VERSION "dbc-export 1 2025.20.8"

NS_ :

BS_:

BU_: ADSP APSB BB BMS CMP CP DAS DI DIF DIR DPB EPASTP EPASTS GTW ICR IDB OCS1P PM PMF PMR PTC RCM RCU TCU UI UIS VCLEFT VCSEC

BO_ 1428 EPASTS_alertLog: 8 EPASTS
 SG_ EPASTS_alertID M : 0|9@1+ (1,0) [0|511] "" Vector__XXX
 SG_ EPASTS_alertState : 15|1@1+ (1,0) [0|1] "" Vector__XXX
 SG_ EPASTS_a001_debugInfo m1 : 16|48@1+ (1,0) [0|281474976710655] "" Vector__XXX
 SG_ EPASTS_a002_debugInfo m2 : 16|48@1+ (1,0) [0|281474976710655] "" Vector__XXX
 SG_ EPASTS_a003_debugInfo m3 : 16|48@1+ (1,0) [0|281474976710655] "" Vector__XXX
 SG_ EPASTS_a004_debugInfo m4 : 16|48@1+ (1,0) [0|281474976710655] "" Vector__XXX
 SG_ EPASTS_a005_debugInfo m5 : 16|48@1+ (1,0) [0|281474976710655] "" Vector__XXX
 SG_ EPASTS_a006_debugInfo m6 : 16|48@1+ (1,0) [0|281474976710655] "" Vector__XXX
 SG_ EPASTS_a007_debugInfo m7 : 16|48@1+ (1,0) [0|281474976710655] "" Vector__XXX
 SG_ EPASTS_a009_debugInfo m9 : 16|48@1+ (1,0) [0|281474976710655] "" Vector__XXX
 SG_ EPASTS_a010_debugInfo m10 : 16|48@1+ (1,0) [0|281474976710655] "" Vector__XXX
 SG_ EPASTS_a011_debugInfo m11 : 16|48@1+ (1,0) [0|281474976710655] "" Vector__XXX
 SG_ EPASTS_a012_debugInfo m12 : 16|48@1+ (1,0) [0|281474976710655] "" Vector__XXX
 SG_ EPASTS_a013_debugInfo m13 : 16|48@1+ (1,0) [0|281474976710655] "" Vector__XXX
 SG_ EPASTS_a014_debugInfo m14 : 16|48@1+ (1,0) [0|281474976710655] "" Vector__XXX
 SG_ EPASTS_a015_debugInfo m15 : 16|48@1+ (1,0) [0|281474976710655] "" Vector__XXX
 SG_ EPASTS_a016_debugInfo m16 : 16|48@1+ (1,0) [0|281474976710655] "" Vector__XXX
 SG_ EPASTS_a017_debugInfo m17 : 16|48@1+ (1,0) [0|281474976710655] "" Vector__XXX
 SG_ EPASTS_a018_debugInfo m18 : 16|48@1+ (1,0) [0|281474976710655] "" Vector__XXX
 SG_ EPASTS_a019_debugInfo m19 : 16|48@1+ (1,0) [0|281474976710655] "" Vector__XXX
 SG_ EPASTS_a020_debugInfo m20 : 16|48@1+ (1,0) [0|281474976710655] "" Vector__XXX
 SG_ EPASTS_a021_debugInfo m21 : 16|48@1+ (1,0) [0|281474976710655] "" Vector__XXX
 SG_ EPASTS_a022_debugInfo m22 : 16|48@1+ (1,0) [0|281474976710655] "" Vector__XXX
 SG_ EPASTS_a023_debugInfo m23 : 16|48@1+ (1,0) [0|281474976710655] "" Vector__XXX
 SG_ EPASTS_a024_debugInfo m24 : 16|48@1+ (1,0) [0|281474976710655] "" Vector__XXX
 SG_ EPASTS_a025_debugInfo m25 : 16|48@1+ (1,0) [0|281474976710655] "" Vector__XXX
 SG_ EPASTS_a026_debugInfo m26 : 16|48@1+ (1,0) [0|281474976710655] "" Vector__XXX
 SG_ EPASTS_a027_debugInfo m27 : 16|48@1+ (1,0) [0|281474976710655] "" Vector__XXX
 SG_ EPASTS_a028_debugInfo m28 : 16|48@1+ (1,0) [0|281474976710655] "" Vector__XXX
 SG_ EPASTS_a029_debugInfo m29 : 16|48@1+ (1,0) [0|281474976710655] "" Vector__XXX
 SG_ EPASTS_a030_debugInfo m30 : 16|48@1+ (1,0) [0|281474976710655] "" Vector__XXX
 SG_ EPASTS_a031_debugInfo m31 : 16|48@1+ (1,0) [0|281474976710655] "" Vector__XXX
 SG_ EPASTS_a032_debugInfo m32 : 16|48@1+ (1,0) [0|281474976710655] "" Vector__XXX
 SG_ EPASTS_a033_debugInfo m33 : 16|48@1+ (1,0) [0|281474976710655] "" Vector__XXX
 SG_ EPASTS_a034_debugInfo m34 : 16|48@1+ (1,0) [0|281474976710655] "" Vector__XXX
 SG_ EPASTS_a035_debugInfo m35 : 16|48@1+ (1,0) [0|281474976710655] "" Vector__XXX
 SG_ EPASTS_a036_debugInfo m36 : 16|48@1+ (1,0) [0|281474976710655] "" Vector__XXX
 SG_ EPASTS_a037_debugInfo m37 : 16|48@1+ (1,0) [0|281474976710655] "" Vector__XXX
 SG_ EPASTS_a038_debugInfo m38 : 16|48@1+ (1,0) [0|281474976710655] "" Vector__XXX
 SG_ EPASTS_a039_debugInfo m39 : 16|48@1+ (1,0) [0|281474976710655] "" Vector__XXX
 SG_ EPASTS_a040_debugInfo m40 : 16|48@1+ (1,0) [0|281474976710655] "" Vector__XXX
 SG_ EPASTS_a041_debugInfo m41 : 16|48@1+ (1,0) [0|281474976710655] "" Vector__XXX
 SG_ EPASTS_a042_debugInfo m42 : 16|48@1+ (1,0) [0|281474976710655] "" Vector__XXX
 SG_ EPASTS_a043_debugInfo m43 : 16|48@1+ (1,0) [0|281474976710655] "" Vector__XXX
 SG_ EPASTS_a044_debugInfo m44 : 16|48@1+ (1,0) [0|281474976710655] "" Vector__XXX
 SG_ EPASTS_a045_debugInfo m45 : 16|48@1+ (1,0) [0|281474976710655] "" Vector__XXX
 SG_ EPASTS_a046_debugInfo m46 : 16|48@1+ (1,0) [0|281474976710655] "" Vector__XXX
 SG_ EPASTS_a047_debugInfo m47 : 16|48@1+ (1,0) [0|281474976710655] "" Vector__XXX
 SG_ EPASTS_a048_debugInfo m48 : 16|48@1+ (1,0) [0|281474976710655] "" Vector__XXX
 SG_ EPASTS_a049_debugInfo m49 : 16|48@1+ (1,0) [0|281474976710655] "" Vector__XXX
 SG_ EPASTS_a050_debugInfo m50 : 16|48@1+ (1,0) [0|281474976710655] "" Vector__XXX
 SG_ EPASTS_a051_debugInfo m51 : 16|48@1+ (1,0) [0|281474976710655] "" Vector__XXX
 SG_ EPASTS_a052_debugInfo m52 : 16|48@1+ (1,0) [0|281474976710655] "" Vector__XXX
 SG_ EPASTS_a053_debugInfo m53 : 16|48@1+ (1,0) [0|281474976710655] "" Vector__XXX
 SG_ EPASTS_a054_debugInfo m54 : 16|48@1+ (1,0) [0|281474976710655] "" Vector__XXX
 SG_ EPASTS_a055_debugInfo m55 : 16|48@1+ (1,0) [0|281474976710655] "" Vector__XXX
 SG_ EPASTS_a056_debugInfo m56 : 16|48@1+ (1,0) [0|281474976710655] "" Vector__XXX
 SG_ EPASTS_a057_debugInfo m57 : 16|48@1+ (1,0) [0|281474976710655] "" Vector__XXX
 SG_ EPASTS_a058_debugInfo m58 : 16|48@1+ (1,0) [0|281474976710655] "" Vector__XXX
 SG_ EPASTS_a059_debugInfo m59 : 16|48@1+ (1,0) [0|281474976710655] "" Vector__XXX
 SG_ EPASTS_a060_debugInfo m60 : 16|48@1+ (1,0) [0|281474976710655] "" Vector__XXX
 SG_ EPASTS_a061_debugInfo m61 : 16|48@1+ (1,0) [0|281474976710655] "" Vector__XXX
 SG_ EPASTS_a062_debugInfo m62 : 16|48@1+ (1,0) [0|281474976710655] "" Vector__XXX
 SG_ EPASTS_a063_debugInfo m63 : 16|48@1+ (1,0) [0|281474976710655] "" Vector__XXX
 SG_ EPASTS_a064_debugInfo m64 : 16|48@1+ (1,0) [0|281474976710655] "" Vector__XXX
 SG_ EPASTS_a065_debugInfo m65 : 16|48@1+ (1,0) [0|281474976710655] "" Vector__XXX
 SG_ EPASTS_a066_debugInfo m66 : 16|48@1+ (1,0) [0|281474976710655] "" Vector__XXX
 SG_ EPASTS_a067_debugInfo m67 : 16|48@1+ (1,0) [0|281474976710655] "" Vector__XXX
 SG_ EPASTS_a068_debugInfo m68 : 16|48@1+ (1,0) [0|281474976710655] "" Vector__XXX
 SG_ EPASTS_a069_debugInfo m69 : 16|48@1+ (1,0) [0|281474976710655] "" Vector__XXX
 SG_ EPASTS_a070_debugInfo m70 : 16|48@1+ (1,0) [0|281474976710655] "" Vector__XXX
 SG_ EPASTS_a071_debugInfo m71 : 16|48@1+ (1,0) [0|281474976710655] "" Vector__XXX
 SG_ EPASTS_a072_debugInfo m72 : 16|48@1+ (1,0) [0|281474976710655] "" Vector__XXX
 SG_ EPASTS_a073_debugInfo m73 : 16|48@1+ (1,0) [0|281474976710655] "" Vector__XXX
 SG_ EPASTS_a074_debugInfo m74 : 16|48@1+ (1,0) [0|281474976710655] "" Vector__XXX
 SG_ EPASTS_a075_debugInfo m75 : 16|48@1+ (1,0) [0|281474976710655] "" Vector__XXX
 SG_ EPASTS_a076_debugInfo m76 : 16|48@1+ (1,0) [0|281474976710655] "" Vector__XXX
 SG_ EPASTS_a077_debugInfo m77 : 16|48@1+ (1,0) [0|281474976710655] "" Vector__XXX
 SG_ EPASTS_a078_debugInfo m78 : 16|48@1+ (1,0) [0|281474976710655] "" Vector__XXX
 SG_ EPASTS_a079_debugInfo m79 : 16|48@1+ (1,0) [0|281474976710655] "" Vector__XXX
 SG_ EPASTS_a080_debugInfo m80 : 16|48@1+ (1,0) [0|281474976710655] "" Vector__XXX
 SG_ EPASTS_a081_debugInfo m81 : 16|48@1+ (1,0) [0|281474976710655] "" Vector__XXX
 SG_ EPASTS_a082_debugInfo m82 : 16|48@1+ (1,0) [0|281474976710655] "" Vector__XXX
 SG_ EPASTS_a083_debugInfo m83 : 16|48@1+ (1,0) [0|281474976710655] "" Vector__XXX
 SG_ EPASTS_a084_debugInfo m84 : 16|48@1+ (1,0) [0|281474976710655] "" Vector__XXX
 SG_ EPASTS_a085_debugInfo m85 : 16|48@1+ (1,0) [0|281474976710655] "" Vector__XXX
 SG_ EPASTS_a086_debugInfo m86 : 16|48@1+ (1,0) [0|281474976710655] "" Vector__XXX
 SG_ EPASTS_a087_debugInfo m87 : 16|48@1+ (1,0) [0|281474976710655] "" Vector__XXX
 SG_ EPASTS_a088_debugInfo m88 : 16|48@1+ (1,0) [0|281474976710655] "" Vector__XXX
 SG_ EPASTS_a089_debugInfo m89 : 16|48@1+ (1,0) [0|281474976710655] "" Vector__XXX
 SG_ EPASTS_a090_debugInfo m90 : 16|48@1+ (1,0) [0|281474976710655] "" Vector__XXX
 SG_ EPASTS_a091_debugInfo m91 : 16|48@1+ (1,0) [0|281474976710655] "" Vector__XXX
 SG_ EPASTS_a092_debugInfo m92 : 16|48@1+ (1,0) [0|281474976710655] "" Vector__XXX
 SG_ EPASTS_a093_debugInfo m93 : 16|48@1+ (1,0) [0|281474976710655] "" Vector__XXX
 SG_ EPASTS_a094_debugInfo m94 : 16|48@1+ (1,0) [0|281474976710655] "" Vector__XXX
 SG_ EPASTS_a095_debugInfo m95 : 16|48@1+ (1,0) [0|281474976710655] "" Vector__XXX
 SG_ EPASTS_a096_debugInfo m96 : 16|48@1+ (1,0) [0|281474976710655] "" Vector__XXX
 SG_ EPASTS_a097_debugInfo m97 : 16|48@1+ (1,0) [0|281474976710655] "" Vector__XXX
 SG_ EPASTS_a098_debugInfo m98 : 16|48@1+ (1,0) [0|281474976710655] "" Vector__XXX
 SG_ EPASTS_a099_debugInfo m99 : 16|48@1+ (1,0) [0|281474976710655] "" Vector__XXX
 SG_ EPASTS_a100_debugInfo m100 : 16|48@1+ (1,0) [0|281474976710655] "" Vector__XXX
 SG_ EPASTS_a101_debugInfo m101 : 16|48@1+ (1,0) [0|281474976710655] "" Vector__XXX
 SG_ EPASTS_a102_debugInfo m102 : 16|48@1+ (1,0) [0|281474976710655] "" Vector__XXX
 SG_ EPASTS_a103_debugInfo m103 : 16|48@1+ (1,0) [0|281474976710655] "" Vector__XXX
 SG_ EPASTS_a104_debugInfo m104 : 16|48@1+ (1,0) [0|281474976710655] "" Vector__XXX
 SG_ EPASTS_a105_debugInfo m105 : 16|48@1+ (1,0) [0|281474976710655] "" Vector__XXX
 SG_ EPASTS_a106_debugInfo m106 : 16|48@1+ (1,0) [0|281474976710655] "" Vector__XXX
 SG_ EPASTS_a107_debugInfo m107 : 16|48@1+ (1,0) [0|281474976710655] "" Vector__XXX
 SG_ EPASTS_a108_debugInfo m108 : 16|48@1+ (1,0) [0|281474976710655] "" Vector__XXX
 SG_ EPASTS_a109_debugInfo m109 : 16|48@1+ (1,0) [0|281474976710655] "" Vector__XXX
 SG_ EPASTS_a110_debugInfo m110 : 16|48@1+ (1,0) [0|281474976710655] "" Vector__XXX
 SG_ EPASTS_a111_debugInfo m111 : 16|48@1+ (1,0) [0|281474976710655] "" Vector__XXX
 SG_ EPASTS_a112_debugInfo m112 : 16|48@1+ (1,0) [0|281474976710655] "" Vector__XXX
 SG_ EPASTS_a113_debugInfo m113 : 16|48@1+ (1,0) [0|281474976710655] "" Vector__XXX
 SG_ EPASTS_a114_debugInfo m114 : 16|48@1+ (1,0) [0|281474976710655] "" Vector__XXX
 SG_ EPASTS_a115_debugInfo m115 : 16|48@1+ (1,0) [0|281474976710655] "" Vector__XXX
 SG_ EPASTS_a116_debugInfo m116 : 16|48@1+ (1,0) [0|281474976710655] "" Vector__XXX
 SG_ EPASTS_a117_debugInfo m117 : 16|48@1+ (1,0) [0|281474976710655] "" Vector__XXX
 SG_ EPASTS_a118_debugInfo m118 : 16|48@1+ (1,0) [0|281474976710655] "" Vector__XXX
 SG_ EPASTS_a119_debugInfo m119 : 16|48@1+ (1,0) [0|281474976710655] "" Vector__XXX
 SG_ EPASTS_a120_debugInfo m120 : 16|48@1+ (1,0) [0|281474976710655] "" Vector__XXX
 SG_ EPASTS_a121_debugInfo m121 : 16|48@1+ (1,0) [0|281474976710655] "" Vector__XXX
 SG_ EPASTS_a122_debugInfo m122 : 16|48@1+ (1,0) [0|281474976710655] "" Vector__XXX
 SG_ EPASTS_a123_debugInfo m123 : 16|48@1+ (1,0) [0|281474976710655] "" Vector__XXX
 SG_ EPASTS_a124_debugInfo m124 : 16|48@1+ (1,0) [0|281474976710655] "" Vector__XXX
 SG_ EPASTS_a125_debugInfo m125 : 16|48@1+ (1,0) [0|281474976710655] "" Vector__XXX
 SG_ EPASTS_a126_debugInfo m126 : 16|48@1+ (1,0) [0|281474976710655] "" Vector__XXX
 SG_ EPASTS_a127_debugInfo m127 : 16|48@1+ (1,0) [0|281474976710655] "" Vector__XXX
 SG_ EPASTS_a128_debugInfo m128 : 16|48@1+ (1,0) [0|281474976710655] "" Vector__XXX
 SG_ EPASTS_a129_debugInfo m129 : 16|48@1+ (1,0) [0|281474976710655] "" Vector__XXX
 SG_ EPASTS_a130_debugInfo m130 : 16|48@1+ (1,0) [0|281474976710655] "" Vector__XXX
 SG_ EPASTS_a131_debugInfo m131 : 16|48@1+ (1,0) [0|281474976710655] "" Vector__XXX
 SG_ EPASTS_a132_debugInfo m132 : 16|48@1+ (1,0) [0|281474976710655] "" Vector__XXX
 SG_ EPASTS_a133_debugInfo m133 : 16|48@1+ (1,0) [0|281474976710655] "" Vector__XXX
 SG_ EPASTS_a134_debugInfo m134 : 16|48@1+ (1,0) [0|281474976710655] "" Vector__XXX
 SG_ EPASTS_a135_debugInfo m135 : 16|48@1+ (1,0) [0|281474976710655] "" Vector__XXX
 SG_ EPASTS_a136_debugInfo m136 : 16|48@1+ (1,0) [0|281474976710655] "" Vector__XXX
 SG_ EPASTS_a137_debugInfo m137 : 16|48@1+ (1,0) [0|281474976710655] "" Vector__XXX
 SG_ EPASTS_a138_debugInfo m138 : 16|48@1+ (1,0) [0|281474976710655] "" Vector__XXX
 SG_ EPASTS_a139_debugInfo m139 : 16|48@1+ (1,0) [0|281474976710655] "" Vector__XXX
 SG_ EPASTS_a140_debugInfo m140 : 16|48@1+ (1,0) [0|281474976710655] "" Vector__XXX
 SG_ EPASTS_a141_debugInfo m141 : 16|48@1+ (1,0) [0|281474976710655] "" Vector__XXX
 SG_ EPASTS_a142_debugInfo m142 : 16|48@1+ (1,0) [0|281474976710655] "" Vector__XXX
 SG_ EPASTS_a143_debugInfo m143 : 16|48@1+ (1,0) [0|281474976710655] "" Vector__XXX
 SG_ EPASTS_a144_debugInfo m144 : 16|48@1+ (1,0) [0|281474976710655] "" Vector__XXX
 SG_ EPASTS_a145_debugInfo m145 : 16|48@1+ (1,0) [0|281474976710655] "" Vector__XXX
 SG_ EPASTS_a146_debugInfo m146 : 16|48@1+ (1,0) [0|281474976710655] "" Vector__XXX
 SG_ EPASTS_a147_debugInfo m147 : 16|48@1+ (1,0) [0|281474976710655] "" Vector__XXX
 SG_ EPASTS_a148_debugInfo m148 : 16|48@1+ (1,0) [0|281474976710655] "" Vector__XXX
 SG_ EPASTS_a149_debugInfo m149 : 16|48@1+ (1,0) [0|281474976710655] "" Vector__XXX
 SG_ EPASTS_a150_debugInfo m150 : 16|48@1+ (1,0) [0|281474976710655] "" Vector__XXX
 SG_ EPASTS_a152_debugInfo m152 : 16|48@1+ (1,0) [0|281474976710655] "" Vector__XXX
 SG_ EPASTS_a153_debugInfo m153 : 16|48@1+ (1,0) [0|281474976710655] "" Vector__XXX
 SG_ EPASTS_a154_debugInfo m154 : 16|48@1+ (1,0) [0|281474976710655] "" Vector__XXX
 SG_ EPASTS_a155_debugInfo m155 : 16|48@1+ (1,0) [0|281474976710655] "" Vector__XXX
 SG_ EPASTS_a156_debugInfo m156 : 16|48@1+ (1,0) [0|281474976710655] "" Vector__XXX
 SG_ EPASTS_a157_debugInfo m157 : 16|48@1+ (1,0) [0|281474976710655] "" Vector__XXX
 SG_ EPASTS_a158_debugInfo m158 : 16|48@1+ (1,0) [0|281474976710655] "" Vector__XXX
 SG_ EPASTS_a159_debugInfo m159 : 16|48@1+ (1,0) [0|281474976710655] "" Vector__XXX
 SG_ EPASTS_a160_debugInfo m160 : 16|48@1+ (1,0) [0|281474976710655] "" Vector__XXX
 SG_ EPASTS_a161_debugInfo m161 : 16|48@1+ (1,0) [0|281474976710655] "" Vector__XXX
 SG_ EPASTS_a162_debugInfo m162 : 16|48@1+ (1,0) [0|281474976710655] "" Vector__XXX
 SG_ EPASTS_a163_debugInfo m163 : 16|48@1+ (1,0) [0|281474976710655] "" Vector__XXX
 SG_ EPASTS_a164_debugInfo m164 : 16|48@1+ (1,0) [0|281474976710655] "" Vector__XXX
 SG_ EPASTS_a165_debugInfo m165 : 16|48@1+ (1,0) [0|281474976710655] "" Vector__XXX
 SG_ EPASTS_a166_debugInfo m166 : 16|48@1+ (1,0) [0|281474976710655] "" Vector__XXX
 SG_ EPASTS_a167_debugInfo m167 : 16|48@1+ (1,0) [0|281474976710655] "" Vector__XXX
 SG_ EPASTS_a168_debugInfo m168 : 16|48@1+ (1,0) [0|281474976710655] "" Vector__XXX
 SG_ EPASTS_a169_debugInfo m169 : 16|48@1+ (1,0) [0|281474976710655] "" Vector__XXX
 SG_ EPASTS_a170_debugInfo m170 : 16|48@1+ (1,0) [0|281474976710655] "" Vector__XXX
 SG_ EPASTS_a171_debugInfo m171 : 16|48@1+ (1,0) [0|281474976710655] "" Vector__XXX
 SG_ EPASTS_a172_debugInfo m172 : 16|48@1+ (1,0) [0|281474976710655] "" Vector__XXX
 SG_ EPASTS_a173_debugInfo m173 : 16|48@1+ (1,0) [0|281474976710655] "" Vector__XXX
 SG_ EPASTS_a174_debugInfo m174 : 16|48@1+ (1,0) [0|281474976710655] "" Vector__XXX
 SG_ EPASTS_a175_debugInfo m175 : 16|48@1+ (1,0) [0|281474976710655] "" Vector__XXX
 SG_ EPASTS_a176_debugInfo m176 : 16|48@1+ (1,0) [0|281474976710655] "" Vector__XXX
 SG_ EPASTS_a177_debugInfo m177 : 16|48@1+ (1,0) [0|281474976710655] "" Vector__XXX
 SG_ EPASTS_a178_debugInfo m178 : 16|48@1+ (1,0) [0|281474976710655] "" Vector__XXX
 SG_ EPASTS_a179_debugInfo m179 : 16|48@1+ (1,0) [0|281474976710655] "" Vector__XXX
 SG_ EPASTS_a180_debugInfo m180 : 16|48@1+ (1,0) [0|281474976710655] "" Vector__XXX
 SG_ EPASTS_a181_debugInfo m181 : 16|48@1+ (1,0) [0|281474976710655] "" Vector__XXX
 SG_ EPASTS_a182_debugInfo m182 : 16|48@1+ (1,0) [0|281474976710655] "" Vector__XXX
 SG_ EPASTS_a183_debugInfo m183 : 16|48@1+ (1,0) [0|281474976710655] "" Vector__XXX
 SG_ EPASTS_a184_debugInfo m184 : 16|48@1+ (1,0) [0|281474976710655] "" Vector__XXX
 SG_ EPASTS_a185_debugInfo m185 : 16|48@1+ (1,0) [0|281474976710655] "" Vector__XXX
 SG_ EPASTS_a186_debugInfo m186 : 16|48@1+ (1,0) [0|281474976710655] "" Vector__XXX
 SG_ EPASTS_a188_debugInfo m188 : 16|48@1+ (1,0) [0|281474976710655] "" Vector__XXX
 SG_ EPASTS_a189_debugInfo m189 : 16|48@1+ (1,0) [0|281474976710655] "" Vector__XXX
 SG_ EPASTS_a190_debugInfo m190 : 16|48@1+ (1,0) [0|281474976710655] "" Vector__XXX
 SG_ EPASTS_a191_debugInfo m191 : 16|48@1+ (1,0) [0|281474976710655] "" Vector__XXX
 SG_ EPASTS_a192_debugInfo m192 : 16|48@1+ (1,0) [0|281474976710655] "" Vector__XXX
 SG_ EPASTS_a193_debugInfo m193 : 16|48@1+ (1,0) [0|281474976710655] "" Vector__XXX
 SG_ EPASTS_a194_debugInfo m194 : 16|48@1+ (1,0) [0|281474976710655] "" Vector__XXX
 SG_ EPASTS_a195_debugInfo m195 : 16|48@1+ (1,0) [0|281474976710655] "" Vector__XXX
 SG_ EPASTS_a196_debugInfo m196 : 16|48@1+ (1,0) [0|281474976710655] "" Vector__XXX
 SG_ EPASTS_a197_debugInfo m197 : 16|48@1+ (1,0) [0|281474976710655] "" Vector__XXX
 SG_ EPASTS_a198_debugInfo m198 : 16|48@1+ (1,0) [0|281474976710655] "" Vector__XXX
 SG_ EPASTS_a199_debugInfo m199 : 16|48@1+ (1,0) [0|281474976710655] "" Vector__XXX
 SG_ EPASTS_a200_debugInfo m200 : 16|48@1+ (1,0) [0|281474976710655] "" Vector__XXX
 SG_ EPASTS_a201_debugInfo m201 : 16|48@1+ (1,0) [0|281474976710655] "" Vector__XXX
 SG_ EPASTS_a202_debugInfo m202 : 16|48@1+ (1,0) [0|281474976710655] "" Vector__XXX
 SG_ EPASTS_a203_debugInfo m203 : 16|48@1+ (1,0) [0|281474976710655] "" Vector__XXX
 SG_ EPASTS_a204_debugInfo m204 : 16|48@1+ (1,0) [0|281474976710655] "" Vector__XXX
 SG_ EPASTS_a205_debugInfo m205 : 16|48@1+ (1,0) [0|281474976710655] "" Vector__XXX
 SG_ EPASTS_a206_debugInfo m206 : 16|48@1+ (1,0) [0|281474976710655] "" Vector__XXX
 SG_ EPASTS_a207_debugInfo m207 : 16|48@1+ (1,0) [0|281474976710655] "" Vector__XXX
 SG_ EPASTS_a208_debugInfo m208 : 16|48@1+ (1,0) [0|281474976710655] "" Vector__XXX
 SG_ EPASTS_a209_debugInfo m209 : 16|48@1+ (1,0) [0|281474976710655] "" Vector__XXX
 SG_ EPASTS_a210_debugInfo m210 : 16|48@1+ (1,0) [0|281474976710655] "" Vector__XXX
 SG_ EPASTS_a211_debugInfo m211 : 16|48@1+ (1,0) [0|281474976710655] "" Vector__XXX
 SG_ EPASTS_a212_debugInfo m212 : 16|48@1+ (1,0) [0|281474976710655] "" Vector__XXX
 SG_ EPASTS_a213_debugInfo m213 : 16|48@1+ (1,0) [0|281474976710655] "" Vector__XXX
 SG_ EPASTS_a214_debugInfo m214 : 16|48@1+ (1,0) [0|281474976710655] "" Vector__XXX
 SG_ EPASTS_a215_debugInfo m215 : 16|48@1+ (1,0) [0|281474976710655] "" Vector__XXX
 SG_ EPASTS_a216_debugInfo m216 : 16|48@1+ (1,0) [0|281474976710655] "" Vector__XXX
 SG_ EPASTS_a217_debugInfo m217 : 16|48@1+ (1,0) [0|281474976710655] "" Vector__XXX
 SG_ EPASTS_a218_debugInfo m218 : 16|48@1+ (1,0) [0|281474976710655] "" Vector__XXX
 SG_ EPASTS_a219_debugInfo m219 : 16|48@1+ (1,0) [0|281474976710655] "" Vector__XXX
 SG_ EPASTS_a220_debugInfo m220 : 16|48@1+ (1,0) [0|281474976710655] "" Vector__XXX
 SG_ EPASTS_a221_debugInfo m221 : 16|48@1+ (1,0) [0|281474976710655] "" Vector__XXX
 SG_ EPASTS_a222_debugInfo m222 : 16|48@1+ (1,0) [0|281474976710655] "" Vector__XXX
 SG_ EPASTS_a223_debugInfo m223 : 16|48@1+ (1,0) [0|281474976710655] "" Vector__XXX
 SG_ EPASTS_a224_debugInfo m224 : 16|48@1+ (1,0) [0|281474976710655] "" Vector__XXX
 SG_ EPASTS_a225_debugInfo m225 : 16|48@1+ (1,0) [0|281474976710655] "" Vector__XXX
 SG_ EPASTS_a226_debugInfo m226 : 16|48@1+ (1,0) [0|281474976710655] "" Vector__XXX
 SG_ EPASTS_a227_debugInfo m227 : 16|48@1+ (1,0) [0|281474976710655] "" Vector__XXX
 SG_ EPASTS_a228_debugInfo m228 : 16|48@1+ (1,0) [0|281474976710655] "" Vector__XXX
 SG_ EPASTS_a229_debugInfo m229 : 16|48@1+ (1,0) [0|281474976710655] "" Vector__XXX
 SG_ EPASTS_a230_debugInfo m230 : 16|48@1+ (1,0) [0|281474976710655] "" Vector__XXX
 SG_ EPASTS_a231_debugInfo m231 : 16|48@1+ (1,0) [0|281474976710655] "" Vector__XXX
 SG_ EPASTS_a232_debugInfo m232 : 16|48@1+ (1,0) [0|281474976710655] "" Vector__XXX
 SG_ EPASTS_a233_debugInfo m233 : 16|48@1+ (1,0) [0|281474976710655] "" Vector__XXX
 SG_ EPASTS_a234_debugInfo m234 : 16|48@1+ (1,0) [0|281474976710655] "" Vector__XXX
 SG_ EPASTS_a235_debugInfo m235 : 16|48@1+ (1,0) [0|281474976710655] "" Vector__XXX
 SG_ EPASTS_a236_debugInfo m236 : 16|48@1+ (1,0) [0|281474976710655] "" Vector__XXX
 SG_ EPASTS_a237_debugInfo m237 : 16|48@1+ (1,0) [0|281474976710655] "" Vector__XXX
 SG_ EPASTS_a238_debugInfo m238 : 16|48@1+ (1,0) [0|281474976710655] "" Vector__XXX
 SG_ EPASTS_a239_debugInfo m239 : 16|48@1+ (1,0) [0|281474976710655] "" Vector__XXX
 SG_ EPASTS_a240_debugInfo m240 : 16|48@1+ (1,0) [0|281474976710655] "" Vector__XXX
 SG_ EPASTS_a241_debugInfo m241 : 16|48@1+ (1,0) [0|281474976710655] "" Vector__XXX
 SG_ EPASTS_a242_debugInfo m242 : 16|48@1+ (1,0) [0|281474976710655] "" Vector__XXX
 SG_ EPASTS_a243_debugInfo m243 : 16|48@1+ (1,0) [0|281474976710655] "" Vector__XXX
 SG_ EPASTS_a244_debugInfo m244 : 16|48@1+ (1,0) [0|281474976710655] "" Vector__XXX
 SG_ EPASTS_a245_debugInfo m245 : 16|48@1+ (1,0) [0|281474976710655] "" Vector__XXX
 SG_ EPASTS_a246_debugInfo m246 : 16|48@1+ (1,0) [0|281474976710655] "" Vector__XXX
 SG_ EPASTS_a247_debugInfo m247 : 16|48@1+ (1,0) [0|281474976710655] "" Vector__XXX
 SG_ EPASTS_a248_debugInfo m248 : 16|48@1+ (1,0) [0|281474976710655] "" Vector__XXX
 SG_ EPASTS_a249_debugInfo m249 : 16|48@1+ (1,0) [0|281474976710655] "" Vector__XXX
 SG_ EPASTS_a250_debugInfo m250 : 16|48@1+ (1,0) [0|281474976710655] "" Vector__XXX
 SG_ EPASTS_a251_debugInfo m251 : 16|48@1+ (1,0) [0|281474976710655] "" Vector__XXX
 SG_ EPASTS_a252_debugInfo m252 : 16|48@1+ (1,0) [0|281474976710655] "" Vector__XXX
 SG_ EPASTS_a253_debugInfo m253 : 16|48@1+ (1,0) [0|281474976710655] "" Vector__XXX
 SG_ EPASTS_a254_debugInfo m254 : 16|48@1+ (1,0) [0|281474976710655] "" Vector__XXX
 SG_ EPASTS_a255_debugInfo m255 : 16|48@1+ (1,0) [0|281474976710655] "" Vector__XXX
 SG_ EPASTS_a256_debugInfo m256 : 16|48@1+ (1,0) [0|281474976710655] "" Vector__XXX
 SG_ EPASTS_a257_debugInfo m257 : 16|48@1+ (1,0) [0|281474976710655] "" Vector__XXX
 SG_ EPASTS_a258_debugInfo m258 : 16|48@1+ (1,0) [0|281474976710655] "" Vector__XXX
 SG_ EPASTS_a259_debugInfo m259 : 16|48@1+ (1,0) [0|281474976710655] "" Vector__XXX
 SG_ EPASTS_a260_debugInfo m260 : 16|48@1+ (1,0) [0|281474976710655] "" Vector__XXX
 SG_ EPASTS_a261_debugInfo m261 : 16|48@1+ (1,0) [0|281474976710655] "" Vector__XXX
 SG_ EPASTS_a262_debugInfo m262 : 16|48@1+ (1,0) [0|281474976710655] "" Vector__XXX
 SG_ EPASTS_a263_debugInfo m263 : 16|48@1+ (1,0) [0|281474976710655] "" Vector__XXX
 SG_ EPASTS_a264_degradedECU m264 : 16|8@1+ (1,0) [0|255] "" Vector__XXX
 SG_ EPASTS_a264_vehicleSpeed m264 : 24|16@1+ (0.1,0) [0|6553.5] "kph" Vector__XXX
 SG_ EPASTS_a264_powerRatio m264 : 40|8@1+ (1,0) [0|255] "percent" Vector__XXX
 SG_ EPASTS_a264_ownSideDegradationRe m264 : 48|8@1+ (1,0) [0|255] "" Vector__XXX
 SG_ EPASTS_a264_otherSideDegradation m264 : 56|8@1+ (1,0) [0|255] "" Vector__XXX
 SG_ EPASTS_a265_degradedECU m265 : 16|8@1+ (1,0) [0|255] "" Vector__XXX
 SG_ EPASTS_a265_vehicleSpeed m265 : 24|16@1+ (0.1,0) [0|6553.5] "kph" Vector__XXX
 SG_ EPASTS_a265_rawMcuTemperature m265 : 40|16@1+ (1,-100) [-100|65435] "C" Vector__XXX
 SG_ EPASTS_a265_degradedCurrentLimit m265 : 56|8@1+ (1,0) [0|255] "A" Vector__XXX
 SG_ EPASTS_a266_cdpAssistFactor m266 : 16|8@1+ (1,0) [0|255] "percent" Vector__XXX
 SG_ EPASTS_a266_vehicleSpeed m266 : 24|16@1+ (0.1,0) [0|6553.5] "kph" Vector__XXX
 SG_ EPASTS_a267_vehicleSpeed m267 : 16|16@1+ (0.1,0) [0|6553.5] "kph" Vector__XXX
 SG_ EPASTS_a267_velocityEstimatorSta m267 : 32|8@1+ (1,0) [0|255] "" Vector__XXX
 SG_ EPASTS_a269_vehicleSpeed m269 : 16|16@1+ (0.1,0) [0|6553.5] "kph" Vector__XXX
 SG_ EPASTS_a270_debugInfo m270 : 16|48@1+ (1,0) [0|281474976710655] "" Vector__XXX

BO_ 920 EPASTS_alertMatrix: 8 EPASTS
 SG_ EPASTS_matrixIndex M : 0|4@1+ (1,0) [0|15] "" Vector__XXX
 SG_ EPASTS_a001_adcCalibrationOrInit m0 : 4|1@1+ (1,0) [0|1] "" Vector__XXX
 SG_ EPASTS_a002_adcMuxErr m0 : 5|1@1+ (1,0) [0|1] "" Vector__XXX
 SG_ EPASTS_a003_pspInvalidParamset m0 : 6|1@1+ (1,0) [0|1] "" Vector__XXX
 SG_ EPASTS_a004_scpInputMia m0 : 7|1@1+ (1,0) [0|1] "" Vector__XXX
 SG_ EPASTS_a005_scpUnknownResetSourc m0 : 8|1@1+ (1,0) [0|1] "" Vector__XXX
 SG_ EPASTS_a006_swrhResetByInvalidEr m0 : 9|1@1+ (1,0) [0|1] "" Vector__XXX
 SG_ EPASTS_a007_tsmcCoreTempDiff m0 : 10|1@1+ (1,0) [0|1] "" Vector__XXX
 SG_ EPASTS_a008_psdcPlatformShutdown m0 : 11|1@1+ (1,0) [0|1] "" Vector__XXX
 SG_ EPASTS_a009_mcusscLbistPermanent m0 : 12|1@1+ (1,0) [0|1] "" Vector__XXX
 SG_ EPASTS_a010_svcIncompatibleSwVer m0 : 13|1@1+ (1,0) [0|1] "" Vector__XXX
 SG_ EPASTS_a011_mcusscMonbistErr m0 : 14|1@1+ (1,0) [0|1] "" Vector__XXX
 SG_ EPASTS_a012_mcusscMbistEccErr m0 : 15|1@1+ (1,0) [0|1] "" Vector__XXX
 SG_ EPASTS_a013_mcusscSffMonitoringF m0 : 16|1@1+ (1,0) [0|1] "" Vector__XXX
 SG_ EPASTS_a014_mcusscSffMonitoringM m0 : 17|1@1+ (1,0) [0|1] "" Vector__XXX
 SG_ EPASTS_a015_mcusscCsErrorCheckFa m0 : 18|1@1+ (1,0) [0|1] "" Vector__XXX
 SG_ EPASTS_a016_mcufcCsErrorCheckFai m0 : 19|1@1+ (1,0) [0|1] "" Vector__XXX
 SG_ EPASTS_a017_stmdStmPlausibilityC m0 : 20|1@1+ (1,0) [0|1] "" Vector__XXX
 SG_ EPASTS_a018_exchCsErrorCheck m0 : 21|1@1+ (1,0) [0|1] "" Vector__XXX
 SG_ EPASTS_a019_rsthHwResetInfoCorru m0 : 22|1@1+ (1,0) [0|1] "" Vector__XXX
 SG_ EPASTS_a020_mcusscEolEcuIdIntegr m0 : 23|1@1+ (1,0) [0|1] "" Vector__XXX
 SG_ EPASTS_a021_osehCsErrorCheck m0 : 24|1@1+ (1,0) [0|1] "" Vector__XXX
 SG_ EPASTS_a022_swrhSwResetInfoCorru m0 : 25|1@1+ (1,0) [0|1] "" Vector__XXX
 SG_ EPASTS_a023_btarcCorruptionCheck m0 : 26|1@1+ (1,0) [0|1] "" Vector__XXX
 SG_ EPASTS_a024_srhCsErrorCheckFail m0 : 27|1@1+ (1,0) [0|1] "" Vector__XXX
 SG_ EPASTS_a025_btarcCorruptionCheck m0 : 28|1@1+ (1,0) [0|1] "" Vector__XXX
 SG_ EPASTS_a026_mrccCsErrorCheckFail m0 : 29|1@1+ (1,0) [0|1] "" Vector__XXX
 SG_ EPASTS_a027_mcusscDmuHfErr m0 : 30|1@1+ (1,0) [0|1] "" Vector__XXX
 SG_ EPASTS_a028_smuhNonInitDataCorru m0 : 31|1@1+ (1,0) [0|1] "" Vector__XXX
 SG_ EPASTS_a029_smuhSmuCoreCntErrorT m0 : 32|1@1+ (1,0) [0|1] "" Vector__XXX
 SG_ EPASTS_a030_rsthClockReset m0 : 33|1@1+ (1,0) [0|1] "" Vector__XXX
 SG_ EPASTS_a031_pmsProductionModeFai m0 : 34|1@1+ (1,0) [0|1] "" Vector__XXX
 SG_ EPASTS_a032_eolpEolCheckFailed m0 : 35|1@1+ (1,0) [0|1] "" Vector__XXX
 SG_ EPASTS_a033_icsvcPswVersionMisma m0 : 36|1@1+ (1,0) [0|1] "" Vector__XXX
 SG_ EPASTS_a034_sbchReadbackRegFail m0 : 37|1@1+ (1,0) [0|1] "" Vector__XXX
 SG_ EPASTS_a035_sbchChipIdFail m0 : 38|1@1+ (1,0) [0|1] "" Vector__XXX
 SG_ EPASTS_a036_sbcmSbcBistFailed m0 : 39|1@1+ (1,0) [0|1] "" Vector__XXX
 SG_ EPASTS_a037_epmV5P2Fail m0 : 40|1@1+ (1,0) [0|1] "" Vector__XXX
 SG_ EPASTS_a038_csohCh1CsErrorErrAtR m0 : 41|1@1+ (1,0) [0|1] "" Vector__XXX
 SG_ EPASTS_a039_csohCh2CsErrorErrAtR m0 : 42|1@1+ (1,0) [0|1] "" Vector__XXX
 SG_ EPASTS_a040_swrhLimitedResetRetr m0 : 43|1@1+ (1,0) [0|1] "" Vector__XXX
 SG_ EPASTS_a041_imcmCoreConfiguratio m0 : 44|1@1+ (1,0) [0|1] "" Vector__XXX
 SG_ EPASTS_a042_wdhWdTestFail m0 : 45|1@1+ (1,0) [0|1] "" Vector__XXX
 SG_ EPASTS_a043_sbcmWdStateDisabled m0 : 46|1@1+ (1,0) [0|1] "" Vector__XXX
 SG_ EPASTS_a044_sbcmSbcEepromFail m0 : 47|1@1+ (1,0) [0|1] "" Vector__XXX
 SG_ EPASTS_a045_psumSbcBandgapVoltEr m0 : 48|1@1+ (1,0) [0|1] "" Vector__XXX
 SG_ EPASTS_a046_mcusscOscillatorNotR m0 : 49|1@1+ (1,0) [0|1] "" Vector__XXX
 SG_ EPASTS_a047_epmVregVoltFail m0 : 50|1@1+ (1,0) [0|1] "" Vector__XXX
 SG_ EPASTS_a048_epmVcpVoltFail m0 : 51|1@1+ (1,0) [0|1] "" Vector__XXX
 SG_ EPASTS_a049_epmLgFail m0 : 52|1@1+ (1,0) [0|1] "" Vector__XXX
 SG_ EPASTS_a050_erlErr m0 : 53|1@1+ (1,0) [0|1] "" Vector__XXX
 SG_ EPASTS_a051_ermMessageErr m0 : 54|1@1+ (1,0) [0|1] "" Vector__XXX
 SG_ EPASTS_a052_ermSdcInputBufferOve m0 : 55|1@1+ (1,0) [0|1] "" Vector__XXX
 SG_ EPASTS_a053_adcUnexpectedNumOfDa m0 : 56|1@1+ (1,0) [0|1] "" Vector__XXX
 SG_ EPASTS_a054_adcUnexpectedData m0 : 57|1@1+ (1,0) [0|1] "" Vector__XXX
 SG_ EPASTS_a055_amExtendedGduTest m0 : 58|1@1+ (1,0) [0|1] "" Vector__XXX
 SG_ EPASTS_a056_amGduConfigCsErrorCh m0 : 59|1@1+ (1,0) [0|1] "" Vector__XXX
 SG_ EPASTS_a057_amGduVds m0 : 60|1@1+ (1,0) [0|1] "" Vector__XXX
 SG_ EPASTS_a058_amIntVgsUndervtgErr m0 : 61|1@1+ (1,0) [0|1] "" Vector__XXX
 SG_ EPASTS_a059_amStartupTestFailed m0 : 62|1@1+ (1,0) [0|1] "" Vector__XXX
 SG_ EPASTS_a060_amGduFail m0 : 63|1@1+ (1,0) [0|1] "" Vector__XXX
 SG_ EPASTS_a061_amIntSerialErr m1 : 4|1@1+ (1,0) [0|1] "" Vector__XXX
 SG_ EPASTS_a062_amPhaseBridgeCheck m1 : 5|1@1+ (1,0) [0|1] "" Vector__XXX
 SG_ EPASTS_a063_amIntRegulatorErr m1 : 6|1@1+ (1,0) [0|1] "" Vector__XXX
 SG_ EPASTS_a064_amBridgeShort m1 : 7|1@1+ (1,0) [0|1] "" Vector__XXX
 SG_ EPASTS_a065_amGduJuncTemp m1 : 8|1@1+ (1,0) [0|1] "" Vector__XXX
 SG_ EPASTS_a066_amVoltQfErr m1 : 9|1@1+ (1,0) [0|1] "" Vector__XXX
 SG_ EPASTS_a067_tspmPowermoduleTempI m1 : 10|1@1+ (1,0) [0|1] "" Vector__XXX
 SG_ EPASTS_a068_rsthCoreRedundancyEr m1 : 11|1@1+ (1,0) [0|1] "" Vector__XXX
 SG_ EPASTS_a069_rsthCoreTempOutOfRan m1 : 12|1@1+ (1,0) [0|1] "" Vector__XXX
 SG_ EPASTS_a070_rsthInternalLowVolt m1 : 13|1@1+ (1,0) [0|1] "" Vector__XXX
 SG_ EPASTS_a071_rsthInternalHighVolt m1 : 14|1@1+ (1,0) [0|1] "" Vector__XXX
 SG_ EPASTS_a072_rsthFlashUncorrEccOr m1 : 15|1@1+ (1,0) [0|1] "" Vector__XXX
 SG_ EPASTS_a073_rsthOtherEdcEcc m1 : 16|1@1+ (1,0) [0|1] "" Vector__XXX
 SG_ EPASTS_a074_rsthUnexpectedAlarm m1 : 17|1@1+ (1,0) [0|1] "" Vector__XXX
 SG_ EPASTS_a075_rsthUnusedOtherModul m1 : 18|1@1+ (1,0) [0|1] "" Vector__XXX
 SG_ EPASTS_a076_exchGeneralException m1 : 19|1@1+ (1,0) [0|1] "" Vector__XXX
 SG_ EPASTS_a077_dmDeadlineViolation m1 : 20|1@1+ (1,0) [0|1] "" Vector__XXX
 SG_ EPASTS_a078_dmDeadlineViolation m1 : 21|1@1+ (1,0) [0|1] "" Vector__XXX
 SG_ EPASTS_a079_gduhComErr m1 : 22|1@1+ (1,0) [0|1] "" Vector__XXX
 SG_ EPASTS_a080_pwmTimerSyncCheck m1 : 23|1@1+ (1,0) [0|1] "" Vector__XXX
 SG_ EPASTS_a081_exchFloatingPointExc m1 : 24|1@1+ (1,0) [0|1] "" Vector__XXX
 SG_ EPASTS_a082_adcTriggerTimeChk m1 : 25|1@1+ (1,0) [0|1] "" Vector__XXX
 SG_ EPASTS_a083_tdaDclinkcapacitorTe m1 : 26|1@1+ (1,0) [0|1] "" Vector__XXX
 SG_ EPASTS_a084_adcTriggerCheck m1 : 27|1@1+ (1,0) [0|1] "" Vector__XXX
 SG_ EPASTS_a085_amGduSwitchOffTestBy m1 : 28|1@1+ (1,0) [0|1] "" Vector__XXX
 SG_ EPASTS_a086_rsthRamUncorrEcc m1 : 29|1@1+ (1,0) [0|1] "" Vector__XXX
 SG_ EPASTS_a087_rsthFlashConfigErr m1 : 30|1@1+ (1,0) [0|1] "" Vector__XXX
 SG_ EPASTS_a088_tedMainboardTempChec m1 : 31|1@1+ (1,0) [0|1] "" Vector__XXX
 SG_ EPASTS_a089_tedRevercebattfetjun m1 : 32|1@1+ (1,0) [0|1] "" Vector__XXX
 SG_ EPASTS_a090_etsmWarning m1 : 33|1@1+ (1,0) [0|1] "" Vector__XXX
 SG_ EPASTS_a091_bvpBattVoltCrossChkF m1 : 34|1@1+ (1,0) [0|1] "" Vector__XXX
 SG_ EPASTS_a092_amGduSwitchOffTestBy m1 : 35|1@1+ (1,0) [0|1] "" Vector__XXX
 SG_ EPASTS_a093_sctpTsuSingleStaticF m1 : 36|1@1+ (1,0) [0|1] "" Vector__XXX
 SG_ EPASTS_a094_sctpTsuMultipleStati m1 : 37|1@1+ (1,0) [0|1] "" Vector__XXX
 SG_ EPASTS_a095_mdModelBasedMotorInt m1 : 38|1@1+ (1,0) [0|1] "" Vector__XXX
 SG_ EPASTS_a096_rppRpsSingleStaticFa m1 : 39|1@1+ (1,0) [0|1] "" Vector__XXX
 SG_ EPASTS_a097_rppRpsMultipleStatic m1 : 40|1@1+ (1,0) [0|1] "" Vector__XXX
 SG_ EPASTS_a098_invErr m1 : 41|1@1+ (1,0) [0|1] "" Vector__XXX
 SG_ EPASTS_a099_mcdTorqueMismatchFau m1 : 42|1@1+ (1,0) [0|1] "" Vector__XXX
 SG_ EPASTS_a100_amVbrgLssFault m1 : 43|1@1+ (1,0) [0|1] "" Vector__XXX
 SG_ EPASTS_a101_sdrvSpcIdMismatch m1 : 44|1@1+ (1,0) [0|1] "" Vector__XXX
 SG_ EPASTS_a102_amPhasecurrentQosErr m1 : 45|1@1+ (1,0) [0|1] "" Vector__XXX
 SG_ EPASTS_a103_exhaUnusedInterruptC m1 : 46|1@1+ (1,0) [0|1] "" Vector__XXX
 SG_ EPASTS_a104_exhaBusMpuException m1 : 47|1@1+ (1,0) [0|1] "" Vector__XXX
 SG_ EPASTS_a105_exhaSriBusErrExcepti m1 : 48|1@1+ (1,0) [0|1] "" Vector__XXX
 SG_ EPASTS_a106_exhaSpbBusErrExcepti m1 : 49|1@1+ (1,0) [0|1] "" Vector__XXX
 SG_ EPASTS_a107_exhaOtherNmiExceptio m1 : 50|1@1+ (1,0) [0|1] "" Vector__XXX
 SG_ EPASTS_a108_exhaInternalProtecti m1 : 51|1@1+ (1,0) [0|1] "" Vector__XXX
 SG_ EPASTS_a109_exhaSysBusOrPeriphEr m1 : 52|1@1+ (1,0) [0|1] "" Vector__XXX
 SG_ EPASTS_a110_amPhaseRelaySwitchOf m1 : 53|1@1+ (1,0) [0|1] "" Vector__XXX
 SG_ EPASTS_a111_amCurrentSensingDisc m1 : 54|1@1+ (1,0) [0|1] "" Vector__XXX
 SG_ EPASTS_a112_rsthSafetyFlipflopEr m1 : 55|1@1+ (1,0) [0|1] "" Vector__XXX
 SG_ EPASTS_a113_rsthUncorrectableEnd m1 : 56|1@1+ (1,0) [0|1] "" Vector__XXX
 SG_ EPASTS_a114_osehOsErr m1 : 57|1@1+ (1,0) [0|1] "" Vector__XXX
 SG_ EPASTS_a115_mcusscLbistSingleFai m1 : 58|1@1+ (1,0) [0|1] "" Vector__XXX
 SG_ EPASTS_a116_mrccStartupRegCsErro m1 : 59|1@1+ (1,0) [0|1] "" Vector__XXX
 SG_ EPASTS_a117_mrccStartupRegCsErro m1 : 60|1@1+ (1,0) [0|1] "" Vector__XXX
 SG_ EPASTS_a118_mcusscFlashCsErrorEr m1 : 61|1@1+ (1,0) [0|1] "" Vector__XXX
 SG_ EPASTS_a119_mcusscFlashEccCritic m1 : 62|1@1+ (1,0) [0|1] "" Vector__XXX
 SG_ EPASTS_a120_mcusscFlashEccLatent m1 : 63|1@1+ (1,0) [0|1] "" Vector__XXX
 SG_ EPASTS_a121_mcusscMbistEccErr m2 : 4|1@1+ (1,0) [0|1] "" Vector__XXX
 SG_ EPASTS_a122_pcpBridgeFetShort m2 : 5|1@1+ (1,0) [0|1] "" Vector__XXX
 SG_ EPASTS_a123_imcmCommErr m2 : 6|1@1+ (1,0) [0|1] "" Vector__XXX
 SG_ EPASTS_a124_mcusscMbistEccTransi m2 : 7|1@1+ (1,0) [0|1] "" Vector__XXX
 SG_ EPASTS_a125_mcusscMbistMiaErr m2 : 8|1@1+ (1,0) [0|1] "" Vector__XXX
 SG_ EPASTS_a126_mcusscMonbistMiaErr m2 : 9|1@1+ (1,0) [0|1] "" Vector__XXX
 SG_ EPASTS_a127_exchAdditionalExcept m2 : 10|1@1+ (1,0) [0|1] "" Vector__XXX
 SG_ EPASTS_a128_exchExceptionStopRes m2 : 11|1@1+ (1,0) [0|1] "" Vector__XXX
 SG_ EPASTS_a129_exchAdditionalExcept m2 : 12|1@1+ (1,0) [0|1] "" Vector__XXX
 SG_ EPASTS_a130_mrccConfigCsErrorErr m2 : 13|1@1+ (1,0) [0|1] "" Vector__XXX
 SG_ EPASTS_a131_exchGuardedResetAfte m2 : 14|1@1+ (1,0) [0|1] "" Vector__XXX
 SG_ EPASTS_a132_mcusscNotSupportedMc m2 : 15|1@1+ (1,0) [0|1] "" Vector__XXX
 SG_ EPASTS_a133_mcusscLbistEcuIdIsNo m2 : 16|1@1+ (1,0) [0|1] "" Vector__XXX
 SG_ EPASTS_a134_osehGuardedResetAfte m2 : 17|1@1+ (1,0) [0|1] "" Vector__XXX
 SG_ EPASTS_a135_tmpsfetjCalculationO m2 : 18|1@1+ (1,0) [0|1] "" Vector__XXX
 SG_ EPASTS_a136_ftElectricalAngleQf m2 : 19|1@1+ (1,0) [0|1] "" Vector__XXX
 SG_ EPASTS_a137_osehErrWithoutImmedi m2 : 20|1@1+ (1,0) [0|1] "" Vector__XXX
 SG_ EPASTS_a138_osehAdditionalErrWit m2 : 21|1@1+ (1,0) [0|1] "" Vector__XXX
 SG_ EPASTS_a139_osehAdditionalOsErr m2 : 22|1@1+ (1,0) [0|1] "" Vector__XXX
 SG_ EPASTS_a140_imcmConfigurationErr m2 : 23|1@1+ (1,0) [0|1] "" Vector__XXX
 SG_ EPASTS_a141_amFetShortTest m2 : 24|1@1+ (1,0) [0|1] "" Vector__XXX
 SG_ EPASTS_a142_tedEmifilterDmcTempC m2 : 25|1@1+ (1,0) [0|1] "" Vector__XXX
 SG_ EPASTS_a143_tedEmifilterCmcTempC m2 : 26|1@1+ (1,0) [0|1] "" Vector__XXX
 SG_ EPASTS_a144_mriCoreRaminitFailed m2 : 27|1@1+ (1,0) [0|1] "" Vector__XXX
 SG_ EPASTS_a145_mriPeripheralRaminit m2 : 28|1@1+ (1,0) [0|1] "" Vector__XXX
 SG_ EPASTS_a146_btarcRcCircuitCheck m2 : 29|1@1+ (1,0) [0|1] "" Vector__XXX
 SG_ EPASTS_a147_amDcLinkShortedFail m2 : 30|1@1+ (1,0) [0|1] "" Vector__XXX
 SG_ EPASTS_a148_mrccExitFromStandbyD m2 : 31|1@1+ (1,0) [0|1] "" Vector__XXX
 SG_ EPASTS_a149_amReversibleEmergenc m2 : 32|1@1+ (1,0) [0|1] "" Vector__XXX
 SG_ EPASTS_a150_amExternalEmergencyO m2 : 33|1@1+ (1,0) [0|1] "" Vector__XXX
 SG_ EPASTS_a151_amPermanentEmergency m2 : 34|1@1+ (1,0) [0|1] "" Vector__XXX
 SG_ EPASTS_a152_exchFlashEccExceptio m2 : 35|1@1+ (1,0) [0|1] "" Vector__XXX
 SG_ EPASTS_a153_sdsmBlockSelectorInv m2 : 36|1@1+ (1,0) [0|1] "" Vector__XXX
 SG_ EPASTS_a154_sdsmCsErrorInvalidPr m2 : 37|1@1+ (1,0) [0|1] "" Vector__XXX
 SG_ EPASTS_a155_sdsmDataInvalidAll m2 : 38|1@1+ (1,0) [0|1] "" Vector__XXX
 SG_ EPASTS_a156_amIntSerialErrSafety m2 : 39|1@1+ (1,0) [0|1] "" Vector__XXX
 SG_ EPASTS_a157_mcudcpInvalidEcuId m2 : 40|1@1+ (1,0) [0|1] "" Vector__XXX
 SG_ EPASTS_a158_amGduFailDuringRecov m2 : 41|1@1+ (1,0) [0|1] "" Vector__XXX
 SG_ EPASTS_a159_exchFlashWordlineTra m2 : 42|1@1+ (1,0) [0|1] "" Vector__XXX
 SG_ EPASTS_a160_rsthCpu1UnexpectedAl m2 : 43|1@1+ (1,0) [0|1] "" Vector__XXX
 SG_ EPASTS_a161_tdaRelayfetjunctionT m2 : 44|1@1+ (1,0) [0|1] "" Vector__XXX
 SG_ EPASTS_a162_tdaBridgefetjunction m2 : 45|1@1+ (1,0) [0|1] "" Vector__XXX
 SG_ EPASTS_a163_tdaPowermoduleTempCh m2 : 46|1@1+ (1,0) [0|1] "" Vector__XXX
 SG_ EPASTS_a164_tdaBattfetjunctionTe m2 : 47|1@1+ (1,0) [0|1] "" Vector__XXX
 SG_ EPASTS_a165_tdaDcbusshuntTempChe m2 : 48|1@1+ (1,0) [0|1] "" Vector__XXX
 SG_ EPASTS_a166_tdaPhasecurrentshunt m2 : 49|1@1+ (1,0) [0|1] "" Vector__XXX
 SG_ EPASTS_a167_iccd1ErrQueueOverflo m2 : 50|1@1+ (1,0) [0|1] "" Vector__XXX
 SG_ EPASTS_a168_c1csInvalidC1App m2 : 51|1@1+ (1,0) [0|1] "" Vector__XXX
 SG_ EPASTS_a169_scpSafetyReset m2 : 52|1@1+ (1,0) [0|1] "" Vector__XXX
 SG_ EPASTS_a170_pmpDcvoltAge m2 : 53|1@1+ (1,0) [0|1] "" Vector__XXX
 SG_ EPASTS_a171_pmpKgvalueAge m2 : 54|1@1+ (1,0) [0|1] "" Vector__XXX
 SG_ EPASTS_a172_pmpElangMotorcurrent m2 : 55|1@1+ (1,0) [0|1] "" Vector__XXX
 SG_ EPASTS_a173_pmpRotorspeedAge m2 : 56|1@1+ (1,0) [0|1] "" Vector__XXX
 SG_ EPASTS_a174_pmpPhasecurrentAge m2 : 57|1@1+ (1,0) [0|1] "" Vector__XXX
 SG_ EPASTS_a175_exchFlashStoredConfi m2 : 58|1@1+ (1,0) [0|1] "" Vector__XXX
 SG_ EPASTS_a176_exchCpu1ExceptionRes m2 : 59|1@1+ (1,0) [0|1] "" Vector__XXX
 SG_ EPASTS_a177_etsrInvalidated m2 : 60|1@1+ (1,0) [0|1] "" Vector__XXX
 SG_ EPASTS_a178_exchWdtException m2 : 61|1@1+ (1,0) [0|1] "" Vector__XXX
 SG_ EPASTS_a179_tedMotorcoilTempChec m2 : 62|1@1+ (1,0) [0|1] "" Vector__XXX
 SG_ EPASTS_a180_dmDeadlineViolationC m2 : 63|1@1+ (1,0) [0|1] "" Vector__XXX
 SG_ EPASTS_a181_dmDeadlineViolationC m3 : 4|1@1+ (1,0) [0|1] "" Vector__XXX
 SG_ EPASTS_a182_mcdInputMia m3 : 5|1@1+ (1,0) [0|1] "" Vector__XXX
 SG_ EPASTS_a183_sbchCommErrSbcToMcu m3 : 6|1@1+ (1,0) [0|1] "" Vector__XXX
 SG_ EPASTS_a184_sbcmCommBufferOverfl m3 : 7|1@1+ (1,0) [0|1] "" Vector__XXX
 SG_ EPASTS_a185_sbcscpQAWatchdogRese m3 : 8|1@1+ (1,0) [0|1] "" Vector__XXX
 SG_ EPASTS_a186_wdhCommBufferOverflo m3 : 9|1@1+ (1,0) [0|1] "" Vector__XXX
 SG_ EPASTS_a187_epmVoltFail m3 : 10|1@1+ (1,0) [0|1] "" Vector__XXX
 SG_ EPASTS_a188_epmCommBufferOverflo m3 : 11|1@1+ (1,0) [0|1] "" Vector__XXX
 SG_ EPASTS_a189_sbchCommErrMcuToSbc m3 : 12|1@1+ (1,0) [0|1] "" Vector__XXX
 SG_ EPASTS_a190_sbchCommBufferOverfl m3 : 13|1@1+ (1,0) [0|1] "" Vector__XXX
 SG_ EPASTS_a191_sbcscpVcp2VucVoltFai m3 : 14|1@1+ (1,0) [0|1] "" Vector__XXX
 SG_ EPASTS_a192_osumC0CsaNearFull m3 : 15|1@1+ (1,0) [0|1] "" Vector__XXX
 SG_ EPASTS_a193_osumC0StackNearFull m3 : 16|1@1+ (1,0) [0|1] "" Vector__XXX
 SG_ EPASTS_a194_amNvdataLoss m3 : 17|1@1+ (1,0) [0|1] "" Vector__XXX
 SG_ EPASTS_a195_imcmCommErrC1 m3 : 18|1@1+ (1,0) [0|1] "" Vector__XXX
 SG_ EPASTS_a196_topEolTasOffsetInval m3 : 19|1@1+ (1,0) [0|1] "" Vector__XXX
 SG_ EPASTS_a197_difpDifactorInvalid m3 : 20|1@1+ (1,0) [0|1] "" Vector__XXX
 SG_ EPASTS_a198_osumC1CsaNearFull m3 : 21|1@1+ (1,0) [0|1] "" Vector__XXX
 SG_ EPASTS_a199_osumC1StackNearFull m3 : 22|1@1+ (1,0) [0|1] "" Vector__XXX
 SG_ EPASTS_a200_ammInputBufferOverfl m3 : 23|1@1+ (1,0) [0|1] "" Vector__XXX
 SG_ EPASTS_a201_ammOutputBufferOverf m3 : 24|1@1+ (1,0) [0|1] "" Vector__XXX
 SG_ EPASTS_a202_ohnvmpStoredOffsetLo m3 : 25|1@1+ (1,0) [0|1] "" Vector__XXX
 SG_ EPASTS_a203_ctcInterfaceErr m3 : 26|1@1+ (1,0) [0|1] "" Vector__XXX
 SG_ EPASTS_a204_fdpPrevTrqErr m3 : 27|1@1+ (1,0) [0|1] "" Vector__XXX
 SG_ EPASTS_a205_fdrOclFail m3 : 28|1@1+ (1,0) [0|1] "" Vector__XXX
 SG_ EPASTS_a206_fdrOclPartialBlockin m3 : 29|1@1+ (1,0) [0|1] "" Vector__XXX
 SG_ EPASTS_a207_fdrOclFreezing m3 : 30|1@1+ (1,0) [0|1] "" Vector__XXX
 SG_ EPASTS_a208_fdrLowSeverityBlocki m3 : 31|1@1+ (1,0) [0|1] "" Vector__XXX
 SG_ EPASTS_a209_fdrLowSeverityFreezi m3 : 32|1@1+ (1,0) [0|1] "" Vector__XXX
 SG_ EPASTS_a210_fdrTotalBlocking m3 : 33|1@1+ (1,0) [0|1] "" Vector__XXX
 SG_ EPASTS_a211_frmInternalErr m3 : 34|1@1+ (1,0) [0|1] "" Vector__XXX
 SG_ EPASTS_a212_frmDataLost m3 : 35|1@1+ (1,0) [0|1] "" Vector__XXX
 SG_ EPASTS_a213_frmHighFrictionDetec m3 : 36|1@1+ (1,0) [0|1] "" Vector__XXX
 SG_ EPASTS_a214_velInterfaceErr m3 : 37|1@1+ (1,0) [0|1] "" Vector__XXX
 SG_ EPASTS_a215_vsgSafeViolErr m3 : 38|1@1+ (1,0) [0|1] "" Vector__XXX
 SG_ EPASTS_a216_isdgImproperShutdown m3 : 39|1@1+ (1,0) [0|1] "" Vector__XXX
 SG_ EPASTS_a217_msdMasterSilentErr m3 : 40|1@1+ (1,0) [0|1] "" Vector__XXX
 SG_ EPASTS_a218_aadApplicationStateE m3 : 41|1@1+ (1,0) [0|1] "" Vector__XXX
 SG_ EPASTS_a219_frhFastRestartFailed m3 : 42|1@1+ (1,0) [0|1] "" Vector__XXX
 SG_ EPASTS_a220_transceiverInputqueu m3 : 43|1@1+ (1,0) [0|1] "" Vector__XXX
 SG_ EPASTS_a221_apsCntError m3 : 44|1@1+ (1,0) [0|1] "" Vector__XXX
 SG_ EPASTS_a222_apsCsError m3 : 45|1@1+ (1,0) [0|1] "" Vector__XXX
 SG_ EPASTS_a223_apsMia m3 : 46|1@1+ (1,0) [0|1] "" Vector__XXX
 SG_ EPASTS_a224_dasCntError m3 : 47|1@1+ (1,0) [0|1] "" Vector__XXX
 SG_ EPASTS_a225_dasCsError m3 : 48|1@1+ (1,0) [0|1] "" Vector__XXX
 SG_ EPASTS_a226_dasMia m3 : 49|1@1+ (1,0) [0|1] "" Vector__XXX
 SG_ EPASTS_a227_dirTorqueCntError m3 : 50|1@1+ (1,0) [0|1] "" Vector__XXX
 SG_ EPASTS_a228_dirTorqueCsError m3 : 51|1@1+ (1,0) [0|1] "" Vector__XXX
 SG_ EPASTS_a229_dirTorqueMia m3 : 52|1@1+ (1,0) [0|1] "" Vector__XXX
 SG_ EPASTS_a230_diSpdCntError m3 : 53|1@1+ (1,0) [0|1] "" Vector__XXX
 SG_ EPASTS_a231_diSpdCsError m3 : 54|1@1+ (1,0) [0|1] "" Vector__XXX
 SG_ EPASTS_a232_diSpdMia m3 : 55|1@1+ (1,0) [0|1] "" Vector__XXX
 SG_ EPASTS_a233_ecu1StatCntError m3 : 56|1@1+ (1,0) [0|1] "" Vector__XXX
 SG_ EPASTS_a234_ecu1StatCsError m3 : 57|1@1+ (1,0) [0|1] "" Vector__XXX
 SG_ EPASTS_a235_ecu1StatMia m3 : 58|1@1+ (1,0) [0|1] "" Vector__XXX
 SG_ EPASTS_a236_espWrCntError m3 : 59|1@1+ (1,0) [0|1] "" Vector__XXX
 SG_ EPASTS_a237_espWrCsError m3 : 60|1@1+ (1,0) [0|1] "" Vector__XXX
 SG_ EPASTS_a238_espWrMia m3 : 61|1@1+ (1,0) [0|1] "" Vector__XXX
 SG_ EPASTS_a239_espWsCntError m3 : 62|1@1+ (1,0) [0|1] "" Vector__XXX
 SG_ EPASTS_a240_espWsCsError m3 : 63|1@1+ (1,0) [0|1] "" Vector__XXX
 SG_ EPASTS_a241_espWsMia m4 : 4|1@1+ (1,0) [0|1] "" Vector__XXX
 SG_ EPASTS_a242_gtwConfigMia m4 : 5|1@1+ (1,0) [0|1] "" Vector__XXX
 SG_ EPASTS_a243_rcmCntError m4 : 6|1@1+ (1,0) [0|1] "" Vector__XXX
 SG_ EPASTS_a244_rcmCsError m4 : 7|1@1+ (1,0) [0|1] "" Vector__XXX
 SG_ EPASTS_a245_rcmMia m4 : 8|1@1+ (1,0) [0|1] "" Vector__XXX
 SG_ EPASTS_a246_sccmCntError m4 : 9|1@1+ (1,0) [0|1] "" Vector__XXX
 SG_ EPASTS_a247_sccmCsError m4 : 10|1@1+ (1,0) [0|1] "" Vector__XXX
 SG_ EPASTS_a248_sccmMia m4 : 11|1@1+ (1,0) [0|1] "" Vector__XXX
 SG_ EPASTS_a249_uiTuneReqCntError m4 : 12|1@1+ (1,0) [0|1] "" Vector__XXX
 SG_ EPASTS_a250_uiTuneReqCsError m4 : 13|1@1+ (1,0) [0|1] "" Vector__XXX
 SG_ EPASTS_a251_uiTuneReqMia m4 : 14|1@1+ (1,0) [0|1] "" Vector__XXX
 SG_ EPASTS_a252_vcFrontCntError m4 : 15|1@1+ (1,0) [0|1] "" Vector__XXX
 SG_ EPASTS_a253_vcFrontCsError m4 : 16|1@1+ (1,0) [0|1] "" Vector__XXX
 SG_ EPASTS_a254_vcFrontMia m4 : 17|1@1+ (1,0) [0|1] "" Vector__XXX
 SG_ EPASTS_a255_pmState2Mia m4 : 18|1@1+ (1,0) [0|1] "" Vector__XXX
 SG_ EPASTS_a256_dcvmOverVolt m4 : 19|1@1+ (1,0) [0|1] "" Vector__XXX
 SG_ EPASTS_a257_dcvmUnderVolt m4 : 20|1@1+ (1,0) [0|1] "" Vector__XXX
 SG_ EPASTS_a258_pspInvalidProjectPar m4 : 21|1@1+ (1,0) [0|1] "" Vector__XXX
 SG_ EPASTS_a259_scoCanBusOff m4 : 22|1@1+ (1,0) [0|1] "" Vector__XXX
 SG_ EPASTS_a260_scoPrivateBusOff m4 : 23|1@1+ (1,0) [0|1] "" Vector__XXX
 SG_ EPASTS_a261_sccmStatusError m4 : 24|1@1+ (1,0) [0|1] "" Vector__XXX
 SG_ EPASTS_a262_yawRateStatus m4 : 25|1@1+ (1,0) [0|1] "" Vector__XXX
 SG_ EPASTS_a263_espWsStatus m4 : 26|1@1+ (1,0) [0|1] "" Vector__XXX
 SG_ EPASTS_a264_assistTorqueLimited m4 : 27|1@1+ (1,0) [0|1] "" Vector__XXX
 SG_ EPASTS_a265_overheatProtect m4 : 28|1@1+ (1,0) [0|1] "" Vector__XXX
 SG_ EPASTS_a266_overloadProtect m4 : 29|1@1+ (1,0) [0|1] "" Vector__XXX
 SG_ EPASTS_a267_safeSpeedAssist m4 : 30|1@1+ (1,0) [0|1] "" Vector__XXX
 SG_ EPASTS_a268_eacCancelled m4 : 31|1@1+ (1,0) [0|1] "" Vector__XXX
 SG_ EPASTS_a269_assistTorqueDisabled m4 : 32|1@1+ (1,0) [0|1] "" Vector__XXX
 SG_ EPASTS_a270_oscillationCompTrqLi m4 : 33|1@1+ (1,0) [0|1] "" Vector__XXX

BO_ 888 GTW_ECall: 1 GTW
 SG_ GTW_GTW_SOS_ECALL_RQST : 0|1@1+ (1,0) [0|1] "" Vector__XXX
 SG_ GTW_LTE_ECALL_LOCK : 1|1@1+ (1,0) [0|1] "" Vector__XXX

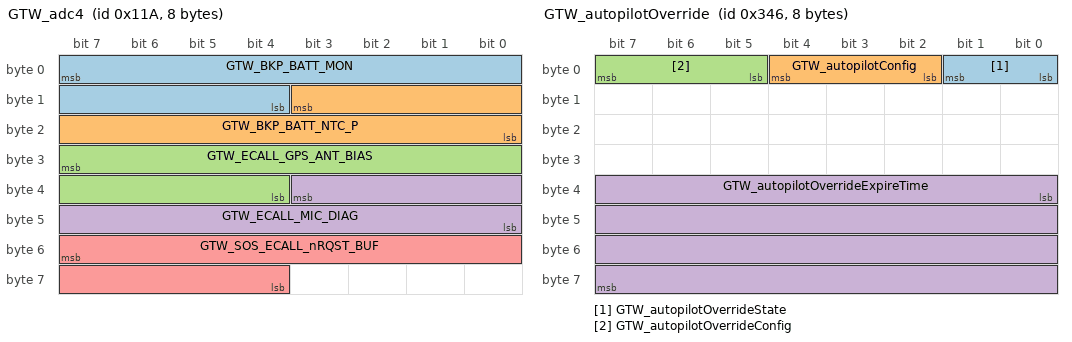
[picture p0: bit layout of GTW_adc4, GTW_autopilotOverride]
BO_ 282 GTW_adc4: 8 GTW
 SG_ GTW_BKP_BATT_MON : 7|12@0+ (1,0) [0|4094] "mV" Vector__XXX
 SG_ GTW_BKP_BATT_NTC_P : 11|12@0+ (1,0) [0|4094] "mV" Vector__XXX
 SG_ GTW_ECALL_GPS_ANT_BIAS : 31|12@0+ (1,0) [0|4094] "mV" Vector__XXX
 SG_ GTW_ECALL_MIC_DIAG : 35|12@0+ (1,0) [0|4094] "mV" Vector__XXX
 SG_ GTW_SOS_ECALL_nRQST_BUF : 55|12@0+ (1,0) [0|4094] "mV" Vector__XXX

BO_ 1384 GTW_alertLog: 8 GTW
 SG_ GTW_alertID M : 0|9@1+ (1,0) [0|511] "" Vector__XXX
 SG_ GTW_alertState : 15|1@1+ (1,0) [0|1] "" Vector__XXX
 SG_ GTW_a014_crcVersion m14 : 16|32@1+ (1,0) [0|4294967295] "" Vector__XXX
 SG_ GTW_a015_crcVersion m15 : 16|32@1+ (1,0) [0|4294967295] "" Vector__XXX
 SG_ GTW_a016_crcVersion m16 : 16|32@1+ (1,0) [0|4294967295] "" Vector__XXX
 SG_ GTW_a017_crcVersion m17 : 16|32@1+ (1,0) [0|4294967295] "" Vector__XXX
 SG_ GTW_a018_crcVersion m18 : 16|32@1+ (1,0) [0|4294967295] "" Vector__XXX
 SG_ GTW_a019_crcVersion m19 : 16|32@1+ (1,0) [0|4294967295] "" Vector__XXX
 SG_ GTW_a020_crcVersion m20 : 16|32@1+ (1,0) [0|4294967295] "" Vector__XXX
 SG_ GTW_a021_crcVersion m21 : 16|32@1+ (1,0) [0|4294967295] "" Vector__XXX
 SG_ GTW_a022_crcVersion m22 : 16|32@1+ (1,0) [0|4294967295] "" Vector__XXX
 SG_ GTW_a023_crcVersion m23 : 16|32@1+ (1,0) [0|4294967295] "" Vector__XXX
 SG_ GTW_a024_crcVersion m24 : 16|32@1+ (1,0) [0|4294967295] "" Vector__XXX
 SG_ GTW_a025_crcVersion m25 : 16|32@1+ (1,0) [0|4294967295] "" Vector__XXX
 SG_ GTW_a026_crcVersion m26 : 16|32@1+ (1,0) [0|4294967295] "" Vector__XXX
 SG_ GTW_a027_crcVersion m27 : 16|32@1+ (1,0) [0|4294967295] "" Vector__XXX
 SG_ GTW_a028_crcVersion m28 : 16|32@1+ (1,0) [0|4294967295] "" Vector__XXX
 SG_ GTW_a029_crcVersion m29 : 16|32@1+ (1,0) [0|4294967295] "" Vector__XXX
 SG_ GTW_a030_crcVersion m30 : 16|32@1+ (1,0) [0|4294967295] "" Vector__XXX
 SG_ GTW_a031_crcVersion m31 : 16|32@1+ (1,0) [0|4294967295] "" Vector__XXX
 SG_ GTW_a032_crcVersion m32 : 16|32@1+ (1,0) [0|4294967295] "" Vector__XXX
 SG_ GTW_a033_crcVersion m33 : 16|32@1+ (1,0) [0|4294967295] "" Vector__XXX
 SG_ GTW_a034_crcVersion m34 : 16|32@1+ (1,0) [0|4294967295] "" Vector__XXX
 SG_ GTW_a035_crcVersion m35 : 16|32@1+ (1,0) [0|4294967295] "" Vector__XXX
 SG_ GTW_a036_crcVersion m36 : 16|32@1+ (1,0) [0|4294967295] "" Vector__XXX
 SG_ GTW_a037_crcVersion m37 : 16|32@1+ (1,0) [0|4294967295] "" Vector__XXX
 SG_ GTW_a038_crcVersion m38 : 16|32@1+ (1,0) [0|4294967295] "" Vector__XXX
 SG_ GTW_a039_crcVersion m39 : 16|32@1+ (1,0) [0|4294967295] "" Vector__XXX
 SG_ GTW_a040_crcVersion m40 : 16|32@1+ (1,0) [0|4294967295] "" Vector__XXX
 SG_ GTW_a041_crcVersion m41 : 16|32@1+ (1,0) [0|4294967295] "" Vector__XXX
 SG_ GTW_a042_crcVersion m42 : 16|32@1+ (1,0) [0|4294967295] "" Vector__XXX
 SG_ GTW_a043_crcVersion m43 : 16|32@1+ (1,0) [0|4294967295] "" Vector__XXX
 SG_ GTW_a045_crcVersion m45 : 16|32@1+ (1,0) [0|4294967295] "" Vector__XXX
 SG_ GTW_a046_crcVersion m46 : 16|32@1+ (1,0) [0|4294967295] "" Vector__XXX
 SG_ GTW_a047_crcVersion m47 : 16|32@1+ (1,0) [0|4294967295] "" Vector__XXX
 SG_ GTW_a048_crcVersion m48 : 16|32@1+ (1,0) [0|4294967295] "" Vector__XXX
 SG_ GTW_a049_headerError m49 : 16|2@1+ (1,0) [0|3] "" Vector__XXX
 SG_ GTW_a054_crcVersion m54 : 16|32@1+ (1,0) [0|4294967295] "" Vector__XXX
 SG_ GTW_a055_crcVersion m55 : 16|32@1+ (1,0) [0|4294967295] "" Vector__XXX
 SG_ GTW_a062_bmpWatchdogReason m62 : 16|2@1+ (1,0) [0|3] "" Vector__XXX
 SG_ GTW_a063_VEH_faultConfinement m63 : 16|2@1+ (1,0) [0|3] "" Vector__XXX
 SG_ GTW_a064_CH_faultConfinement m64 : 16|2@1+ (1,0) [0|3] "" Vector__XXX
 SG_ GTW_a065_PARTY_faultConfinement m65 : 16|2@1+ (1,0) [0|3] "" Vector__XXX
 SG_ GTW_a066_type m66 : 16|8@1+ (1,0) [0|255] "" Vector__XXX
 SG_ GTW_a066_exceptionCfgId m66 : 24|8@1+ (1,0) [0|255] "" Vector__XXX
 SG_ GTW_a066_uptime m66 : 32|32@1+ (1,0) [0|4294967295] "" Vector__XXX
 SG_ GTW_a068_codeKeyMissing m68 : 16|1@1+ (1,0) [0|1] "" Vector__XXX
 SG_ GTW_a068_cmdKeyMissing m68 : 17|1@1+ (1,0) [0|1] "" Vector__XXX
 SG_ GTW_a069_sdIntStatusErrs m69 : 16|1@1+ (1,0) [0|1] "" Vector__XXX
 SG_ GTW_a069_sdTimeout m69 : 17|1@1+ (1,0) [0|1] "" Vector__XXX
 SG_ GTW_a069_sdCmdErr m69 : 18|1@1+ (1,0) [0|1] "" Vector__XXX
 SG_ GTW_a069_sdWriteErr m69 : 19|1@1+ (1,0) [0|1] "" Vector__XXX
 SG_ GTW_a069_sdReadErr m69 : 20|1@1+ (1,0) [0|1] "" Vector__XXX
 SG_ GTW_a069_autoCmd12Err m69 : 21|1@1+ (1,0) [0|1] "" Vector__XXX
 SG_ GTW_a072_updtFailureMask m72 : 16|32@1+ (1,0) [0|4294967295] "" Vector__XXX
 SG_ GTW_a077_bmpPmicErrorType m77 : 16|3@1+ (1,0) [0|7] "" Vector__XXX
 SG_ GTW_a078_loadPercent m78 : 16|7@1+ (1,0) [0|127] "percent" Vector__XXX
 SG_ GTW_a079_loadPercent m79 : 16|7@1+ (1,0) [0|127] "percent" Vector__XXX
 SG_ GTW_a080_loadPercent m80 : 16|7@1+ (1,0) [0|127] "percent" Vector__XXX
 SG_ GTW_a081_canId m81 : 16|11@1+ (1,0) [0|2047] "" Vector__XXX
 SG_ GTW_a081_ISOTPmsgType m81 : 27|2@1+ (1,0) [0|3] "" Vector__XXX
 SG_ GTW_a081_udsSID m81 : 32|30@1+ (1,0) [0|1073741823] "" Vector__XXX
 SG_ GTW_a097_crcVersion m97 : 16|32@1+ (1,0) [0|4294967295] "" Vector__XXX
 SG_ GTW_a098_crcVersion m98 : 16|32@1+ (1,0) [0|4294967295] "" Vector__XXX
 SG_ GTW_a099_crcVersion m99 : 16|32@1+ (1,0) [0|4294967295] "" Vector__XXX
 SG_ GTW_a100_crcVersion m100 : 16|32@1+ (1,0) [0|4294967295] "" Vector__XXX
 SG_ GTW_a101_switchStuck m101 : 16|1@1+ (1,0) [0|1] "" Vector__XXX
 SG_ GTW_a101_ETH_SW_nINT m101 : 17|1@1+ (1,0) [0|1] "" Vector__XXX
 SG_ GTW_a106_crcVersion m106 : 16|32@1+ (1,0) [0|4294967295] "" Vector__XXX
 SG_ GTW_a107_crcVersion m107 : 16|32@1+ (1,0) [0|4294967295] "" Vector__XXX
 SG_ GTW_a108_crcVersion m108 : 16|32@1+ (1,0) [0|4294967295] "" Vector__XXX
 SG_ GTW_a113_bus m113 : 16|8@1+ (1,0) [0|255] "" Vector__XXX
 SG_ GTW_a113_id m113 : 24|11@1+ (1,0) [0|2047] "" Vector__XXX
 SG_ GTW_a117_MC_RGM_DES m117 : 16|32@1+ (1,0) [0|4294967295] "" Vector__XXX
 SG_ GTW_a118_MC_RGM_FES m118 : 16|32@1+ (1,0) [0|4294967295] "" Vector__XXX
 SG_ GTW_a122_BDY_faultConfinement m122 : 16|2@1+ (1,0) [0|3] "" Vector__XXX
 SG_ GTW_a129_crcVersion m129 : 16|32@1+ (1,0) [0|4294967295] "" Vector__XXX
 SG_ GTW_a138_sdLifetimeUsed m138 : 16|8@1+ (1,0) [0|255] "" Vector__XXX
 SG_ GTW_a139_crcVersion m139 : 16|32@1+ (1,0) [0|4294967295] "" Vector__XXX
 SG_ GTW_a150_crcVersion m150 : 16|32@1+ (1,0) [0|4294967295] "" Vector__XXX
 SG_ GTW_a151_crcVersion m151 : 16|32@1+ (1,0) [0|4294967295] "" Vector__XXX
 SG_ GTW_a155_crcVersion m155 : 16|32@1+ (1,0) [0|4294967295] "" Vector__XXX
 SG_ GTW_a165_crcVersion m165 : 16|32@1+ (1,0) [0|4294967295] "" Vector__XXX
 SG_ GTW_a169_TPMS_pressureFL m169 : 16|8@1+ (1,0) [0|255] "" Vector__XXX
 SG_ GTW_a170_TPMS_pressureFR m170 : 16|8@1+ (1,0) [0|255] "" Vector__XXX
 SG_ GTW_a171_TPMS_pressureRL m171 : 16|8@1+ (1,0) [0|255] "" Vector__XXX
 SG_ GTW_a172_TPMS_pressureRR m172 : 16|8@1+ (1,0) [0|255] "" Vector__XXX
 SG_ GTW_a173_TPMS_pressureFL m173 : 16|8@1+ (1,0) [0|255] "" Vector__XXX
 SG_ GTW_a174_TPMS_pressureFR m174 : 16|8@1+ (1,0) [0|255] "" Vector__XXX
 SG_ GTW_a175_TPMS_pressureRL m175 : 16|8@1+ (1,0) [0|255] "" Vector__XXX
 SG_ GTW_a176_TPMS_pressureRR m176 : 16|8@1+ (1,0) [0|255] "" Vector__XXX
 SG_ GTW_a219_crcVersion m219 : 16|32@1+ (1,0) [0|4294967295] "" Vector__XXX
 SG_ GTW_a223_crcVersion m223 : 16|32@1+ (1,0) [0|4294967295] "" Vector__XXX
 SG_ GTW_a226_crcVersion m226 : 16|32@1+ (1,0) [0|4294967295] "" Vector__XXX
 SG_ GTW_a227_crcVersion m227 : 16|32@1+ (1,0) [0|4294967295] "" Vector__XXX
 SG_ GTW_a228_crcVersion m228 : 16|32@1+ (1,0) [0|4294967295] "" Vector__XXX
 SG_ GTW_a244_crcVersion m244 : 16|32@1+ (1,0) [0|4294967295] "" Vector__XXX
 SG_ GTW_a245_page0ControlValue m245 : 16|16@1+ (1,0) [0|65535] "" Vector__XXX
 SG_ GTW_a245_page1ControlValue m245 : 32|16@1+ (1,0) [0|65535] "" Vector__XXX
 SG_ GTW_a261_failureReason m261 : 16|3@1+ (1,0) [0|7] "" Vector__XXX
 SG_ GTW_a261_failureData1 m261 : 24|16@1+ (1,0) [0|65535] "" Vector__XXX
 SG_ GTW_a261_failureData2 m261 : 40|16@1+ (1,0) [0|65535] "" Vector__XXX
 SG_ GTW_a273_crcVersion m273 : 16|32@1+ (1,0) [0|4294967295] "" Vector__XXX
 SG_ GTW_a274_crcVersion m274 : 16|32@1+ (1,0) [0|4294967295] "" Vector__XXX
 SG_ GTW_a277_mitigationFailureReason m277 : 16|3@1+ (1,0) [0|7] "" Vector__XXX
 SG_ GTW_a279_repeatCount m279 : 16|8@1+ (1,0) [0|255] "" Vector__XXX
 SG_ GTW_a279_failureReason m279 : 24|3@1+ (1,0) [0|7] "" Vector__XXX
 SG_ GTW_a279_failureData1 m279 : 32|16@1+ (1,0) [0|65535] "" Vector__XXX
 SG_ GTW_a279_failureData2 m279 : 48|16@1+ (1,0) [0|65535] "" Vector__XXX
 SG_ GTW_a309_crcVersion m309 : 16|32@1+ (1,0) [0|4294967295] "" Vector__XXX
 SG_ GTW_a317_status m317 : 16|3@1+ (1,0) [0|7] "" Vector__XXX
 SG_ GTW_a317_errorCode m317 : 19|5@1+ (1,0) [0|31] "" Vector__XXX
 SG_ GTW_a329_crcVersion m329 : 16|32@1+ (1,0) [0|4294967295] "" Vector__XXX
 SG_ GTW_a330_crcVersion m330 : 16|32@1+ (1,0) [0|4294967295] "" Vector__XXX
 SG_ GTW_a331_crcVersion m331 : 16|32@1+ (1,0) [0|4294967295] "" Vector__XXX
 SG_ GTW_a342_crcVersion m342 : 16|32@1+ (1,0) [0|4294967295] "" Vector__XXX
 SG_ GTW_a348_crcVersion m348 : 16|32@1+ (1,0) [0|4294967295] "" Vector__XXX
 SG_ GTW_a349_crcVersion m349 : 16|32@1+ (1,0) [0|4294967295] "" Vector__XXX
 SG_ GTW_a354_crcVersion m354 : 16|32@1+ (1,0) [0|4294967295] "" Vector__XXX
 SG_ GTW_a355_crcVersion m355 : 16|32@1+ (1,0) [0|4294967295] "" Vector__XXX
 SG_ GTW_a358_crcVersion m358 : 16|32@1+ (1,0) [0|4294967295] "" Vector__XXX
 SG_ GTW_a359_crcVersion m359 : 16|32@1+ (1,0) [0|4294967295] "" Vector__XXX
 SG_ GTW_a360_crcVersion m360 : 16|32@1+ (1,0) [0|4294967295] "" Vector__XXX
 SG_ GTW_a361_crcVersion m361 : 16|32@1+ (1,0) [0|4294967295] "" Vector__XXX
 SG_ GTW_a362_crcVersion m362 : 16|32@1+ (1,0) [0|4294967295] "" Vector__XXX
 SG_ GTW_a363_crcVersion m363 : 16|32@1+ (1,0) [0|4294967295] "" Vector__XXX
 SG_ GTW_a364_crcVersion m364 : 16|32@1+ (1,0) [0|4294967295] "" Vector__XXX
 SG_ GTW_a380_crcVersion m380 : 16|32@1+ (1,0) [0|4294967295] "" Vector__XXX
 SG_ GTW_a381_crcVersion m381 : 16|32@1+ (1,0) [0|4294967295] "" Vector__XXX
 SG_ GTW_a382_crcVersion m382 : 16|32@1+ (1,0) [0|4294967295] "" Vector__XXX
 SG_ GTW_a383_crcVersion m383 : 16|32@1+ (1,0) [0|4294967295] "" Vector__XXX
 SG_ GTW_a384_crcVersion m384 : 16|32@1+ (1,0) [0|4294967295] "" Vector__XXX
 SG_ GTW_a385_crcVersion m385 : 16|32@1+ (1,0) [0|4294967295] "" Vector__XXX
 SG_ GTW_a386_crcVersion m386 : 16|32@1+ (1,0) [0|4294967295] "" Vector__XXX
 SG_ GTW_a409_RES_CAUSE m409 : 16|32@1+ (1,0) [0|4294967295] "" Vector__XXX
 SG_ GTW_a410_RES_CAUSE2 m410 : 16|32@1+ (1,0) [0|4294967295] "" Vector__XXX

BO_ 62 GTW_alertMatrix: 8 GTW
 SG_ GTW_matrixIndex M : 0|4@1+ (1,0) [0|15] "" Vector__XXX
 SG_ GTW_w001_canEthTxQueue m0 : 4|1@1+ (1,0) [0|1] "" Vector__XXX
 SG_ GTW_w002_taskError m0 : 5|1@1+ (1,0) [0|1] "" Vector__XXX
 SG_ GTW_w003_logWriteRecord m0 : 6|1@1+ (1,0) [0|1] "" Vector__XXX
 SG_ GTW_w004_mallocHook m0 : 7|1@1+ (1,0) [0|1] "" Vector__XXX
 SG_ GTW_w005_stackOverflowHook m0 : 8|1@1+ (1,0) [0|1] "" Vector__XXX
 SG_ GTW_w006_ifTxOutputFull m0 : 9|1@1+ (1,0) [0|1] "" Vector__XXX
 SG_ GTW_w007_ifRxBufError m0 : 10|1@1+ (1,0) [0|1] "" Vector__XXX
 SG_ GTW_w008_ifPbufAllocError m0 : 11|1@1+ (1,0) [0|1] "" Vector__XXX
 SG_ GTW_w009_lateTask m0 : 12|1@1+ (1,0) [0|1] "" Vector__XXX
 SG_ GTW_w010_wdTaskCount m0 : 13|1@1+ (1,0) [0|1] "" Vector__XXX
 SG_ GTW_w011_cancoreWatchdog m0 : 14|1@1+ (1,0) [0|1] "" Vector__XXX
 SG_ GTW_w012_maincoreWatchdog m0 : 15|1@1+ (1,0) [0|1] "" Vector__XXX
 SG_ GTW_w014_APSversionMismatch m0 : 17|1@1+ (1,0) [0|1] "" Vector__XXX
 SG_ GTW_w015_DIFversionMismatch m0 : 18|1@1+ (1,0) [0|1] "" Vector__XXX
 SG_ GTW_w016_BLEEPCENTERversionMisma m0 : 19|1@1+ (1,0) [0|1] "" Vector__XXX
 SG_ GTW_w017_BMSversionMismatch m0 : 20|1@1+ (1,0) [0|1] "" Vector__XXX
 SG_ GTW_w018_CMPversionMismatch m0 : 21|1@1+ (1,0) [0|1] "" Vector__XXX
 SG_ GTW_w019_CPversionMismatch m0 : 22|1@1+ (1,0) [0|1] "" Vector__XXX
 SG_ GTW_w020_DIRversionMismatch m0 : 23|1@1+ (1,0) [0|1] "" Vector__XXX
 SG_ GTW_w021_EPAS3PversionMismatch m0 : 24|1@1+ (1,0) [0|1] "" Vector__XXX
 SG_ GTW_w022_EPBLversionMismatch m0 : 25|1@1+ (1,0) [0|1] "" Vector__XXX
 SG_ GTW_w023_EPBRversionMismatch m0 : 26|1@1+ (1,0) [0|1] "" Vector__XXX
 SG_ GTW_w024_ESPversionMismatch m0 : 27|1@1+ (1,0) [0|1] "" Vector__XXX
 SG_ GTW_w025_ESPCALversionMismatch m0 : 28|1@1+ (1,0) [0|1] "" Vector__XXX
 SG_ GTW_w026_GTWversionMismatch m0 : 29|1@1+ (1,0) [0|1] "" Vector__XXX
 SG_ GTW_w027_HVPversionMismatch m0 : 30|1@1+ (1,0) [0|1] "" Vector__XXX
 SG_ GTW_w028_IBSTversionMismatch m0 : 31|1@1+ (1,0) [0|1] "" Vector__XXX
 SG_ GTW_w029_IBSTCALversionMismatch m0 : 32|1@1+ (1,0) [0|1] "" Vector__XXX
 SG_ GTW_w030_OCS1PversionMismatch m0 : 33|1@1+ (1,0) [0|1] "" Vector__XXX
 SG_ GTW_w031_PARKversionMismatch m0 : 34|1@1+ (1,0) [0|1] "" Vector__XXX
 SG_ GTW_w032_PCSversionMismatch m0 : 35|1@1+ (1,0) [0|1] "" Vector__XXX
 SG_ GTW_w033_PCSCPU2versionMismatch m0 : 36|1@1+ (1,0) [0|1] "" Vector__XXX
 SG_ GTW_w034_PMRversionMismatch m0 : 37|1@1+ (1,0) [0|1] "" Vector__XXX
 SG_ GTW_w035_PMFversionMismatch m0 : 38|1@1+ (1,0) [0|1] "" Vector__XXX
 SG_ GTW_w036_PTCversionMismatch m0 : 39|1@1+ (1,0) [0|1] "" Vector__XXX
 SG_ GTW_w037_RADCversionMismatch m0 : 40|1@1+ (1,0) [0|1] "" Vector__XXX
 SG_ GTW_w038_RCMversionMismatch m0 : 41|1@1+ (1,0) [0|1] "" Vector__XXX
 SG_ GTW_w039_RCMCALversionMismatch m0 : 42|1@1+ (1,0) [0|1] "" Vector__XXX
 SG_ GTW_w040_SCCMversionMismatch m0 : 43|1@1+ (1,0) [0|1] "" Vector__XXX
 SG_ GTW_w041_VCSECversionMismatch m0 : 44|1@1+ (1,0) [0|1] "" Vector__XXX
 SG_ GTW_w042_TASversionMismatch m0 : 45|1@1+ (1,0) [0|1] "" Vector__XXX
 SG_ GTW_w043_THSversionMismatch m0 : 46|1@1+ (1,0) [0|1] "" Vector__XXX
 SG_ GTW_w045_VCFRONTversionMismatch m0 : 48|1@1+ (1,0) [0|1] "" Vector__XXX
 SG_ GTW_w046_VCLEFTversionMismatch m0 : 49|1@1+ (1,0) [0|1] "" Vector__XXX
 SG_ GTW_w047_VCRIGHTversionMismatch m0 : 50|1@1+ (1,0) [0|1] "" Vector__XXX
 SG_ GTW_w048_EPAS3SversionMismatch m0 : 51|1@1+ (1,0) [0|1] "" Vector__XXX
 SG_ GTW_w049_corruptedManifest m0 : 52|1@1+ (1,0) [0|1] "" Vector__XXX
 SG_ GTW_w050_sdCardInitFailure m0 : 53|1@1+ (1,0) [0|1] "" Vector__XXX
 SG_ GTW_w051_sdCardFileSystemFailure m0 : 54|1@1+ (1,0) [0|1] "" Vector__XXX
 SG_ GTW_w052_ifTxSpans m0 : 55|1@1+ (1,0) [0|1] "" Vector__XXX
 SG_ GTW_w053_busSleepFailure m0 : 56|1@1+ (1,0) [0|1] "" Vector__XXX
 SG_ GTW_w054_OPCRversionMismatch m0 : 57|1@1+ (1,0) [0|1] "" Vector__XXX
 SG_ GTW_w055_OPCFversionMismatch m0 : 58|1@1+ (1,0) [0|1] "" Vector__XXX
 SG_ GTW_w057_i2cFailure m0 : 60|1@1+ (1,0) [0|1] "" Vector__XXX
 SG_ GTW_w058_rtcAlarmFailure m0 : 61|1@1+ (1,0) [0|1] "" Vector__XXX
 SG_ GTW_w059_inFactoryMode m0 : 62|1@1+ (1,0) [0|1] "" Vector__XXX
 SG_ GTW_w060_unFused m0 : 63|1@1+ (1,0) [0|1] "" Vector__XXX
 SG_ GTW_w061_bmpSleepFailure m1 : 4|1@1+ (1,0) [0|1] "" Vector__XXX
 SG_ GTW_w062_bmpWatchdog m1 : 5|1@1+ (1,0) [0|1] "" Vector__XXX
 SG_ GTW_w063_VEH_canFault m1 : 6|1@1+ (1,0) [0|1] "" Vector__XXX
 SG_ GTW_w064_CH_canFault m1 : 7|1@1+ (1,0) [0|1] "" Vector__XXX
 SG_ GTW_w065_PARTY_canFault m1 : 8|1@1+ (1,0) [0|1] "" Vector__XXX
 SG_ GTW_w066_exception m1 : 9|1@1+ (1,0) [0|1] "" Vector__XXX
 SG_ GTW_w067_tcpDebug m1 : 10|1@1+ (1,0) [0|1] "" Vector__XXX
 SG_ GTW_w068_prodKeyMissing m1 : 11|1@1+ (1,0) [0|1] "" Vector__XXX
 SG_ GTW_w069_diskioErr m1 : 12|1@1+ (1,0) [0|1] "" Vector__XXX
 SG_ GTW_w070_hrlDump m1 : 13|1@1+ (1,0) [0|1] "" Vector__XXX
 SG_ GTW_w071_hrlTrigger m1 : 14|1@1+ (1,0) [0|1] "" Vector__XXX
 SG_ GTW_w072_updateFailure m1 : 15|1@1+ (1,0) [0|1] "" Vector__XXX
 SG_ GTW_w073_steeringWheelReset m1 : 16|1@1+ (1,0) [0|1] "" Vector__XXX
 SG_ GTW_w074_epas3pMIA m1 : 17|1@1+ (1,0) [0|1] "" Vector__XXX
 SG_ GTW_w075_epas3sMIA m1 : 18|1@1+ (1,0) [0|1] "" Vector__XXX
 SG_ GTW_w076_ethInterfaceReset m1 : 19|1@1+ (1,0) [0|1] "" Vector__XXX
 SG_ GTW_w077_bmpPmicError m1 : 20|1@1+ (1,0) [0|1] "" Vector__XXX
 SG_ GTW_w078_VEHbusOverloaded m1 : 21|1@1+ (1,0) [0|1] "" Vector__XXX
 SG_ GTW_w079_PARTYbusOverloaded m1 : 22|1@1+ (1,0) [0|1] "" Vector__XXX
 SG_ GTW_w080_CHbusOverloaded m1 : 23|1@1+ (1,0) [0|1] "" Vector__XXX
 SG_ GTW_w081_udsMessageRejected m1 : 24|1@1+ (1,0) [0|1] "" Vector__XXX
 SG_ GTW_w082_sdCardBSCorrupted m1 : 25|1@1+ (1,0) [0|1] "" Vector__XXX
 SG_ GTW_w083_udsMsgDroppedByTcpStack m1 : 26|1@1+ (1,0) [0|1] "" Vector__XXX
 SG_ GTW_w084_canFrameDropped m1 : 27|1@1+ (1,0) [0|1] "" Vector__XXX
 SG_ GTW_w086_ocu m1 : 29|1@1+ (1,0) [0|1] "" Vector__XXX
 SG_ GTW_w087_ocuInProgress m1 : 30|1@1+ (1,0) [0|1] "" Vector__XXX
 SG_ GTW_w088_sdCardInvReqParallel m1 : 31|1@1+ (1,0) [0|1] "" Vector__XXX
 SG_ GTW_w089_sdCardWatchdog m1 : 32|1@1+ (1,0) [0|1] "" Vector__XXX
 SG_ GTW_w090_ocuFailed m1 : 33|1@1+ (1,0) [0|1] "" Vector__XXX
 SG_ GTW_w091_lowStack m1 : 34|1@1+ (1,0) [0|1] "" Vector__XXX
 SG_ GTW_w092_sdCardInvReqZero m1 : 35|1@1+ (1,0) [0|1] "" Vector__XXX
 SG_ GTW_w093_sdCardInvReqOverflowBas m1 : 36|1@1+ (1,0) [0|1] "" Vector__XXX
 SG_ GTW_w094_sdCardInvReqOverflowCou m1 : 37|1@1+ (1,0) [0|1] "" Vector__XXX
 SG_ GTW_w095_sdCardFull m1 : 38|1@1+ (1,0) [0|1] "" Vector__XXX
 SG_ GTW_w096_sdCardFatCorrupted m1 : 39|1@1+ (1,0) [0|1] "" Vector__XXX
 SG_ GTW_w097_HCMLversionMismatch m1 : 40|1@1+ (1,0) [0|1] "" Vector__XXX
 SG_ GTW_w098_HCMRversionMismatch m1 : 41|1@1+ (1,0) [0|1] "" Vector__XXX
 SG_ GTW_w099_SWCversionMismatch m1 : 42|1@1+ (1,0) [0|1] "" Vector__XXX
 SG_ GTW_w100_CBCversionMismatch m1 : 43|1@1+ (1,0) [0|1] "" Vector__XXX
 SG_ GTW_w101_switchWatchdog m1 : 44|1@1+ (1,0) [0|1] "" Vector__XXX
 SG_ GTW_w103_sdCardFormatted m1 : 46|1@1+ (1,0) [0|1] "" Vector__XXX
 SG_ GTW_w104_sdCardDriverArgCorrupte m1 : 47|1@1+ (1,0) [0|1] "" Vector__XXX
 SG_ GTW_w105_eBuckConfigured m1 : 48|1@1+ (1,0) [0|1] "" Vector__XXX
 SG_ GTW_w106_BLEEPLEFTversionMismatc m1 : 49|1@1+ (1,0) [0|1] "" Vector__XXX
 SG_ GTW_w107_BLEEPRIGHTversionMismat m1 : 50|1@1+ (1,0) [0|1] "" Vector__XXX
 SG_ GTW_w108_BLEEPREARversionMismatc m1 : 51|1@1+ (1,0) [0|1] "" Vector__XXX
 SG_ GTW_w109_failedToStartUpdater m1 : 52|1@1+ (1,0) [0|1] "" Vector__XXX
 SG_ GTW_w110_readMdioFailed m1 : 53|1@1+ (1,0) [0|1] "" Vector__XXX
 SG_ GTW_w111_writeMdioFailed m1 : 54|1@1+ (1,0) [0|1] "" Vector__XXX
 SG_ GTW_w112_z4bDisabled m1 : 55|1@1+ (1,0) [0|1] "" Vector__XXX
 SG_ GTW_w113_unrecognizedCanMessage m1 : 56|1@1+ (1,0) [0|1] "" Vector__XXX
 SG_ GTW_w114_updtRetried m1 : 57|1@1+ (1,0) [0|1] "" Vector__XXX
 SG_ GTW_w115_hrlEventFileAvail m1 : 58|1@1+ (1,0) [0|1] "" Vector__XXX
 SG_ GTW_w116_switchInitFailed m1 : 59|1@1+ (1,0) [0|1] "" Vector__XXX
 SG_ GTW_w117_unexpectedDestructiveRe m1 : 60|1@1+ (1,0) [0|1] "" Vector__XXX
 SG_ GTW_w118_unexpectedFunctionalRes m1 : 61|1@1+ (1,0) [0|1] "" Vector__XXX
 SG_ GTW_w120_switchUnlocked m1 : 63|1@1+ (1,0) [0|1] "" Vector__XXX
 SG_ GTW_w122_BDY_canFault m2 : 5|1@1+ (1,0) [0|1] "" Vector__XXX
 SG_ GTW_w123_BDYbusOverloaded m2 : 6|1@1+ (1,0) [0|1] "" Vector__XXX
 SG_ GTW_w125_switchReplayUnlocked m2 : 8|1@1+ (1,0) [0|1] "" Vector__XXX
 SG_ GTW_w127_noFilePointersAvailable m2 : 10|1@1+ (1,0) [0|1] "" Vector__XXX
 SG_ GTW_w129_ICRversionMismatch m2 : 12|1@1+ (1,0) [0|1] "" Vector__XXX
 SG_ GTW_w133_adspFaultDetected m2 : 16|1@1+ (1,0) [0|1] "" Vector__XXX
 SG_ GTW_w134_disableFeatureFailed m2 : 17|1@1+ (1,0) [0|1] "" Vector__XXX
 SG_ GTW_w135_canLogQueueFull m2 : 18|1@1+ (1,0) [0|1] "" Vector__XXX
 SG_ GTW_w136_hrlGameModeFileAvail m2 : 19|1@1+ (1,0) [0|1] "" Vector__XXX
 SG_ GTW_w137_lowHeap m2 : 20|1@1+ (1,0) [0|1] "" Vector__XXX
 SG_ GTW_w138_sdCardEndOfLife m2 : 21|1@1+ (1,0) [0|1] "" Vector__XXX
 SG_ GTW_w139_CMPDversionMismatch m2 : 22|1@1+ (1,0) [0|1] "" Vector__XXX
 SG_ GTW_w140_cancoreHeartbeat m2 : 23|1@1+ (1,0) [0|1] "" Vector__XXX
 SG_ GTW_w141_teleCANETHis m2 : 24|1@1+ (1,0) [0|1] "" Vector__XXX
 SG_ GTW_w143_possibleCanWakeIssue m2 : 26|1@1+ (1,0) [0|1] "" Vector__XXX
 SG_ GTW_w144_hrlStateMachine m2 : 27|1@1+ (1,0) [0|1] "" Vector__XXX
 SG_ GTW_w145_carConfigsNotWritten m2 : 28|1@1+ (1,0) [0|1] "" Vector__XXX
 SG_ GTW_w146_performancePackageMisma m2 : 29|1@1+ (1,0) [0|1] "" Vector__XXX
 SG_ GTW_w147_updateAbortFor12v m2 : 30|1@1+ (1,0) [0|1] "" Vector__XXX
 SG_ GTW_w149_rtcTimeSetInPast m2 : 32|1@1+ (1,0) [0|1] "" Vector__XXX
 SG_ GTW_w150_HCM3LversionMismatch m2 : 33|1@1+ (1,0) [0|1] "" Vector__XXX
 SG_ GTW_w151_HCM3RversionMismatch m2 : 34|1@1+ (1,0) [0|1] "" Vector__XXX
 SG_ GTW_w153_externalRtcAlarmFailure m2 : 36|1@1+ (1,0) [0|1] "" Vector__XXX
 SG_ GTW_w155_PMversionMismatch m2 : 38|1@1+ (1,0) [0|1] "" Vector__XXX
 SG_ GTW_w165_USMversionMismatch m2 : 48|1@1+ (1,0) [0|1] "" Vector__XXX
 SG_ GTW_w166_nErrCanFaultVeh m2 : 49|1@1+ (1,0) [0|1] "" Vector__XXX
 SG_ GTW_w167_nErrCanFaultCh m2 : 50|1@1+ (1,0) [0|1] "" Vector__XXX
 SG_ GTW_w168_nErrCanFaultParty m2 : 51|1@1+ (1,0) [0|1] "" Vector__XXX
 SG_ GTW_w169_TPMSsoftWarnFrontLeft m2 : 52|1@1+ (1,0) [0|1] "" Vector__XXX
 SG_ GTW_w170_TPMSsoftWarnFrontRight m2 : 53|1@1+ (1,0) [0|1] "" Vector__XXX
 SG_ GTW_w171_TPMSsoftWarnRearLeft m2 : 54|1@1+ (1,0) [0|1] "" Vector__XXX
 SG_ GTW_w172_TPMSsoftWarnRearRight m2 : 55|1@1+ (1,0) [0|1] "" Vector__XXX
 SG_ GTW_w173_TPMShardWarnFrontLeft m2 : 56|1@1+ (1,0) [0|1] "" Vector__XXX
 SG_ GTW_w174_TPMShardWarnFrontRight m2 : 57|1@1+ (1,0) [0|1] "" Vector__XXX
 SG_ GTW_w175_TPMShardWarnRearLeft m2 : 58|1@1+ (1,0) [0|1] "" Vector__XXX
 SG_ GTW_w176_TPMShardWarnRearRight m2 : 59|1@1+ (1,0) [0|1] "" Vector__XXX
 SG_ GTW_w186_swrPrecaution m3 : 9|1@1+ (1,0) [0|1] "" Vector__XXX
 SG_ GTW_w218_switchOTPIncorrect m3 : 41|1@1+ (1,0) [0|1] "" Vector__XXX
 SG_ GTW_w219_CMPSversionMismatch m3 : 42|1@1+ (1,0) [0|1] "" Vector__XXX
 SG_ GTW_w223_LVBMSversionMismatch m3 : 46|1@1+ (1,0) [0|1] "" Vector__XXX
 SG_ GTW_w224_sdCardUpgradeNeeded m3 : 47|1@1+ (1,0) [0|1] "" Vector__XXX
 SG_ GTW_w225_resetOnSleepWake m3 : 48|1@1+ (1,0) [0|1] "" Vector__XXX
 SG_ GTW_w226_DISPversionMismatch m3 : 49|1@1+ (1,0) [0|1] "" Vector__XXX
 SG_ GTW_w227_DISPTOUCHversionMismatc m3 : 50|1@1+ (1,0) [0|1] "" Vector__XXX
 SG_ GTW_w228_DISPOSDversionMismatch m3 : 51|1@1+ (1,0) [0|1] "" Vector__XXX
 SG_ GTW_w229_displaySoftsetConnectio m3 : 52|1@1+ (1,0) [0|1] "" Vector__XXX
 SG_ GTW_w230_touchInterruptStorm m3 : 53|1@1+ (1,0) [0|1] "" Vector__XXX
 SG_ GTW_w244_SDCRversionMismatch m4 : 7|1@1+ (1,0) [0|1] "" Vector__XXX
 SG_ GTW_w245_apsNotDisabled m4 : 8|1@1+ (1,0) [0|1] "" Vector__XXX
 SG_ GTW_w246_touchcoreHeartbeat m4 : 9|1@1+ (1,0) [0|1] "" Vector__XXX
 SG_ GTW_w255_rtc32KHzWatchdog m4 : 18|1@1+ (1,0) [0|1] "" Vector__XXX
 SG_ GTW_w260_unknownPN m4 : 23|1@1+ (1,0) [0|1] "" Vector__XXX
 SG_ GTW_w261_adspWatchdog m4 : 24|1@1+ (1,0) [0|1] "" Vector__XXX
 SG_ GTW_w262_canLogBlockDropped m4 : 25|1@1+ (1,0) [0|1] "" Vector__XXX
 SG_ GTW_w263_hrlUdpFileAvail m4 : 26|1@1+ (1,0) [0|1] "" Vector__XXX
 SG_ GTW_w264_hrlPseudoFileAvail m4 : 27|1@1+ (1,0) [0|1] "" Vector__XXX
 SG_ GTW_w265_optionFlagsError m4 : 28|1@1+ (1,0) [0|1] "" Vector__XXX
 SG_ GTW_w266_dpp1MIA m4 : 29|1@1+ (1,0) [0|1] "" Vector__XXX
 SG_ GTW_w267_dpp2MIA m4 : 30|1@1+ (1,0) [0|1] "" Vector__XXX
 SG_ GTW_w268_stoMIA m4 : 31|1@1+ (1,0) [0|1] "" Vector__XXX
 SG_ GTW_w273_BLEEPREARLEFTversionMis m4 : 36|1@1+ (1,0) [0|1] "" Vector__XXX
 SG_ GTW_w274_BLEEPREARRIGHTversionMi m4 : 37|1@1+ (1,0) [0|1] "" Vector__XXX
 SG_ GTW_w275_VDDCORE_DrMOS_Fault m4 : 38|1@1+ (1,0) [0|1] "" Vector__XXX
 SG_ GTW_w276_VDDSOC_DrMOS_Fault m4 : 39|1@1+ (1,0) [0|1] "" Vector__XXX
 SG_ GTW_w277_NonRevCDrMOSMitigationF m4 : 40|1@1+ (1,0) [0|1] "" Vector__XXX
 SG_ GTW_w278_ethSwitchCongested m4 : 41|1@1+ (1,0) [0|1] "" Vector__XXX
 SG_ GTW_w279_adspRepeatedWatchdog m4 : 42|1@1+ (1,0) [0|1] "" Vector__XXX
 SG_ GTW_w280_hrlFrameDropped m4 : 43|1@1+ (1,0) [0|1] "" Vector__XXX
 SG_ GTW_w281_likelyMissedPoke m4 : 44|1@1+ (1,0) [0|1] "" Vector__XXX
 SG_ GTW_w282_tcuPhyConfigurationFail m4 : 45|1@1+ (1,0) [0|1] "" Vector__XXX
 SG_ GTW_w309_VCUSBversionMismatch m5 : 12|1@1+ (1,0) [0|1] "" Vector__XXX
 SG_ GTW_w311_canLogQueueFullBeforeFs m5 : 14|1@1+ (1,0) [0|1] "" Vector__XXX
 SG_ GTW_w312_hrlFileIncomplete m5 : 15|1@1+ (1,0) [0|1] "" Vector__XXX
 SG_ GTW_w313_OSDActive m5 : 16|1@1+ (1,0) [0|1] "" Vector__XXX
 SG_ GTW_w314_canLogBlockWriteErr m5 : 17|1@1+ (1,0) [0|1] "" Vector__XXX
 SG_ GTW_w316_sdCardChkdskRepair m5 : 19|1@1+ (1,0) [0|1] "" Vector__XXX
 SG_ GTW_w317_sdCardChkdskRepairFaile m5 : 20|1@1+ (1,0) [0|1] "" Vector__XXX
 SG_ GTW_w322_gestureUnrecognizedFrom m5 : 25|1@1+ (1,0) [0|1] "" Vector__XXX
 SG_ GTW_w323_gestureStartOutOfStrip m5 : 26|1@1+ (1,0) [0|1] "" Vector__XXX
 SG_ GTW_w328_smartShiftDisabled m5 : 31|1@1+ (1,0) [0|1] "" Vector__XXX
 SG_ GTW_w329_FOHMversionMismatch m5 : 32|1@1+ (1,0) [0|1] "" Vector__XXX
 SG_ GTW_w330_SWSLversionMismatch m5 : 33|1@1+ (1,0) [0|1] "" Vector__XXX
 SG_ GTW_w331_SWSRversionMismatch m5 : 34|1@1+ (1,0) [0|1] "" Vector__XXX
 SG_ GTW_w332_unknownDisplayPN m5 : 35|1@1+ (1,0) [0|1] "" Vector__XXX
 SG_ GTW_w334_hrlFolderSpaceLow m5 : 37|1@1+ (1,0) [0|1] "" Vector__XXX
 SG_ GTW_w336_possibleCanTxIssue m5 : 39|1@1+ (1,0) [0|1] "" Vector__XXX
 SG_ GTW_w342_VCBLDCPPversionMismatch m5 : 45|1@1+ (1,0) [0|1] "" Vector__XXX
 SG_ GTW_w348_VCBLDCFversionMismatch m5 : 51|1@1+ (1,0) [0|1] "" Vector__XXX
 SG_ GTW_w349_VCBLDCPBversionMismatch m5 : 52|1@1+ (1,0) [0|1] "" Vector__XXX
 SG_ GTW_w350_mOSDCrcCheck m5 : 53|1@1+ (1,0) [0|1] "" Vector__XXX
 SG_ GTW_w351_sOSDCrcCheck m5 : 54|1@1+ (1,0) [0|1] "" Vector__XXX
 SG_ GTW_w352_mASILStatusCheck m5 : 55|1@1+ (1,0) [0|1] "" Vector__XXX
 SG_ GTW_w353_sASILStatusCheck m5 : 56|1@1+ (1,0) [0|1] "" Vector__XXX
 SG_ GTW_w354_EPASTPversionMismatch m5 : 57|1@1+ (1,0) [0|1] "" Vector__XXX
 SG_ GTW_w355_EPASTSversionMismatch m5 : 58|1@1+ (1,0) [0|1] "" Vector__XXX
 SG_ GTW_w356_touchGPIOStatusCheck m5 : 59|1@1+ (1,0) [0|1] "" Vector__XXX
 SG_ GTW_w358_RGBIPFLversionMismatch m5 : 61|1@1+ (1,0) [0|1] "" Vector__XXX
 SG_ GTW_w359_RGBIPFRversionMismatch m5 : 62|1@1+ (1,0) [0|1] "" Vector__XXX
 SG_ GTW_w360_RGBDOORFLversionMismatc m5 : 63|1@1+ (1,0) [0|1] "" Vector__XXX
 SG_ GTW_w361_RGBDOORRLversionMismatc m6 : 4|1@1+ (1,0) [0|1] "" Vector__XXX
 SG_ GTW_w362_RGBDOORFRversionMismatc m6 : 5|1@1+ (1,0) [0|1] "" Vector__XXX
 SG_ GTW_w363_RGBDOORRRversionMismatc m6 : 6|1@1+ (1,0) [0|1] "" Vector__XXX
 SG_ GTW_w364_BLEEPCRADLEversionMisma m6 : 7|1@1+ (1,0) [0|1] "" Vector__XXX
 SG_ GTW_w366_uiGearRequestMismatch m6 : 9|1@1+ (1,0) [0|1] "" Vector__XXX
 SG_ GTW_w376_blFailedToExecBootImg m6 : 19|1@1+ (1,0) [0|1] "" Vector__XXX
 SG_ GTW_w380_DPBversionMismatch m6 : 23|1@1+ (1,0) [0|1] "" Vector__XXX
 SG_ GTW_w381_DPBCALversionMismatch m6 : 24|1@1+ (1,0) [0|1] "" Vector__XXX
 SG_ GTW_w382_IDBversionMismatch m6 : 25|1@1+ (1,0) [0|1] "" Vector__XXX
 SG_ GTW_w383_IDB1versionMismatch m6 : 26|1@1+ (1,0) [0|1] "" Vector__XXX
 SG_ GTW_w384_IDBCALversionMismatch m6 : 27|1@1+ (1,0) [0|1] "" Vector__XXX
 SG_ GTW_w385_RCUversionMismatch m6 : 28|1@1+ (1,0) [0|1] "" Vector__XXX
 SG_ GTW_w386_RCUCALversionMismatch m6 : 29|1@1+ (1,0) [0|1] "" Vector__XXX
 SG_ GTW_w387_externalRtcReadFailure m6 : 30|1@1+ (1,0) [0|1] "" Vector__XXX
 SG_ GTW_w388_adspWatchdogSkipped m6 : 31|1@1+ (1,0) [0|1] "" Vector__XXX
 SG_ GTW_w389_rcmEventDetected m6 : 32|1@1+ (1,0) [0|1] "" Vector__XXX
 SG_ GTW_w391_adspMacAddrCheckFailed m6 : 34|1@1+ (1,0) [0|1] "" Vector__XXX
 SG_ GTW_w393_osdSramCrcMismatch m6 : 36|1@1+ (1,0) [0|1] "" Vector__XXX
 SG_ GTW_w395_lwipIcmpError m6 : 38|1@1+ (1,0) [0|1] "" Vector__XXX
 SG_ GTW_w396_alreadyInReverse m6 : 39|1@1+ (1,0) [0|1] "" Vector__XXX
 SG_ GTW_w397_alreadyInDrive m6 : 40|1@1+ (1,0) [0|1] "" Vector__XXX
 SG_ GTW_w398_awakeForExtendedTime m6 : 41|1@1+ (1,0) [0|1] "" Vector__XXX
 SG_ GTW_w399_ethIfRxTcpipQueueDrop m6 : 42|1@1+ (1,0) [0|1] "" Vector__XXX
 SG_ GTW_w400_ethlSwitchOTPIncorrect m6 : 43|1@1+ (1,0) [0|1] "" Vector__XXX
 SG_ GTW_w409_unexpectedResetCause m6 : 52|1@1+ (1,0) [0|1] "" Vector__XXX
 SG_ GTW_w410_unexpectedResetCause2 m6 : 53|1@1+ (1,0) [0|1] "" Vector__XXX
 SG_ GTW_w414_socHeldInReset m6 : 57|1@1+ (1,0) [0|1] "" Vector__XXX

BO_ 838 GTW_autopilotOverride: 8 GTW
 SG_ GTW_autopilotOverrideState : 0|2@1+ (1,0) [0|3] "" Vector__XXX
 SG_ GTW_autopilotConfig : 2|3@1+ (1,0) [0|7] "" Vector__XXX
 SG_ GTW_autopilotOverrideConfig : 5|3@1+ (1,0) [0|7] "" Vector__XXX
 SG_ GTW_autopilotOverrideExpireTime : 32|32@1+ (1,0) [0|4294967295] "" Vector__XXX

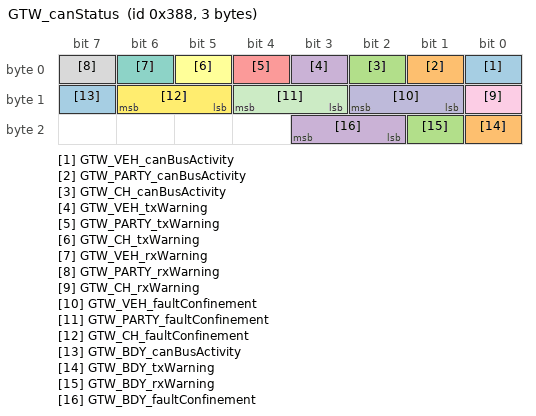
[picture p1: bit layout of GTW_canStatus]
BO_ 904 GTW_canStatus: 3 GTW
 SG_ GTW_VEH_canBusActivity : 0|1@1+ (1,0) [0|1] "" Vector__XXX
 SG_ GTW_PARTY_canBusActivity : 1|1@1+ (1,0) [0|1] "" Vector__XXX
 SG_ GTW_CH_canBusActivity : 2|1@1+ (1,0) [0|1] "" Vector__XXX
 SG_ GTW_VEH_txWarning : 3|1@1+ (1,0) [0|1] "" Vector__XXX
 SG_ GTW_PARTY_txWarning : 4|1@1+ (1,0) [0|1] "" Vector__XXX
 SG_ GTW_CH_txWarning : 5|1@1+ (1,0) [0|1] "" Vector__XXX
 SG_ GTW_VEH_rxWarning : 6|1@1+ (1,0) [0|1] "" Vector__XXX
 SG_ GTW_PARTY_rxWarning : 7|1@1+ (1,0) [0|1] "" Vector__XXX
 SG_ GTW_CH_rxWarning : 8|1@1+ (1,0) [0|1] "" Vector__XXX
 SG_ GTW_VEH_faultConfinement : 9|2@1+ (1,0) [0|3] "" Vector__XXX
 SG_ GTW_PARTY_faultConfinement : 11|2@1+ (1,0) [0|3] "" Vector__XXX
 SG_ GTW_CH_faultConfinement : 13|2@1+ (1,0) [0|3] "" Vector__XXX
 SG_ GTW_BDY_canBusActivity : 15|1@1+ (1,0) [0|1] "" Vector__XXX
 SG_ GTW_BDY_txWarning : 16|1@1+ (1,0) [0|1] "" Vector__XXX
 SG_ GTW_BDY_rxWarning : 17|1@1+ (1,0) [0|1] "" Vector__XXX
 SG_ GTW_BDY_faultConfinement : 18|2@1+ (1,0) [0|3] "" Vector__XXX

BO_TX_BU_ 1428 : EPASTS;
BO_TX_BU_ 920 : EPASTS;
BO_TX_BU_ 888 : GTW;
BO_TX_BU_ 282 : GTW;
BO_TX_BU_ 1384 : GTW;
BO_TX_BU_ 62 : GTW;
BO_TX_BU_ 838 : GTW;
BO_TX_BU_ 904 : GTW;
CM_ BO_ 1428 "EPASTS ECU message: alert log";
CM_ SG_ 1428 EPASTS_alertID "EPASTS ECU: alert ID";
CM_ SG_ 1428 EPASTS_alertState "EPASTS ECU: alert state";
CM_ SG_ 1428 EPASTS_a001_debugInfo "EPASTS ECU: a001 debug info";
CM_ SG_ 1428 EPASTS_a002_debugInfo "EPASTS ECU: a002 debug info";
CM_ SG_ 1428 EPASTS_a003_debugInfo "EPASTS ECU: a003 debug info";
CM_ SG_ 1428 EPASTS_a004_debugInfo "EPASTS ECU: a004 debug info";
CM_ SG_ 1428 EPASTS_a005_debugInfo "EPASTS ECU: a005 debug info";
CM_ SG_ 1428 EPASTS_a006_debugInfo "EPASTS ECU: a006 debug info";
CM_ SG_ 1428 EPASTS_a007_debugInfo "EPASTS ECU: a007 debug info";
CM_ SG_ 1428 EPASTS_a009_debugInfo "EPASTS ECU: a009 debug info";
CM_ SG_ 1428 EPASTS_a010_debugInfo "EPASTS ECU: a010 debug info";
CM_ SG_ 1428 EPASTS_a011_debugInfo "EPASTS ECU: a011 debug info";
CM_ SG_ 1428 EPASTS_a012_debugInfo "EPASTS ECU: a012 debug info";
CM_ SG_ 1428 EPASTS_a013_debugInfo "EPASTS ECU: a013 debug info";
CM_ SG_ 1428 EPASTS_a014_debugInfo "EPASTS ECU: a014 debug info";
CM_ SG_ 1428 EPASTS_a015_debugInfo "EPASTS ECU: a015 debug info";
CM_ SG_ 1428 EPASTS_a016_debugInfo "EPASTS ECU: a016 debug info";
CM_ SG_ 1428 EPASTS_a017_debugInfo "EPASTS ECU: a017 debug info";
CM_ SG_ 1428 EPASTS_a018_debugInfo "EPASTS ECU: a018 debug info";
CM_ SG_ 1428 EPASTS_a019_debugInfo "EPASTS ECU: a019 debug info";
CM_ SG_ 1428 EPASTS_a020_debugInfo "EPASTS ECU: a020 debug info";
CM_ SG_ 1428 EPASTS_a021_debugInfo "EPASTS ECU: a021 debug info";
CM_ SG_ 1428 EPASTS_a022_debugInfo "EPASTS ECU: a022 debug info";
CM_ SG_ 1428 EPASTS_a023_debugInfo "EPASTS ECU: a023 debug info";
CM_ SG_ 1428 EPASTS_a024_debugInfo "EPASTS ECU: a024 debug info";
CM_ SG_ 1428 EPASTS_a025_debugInfo "EPASTS ECU: a025 debug info";
CM_ SG_ 1428 EPASTS_a026_debugInfo "EPASTS ECU: a026 debug info";
CM_ SG_ 1428 EPASTS_a027_debugInfo "EPASTS ECU: a027 debug info";
CM_ SG_ 1428 EPASTS_a028_debugInfo "EPASTS ECU: a028 debug info";
CM_ SG_ 1428 EPASTS_a029_debugInfo "EPASTS ECU: a029 debug info";
CM_ SG_ 1428 EPASTS_a030_debugInfo "EPASTS ECU: a030 debug info";
CM_ SG_ 1428 EPASTS_a031_debugInfo "EPASTS ECU: a031 debug info";
CM_ SG_ 1428 EPASTS_a032_debugInfo "EPASTS ECU: a032 debug info";
CM_ SG_ 1428 EPASTS_a033_debugInfo "EPASTS ECU: a033 debug info";
CM_ SG_ 1428 EPASTS_a034_debugInfo "EPASTS ECU: a034 debug info";
CM_ SG_ 1428 EPASTS_a035_debugInfo "EPASTS ECU: a035 debug info";
CM_ SG_ 1428 EPASTS_a036_debugInfo "EPASTS ECU: a036 debug info";
CM_ SG_ 1428 EPASTS_a037_debugInfo "EPASTS ECU: a037 debug info";
CM_ SG_ 1428 EPASTS_a038_debugInfo "EPASTS ECU: a038 debug info";
CM_ SG_ 1428 EPASTS_a039_debugInfo "EPASTS ECU: a039 debug info";
CM_ SG_ 1428 EPASTS_a040_debugInfo "EPASTS ECU: a040 debug info";
CM_ SG_ 1428 EPASTS_a041_debugInfo "EPASTS ECU: a041 debug info";
CM_ SG_ 1428 EPASTS_a042_debugInfo "EPASTS ECU: a042 debug info";
CM_ SG_ 1428 EPASTS_a043_debugInfo "EPASTS ECU: a043 debug info";
CM_ SG_ 1428 EPASTS_a044_debugInfo "EPASTS ECU: a044 debug info";
CM_ SG_ 1428 EPASTS_a045_debugInfo "EPASTS ECU: a045 debug info";
CM_ SG_ 1428 EPASTS_a046_debugInfo "EPASTS ECU: a046 debug info";
CM_ SG_ 1428 EPASTS_a047_debugInfo "EPASTS ECU: a047 debug info";
CM_ SG_ 1428 EPASTS_a048_debugInfo "EPASTS ECU: a048 debug info";
CM_ SG_ 1428 EPASTS_a049_debugInfo "EPASTS ECU: a049 debug info";
CM_ SG_ 1428 EPASTS_a050_debugInfo "EPASTS ECU: a050 debug info";
CM_ SG_ 1428 EPASTS_a051_debugInfo "EPASTS ECU: a051 debug info";
CM_ SG_ 1428 EPASTS_a052_debugInfo "EPASTS ECU: a052 debug info";
CM_ SG_ 1428 EPASTS_a053_debugInfo "EPASTS ECU: a053 debug info";
CM_ SG_ 1428 EPASTS_a054_debugInfo "EPASTS ECU: a054 debug info";
CM_ SG_ 1428 EPASTS_a055_debugInfo "EPASTS ECU: a055 debug info";
CM_ SG_ 1428 EPASTS_a056_debugInfo "EPASTS ECU: a056 debug info";
CM_ SG_ 1428 EPASTS_a057_debugInfo "EPASTS ECU: a057 debug info";
CM_ SG_ 1428 EPASTS_a058_debugInfo "EPASTS ECU: a058 debug info";
CM_ SG_ 1428 EPASTS_a059_debugInfo "EPASTS ECU: a059 debug info";
CM_ SG_ 1428 EPASTS_a060_debugInfo "EPASTS ECU: a060 debug info";
CM_ SG_ 1428 EPASTS_a061_debugInfo "EPASTS ECU: a061 debug info";
CM_ SG_ 1428 EPASTS_a062_debugInfo "EPASTS ECU: a062 debug info";
CM_ SG_ 1428 EPASTS_a063_debugInfo "EPASTS ECU: a063 debug info";
CM_ SG_ 1428 EPASTS_a064_debugInfo "EPASTS ECU: a064 debug info";
CM_ SG_ 1428 EPASTS_a065_debugInfo "EPASTS ECU: a065 debug info";
CM_ SG_ 1428 EPASTS_a066_debugInfo "EPASTS ECU: a066 debug info";
CM_ SG_ 1428 EPASTS_a067_debugInfo "EPASTS ECU: a067 debug info";
CM_ SG_ 1428 EPASTS_a068_debugInfo "EPASTS ECU: a068 debug info";
CM_ SG_ 1428 EPASTS_a069_debugInfo "EPASTS ECU: a069 debug info";
CM_ SG_ 1428 EPASTS_a070_debugInfo "EPASTS ECU: a070 debug info";
CM_ SG_ 1428 EPASTS_a071_debugInfo "EPASTS ECU: a071 debug info";
CM_ SG_ 1428 EPASTS_a072_debugInfo "EPASTS ECU: a072 debug info";
CM_ SG_ 1428 EPASTS_a073_debugInfo "EPASTS ECU: a073 debug info";
CM_ SG_ 1428 EPASTS_a074_debugInfo "EPASTS ECU: a074 debug info";
CM_ SG_ 1428 EPASTS_a075_debugInfo "EPASTS ECU: a075 debug info";
CM_ SG_ 1428 EPASTS_a076_debugInfo "EPASTS ECU: a076 debug info";
CM_ SG_ 1428 EPASTS_a077_debugInfo "EPASTS ECU: a077 debug info";
CM_ SG_ 1428 EPASTS_a078_debugInfo "EPASTS ECU: a078 debug info";
CM_ SG_ 1428 EPASTS_a079_debugInfo "EPASTS ECU: a079 debug info";
CM_ SG_ 1428 EPASTS_a080_debugInfo "EPASTS ECU: a080 debug info";
CM_ SG_ 1428 EPASTS_a081_debugInfo "EPASTS ECU: a081 debug info";
CM_ SG_ 1428 EPASTS_a082_debugInfo "EPASTS ECU: a082 debug info";
CM_ SG_ 1428 EPASTS_a083_debugInfo "EPASTS ECU: a083 debug info";
CM_ SG_ 1428 EPASTS_a084_debugInfo "EPASTS ECU: a084 debug info";
CM_ SG_ 1428 EPASTS_a085_debugInfo "EPASTS ECU: a085 debug info";
CM_ SG_ 1428 EPASTS_a086_debugInfo "EPASTS ECU: a086 debug info";
CM_ SG_ 1428 EPASTS_a087_debugInfo "EPASTS ECU: a087 debug info";
CM_ SG_ 1428 EPASTS_a088_debugInfo "EPASTS ECU: a088 debug info";
CM_ SG_ 1428 EPASTS_a089_debugInfo "EPASTS ECU: a089 debug info";
CM_ SG_ 1428 EPASTS_a090_debugInfo "EPASTS ECU: a090 debug info";
CM_ SG_ 1428 EPASTS_a091_debugInfo "EPASTS ECU: a091 debug info";
CM_ SG_ 1428 EPASTS_a092_debugInfo "EPASTS ECU: a092 debug info";
CM_ SG_ 1428 EPASTS_a093_debugInfo "EPASTS ECU: a093 debug info";
CM_ SG_ 1428 EPASTS_a094_debugInfo "EPASTS ECU: a094 debug info";
CM_ SG_ 1428 EPASTS_a095_debugInfo "EPASTS ECU: a095 debug info";
CM_ SG_ 1428 EPASTS_a096_debugInfo "EPASTS ECU: a096 debug info";
CM_ SG_ 1428 EPASTS_a097_debugInfo "EPASTS ECU: a097 debug info";
CM_ SG_ 1428 EPASTS_a098_debugInfo "EPASTS ECU: a098 debug info";
CM_ SG_ 1428 EPASTS_a099_debugInfo "EPASTS ECU: a099 debug info";
CM_ SG_ 1428 EPASTS_a100_debugInfo "EPASTS ECU: a100 debug info";
CM_ SG_ 1428 EPASTS_a101_debugInfo "EPASTS ECU: a101 debug info";
CM_ SG_ 1428 EPASTS_a102_debugInfo "EPASTS ECU: a102 debug info";
CM_ SG_ 1428 EPASTS_a103_debugInfo "EPASTS ECU: a103 debug info";
CM_ SG_ 1428 EPASTS_a104_debugInfo "EPASTS ECU: a104 debug info";
CM_ SG_ 1428 EPASTS_a105_debugInfo "EPASTS ECU: a105 debug info";
CM_ SG_ 1428 EPASTS_a106_debugInfo "EPASTS ECU: a106 debug info";
CM_ SG_ 1428 EPASTS_a107_debugInfo "EPASTS ECU: a107 debug info";
CM_ SG_ 1428 EPASTS_a108_debugInfo "EPASTS ECU: a108 debug info";
CM_ SG_ 1428 EPASTS_a109_debugInfo "EPASTS ECU: a109 debug info";
CM_ SG_ 1428 EPASTS_a110_debugInfo "EPASTS ECU: a110 debug info";
CM_ SG_ 1428 EPASTS_a111_debugInfo "EPASTS ECU: a111 debug info";
CM_ SG_ 1428 EPASTS_a112_debugInfo "EPASTS ECU: a112 debug info";
CM_ SG_ 1428 EPASTS_a113_debugInfo "EPASTS ECU: a113 debug info";
CM_ SG_ 1428 EPASTS_a114_debugInfo "EPASTS ECU: a114 debug info";
CM_ SG_ 1428 EPASTS_a115_debugInfo "EPASTS ECU: a115 debug info";
CM_ SG_ 1428 EPASTS_a116_debugInfo "EPASTS ECU: a116 debug info";
CM_ SG_ 1428 EPASTS_a117_debugInfo "EPASTS ECU: a117 debug info";
CM_ SG_ 1428 EPASTS_a118_debugInfo "EPASTS ECU: a118 debug info";
CM_ SG_ 1428 EPASTS_a119_debugInfo "EPASTS ECU: a119 debug info";
CM_ SG_ 1428 EPASTS_a120_debugInfo "EPASTS ECU: a120 debug info";
CM_ SG_ 1428 EPASTS_a121_debugInfo "EPASTS ECU: a121 debug info";
CM_ SG_ 1428 EPASTS_a122_debugInfo "EPASTS ECU: a122 debug info";
CM_ SG_ 1428 EPASTS_a123_debugInfo "EPASTS ECU: a123 debug info";
CM_ SG_ 1428 EPASTS_a124_debugInfo "EPASTS ECU: a124 debug info";
CM_ SG_ 1428 EPASTS_a125_debugInfo "EPASTS ECU: a125 debug info";
CM_ SG_ 1428 EPASTS_a126_debugInfo "EPASTS ECU: a126 debug info";
CM_ SG_ 1428 EPASTS_a127_debugInfo "EPASTS ECU: a127 debug info";
CM_ SG_ 1428 EPASTS_a128_debugInfo "EPASTS ECU: a128 debug info";
CM_ SG_ 1428 EPASTS_a129_debugInfo "EPASTS ECU: a129 debug info";
CM_ SG_ 1428 EPASTS_a130_debugInfo "EPASTS ECU: a130 debug info";
CM_ SG_ 1428 EPASTS_a131_debugInfo "EPASTS ECU: a131 debug info";
CM_ SG_ 1428 EPASTS_a132_debugInfo "EPASTS ECU: a132 debug info";
CM_ SG_ 1428 EPASTS_a133_debugInfo "EPASTS ECU: a133 debug info";
CM_ SG_ 1428 EPASTS_a134_debugInfo "EPASTS ECU: a134 debug info";
CM_ SG_ 1428 EPASTS_a135_debugInfo "EPASTS ECU: a135 debug info";
CM_ SG_ 1428 EPASTS_a136_debugInfo "EPASTS ECU: a136 debug info";
CM_ SG_ 1428 EPASTS_a137_debugInfo "EPASTS ECU: a137 debug info";
CM_ SG_ 1428 EPASTS_a138_debugInfo "EPASTS ECU: a138 debug info";
CM_ SG_ 1428 EPASTS_a139_debugInfo "EPASTS ECU: a139 debug info";
CM_ SG_ 1428 EPASTS_a140_debugInfo "EPASTS ECU: a140 debug info";
CM_ SG_ 1428 EPASTS_a141_debugInfo "EPASTS ECU: a141 debug info";
CM_ SG_ 1428 EPASTS_a142_debugInfo "EPASTS ECU: a142 debug info";
CM_ SG_ 1428 EPASTS_a143_debugInfo "EPASTS ECU: a143 debug info";
CM_ SG_ 1428 EPASTS_a144_debugInfo "EPASTS ECU: a144 debug info";
CM_ SG_ 1428 EPASTS_a145_debugInfo "EPASTS ECU: a145 debug info";
CM_ SG_ 1428 EPASTS_a146_debugInfo "EPASTS ECU: a146 debug info";
CM_ SG_ 1428 EPASTS_a147_debugInfo "EPASTS ECU: a147 debug info";
CM_ SG_ 1428 EPASTS_a148_debugInfo "EPASTS ECU: a148 debug info";
CM_ SG_ 1428 EPASTS_a149_debugInfo "EPASTS ECU: a149 debug info";
CM_ SG_ 1428 EPASTS_a150_debugInfo "EPASTS ECU: a150 debug info";
CM_ SG_ 1428 EPASTS_a152_debugInfo "EPASTS ECU: a152 debug info";
CM_ SG_ 1428 EPASTS_a153_debugInfo "EPASTS ECU: a153 debug info";
CM_ SG_ 1428 EPASTS_a154_debugInfo "EPASTS ECU: a154 debug info";
CM_ SG_ 1428 EPASTS_a155_debugInfo "EPASTS ECU: a155 debug info";
CM_ SG_ 1428 EPASTS_a156_debugInfo "EPASTS ECU: a156 debug info";
CM_ SG_ 1428 EPASTS_a157_debugInfo "EPASTS ECU: a157 debug info";
CM_ SG_ 1428 EPASTS_a158_debugInfo "EPASTS ECU: a158 debug info";
CM_ SG_ 1428 EPASTS_a159_debugInfo "EPASTS ECU: a159 debug info";
CM_ SG_ 1428 EPASTS_a160_debugInfo "EPASTS ECU: a160 debug info";
CM_ SG_ 1428 EPASTS_a161_debugInfo "EPASTS ECU: a161 debug info";
CM_ SG_ 1428 EPASTS_a162_debugInfo "EPASTS ECU: a162 debug info";
CM_ SG_ 1428 EPASTS_a163_debugInfo "EPASTS ECU: a163 debug info";
CM_ SG_ 1428 EPASTS_a164_debugInfo "EPASTS ECU: a164 debug info";
CM_ SG_ 1428 EPASTS_a165_debugInfo "EPASTS ECU: a165 debug info";
CM_ SG_ 1428 EPASTS_a166_debugInfo "EPASTS ECU: a166 debug info";
CM_ SG_ 1428 EPASTS_a167_debugInfo "EPASTS ECU: a167 debug info";
CM_ SG_ 1428 EPASTS_a168_debugInfo "EPASTS ECU: a168 debug info";
CM_ SG_ 1428 EPASTS_a169_debugInfo "EPASTS ECU: a169 debug info";
CM_ SG_ 1428 EPASTS_a170_debugInfo "EPASTS ECU: a170 debug info";
CM_ SG_ 1428 EPASTS_a171_debugInfo "EPASTS ECU: a171 debug info";
CM_ SG_ 1428 EPASTS_a172_debugInfo "EPASTS ECU: a172 debug info";
CM_ SG_ 1428 EPASTS_a173_debugInfo "EPASTS ECU: a173 debug info";
CM_ SG_ 1428 EPASTS_a174_debugInfo "EPASTS ECU: a174 debug info";
CM_ SG_ 1428 EPASTS_a175_debugInfo "EPASTS ECU: a175 debug info";
CM_ SG_ 1428 EPASTS_a176_debugInfo "EPASTS ECU: a176 debug info";
CM_ SG_ 1428 EPASTS_a177_debugInfo "EPASTS ECU: a177 debug info";
CM_ SG_ 1428 EPASTS_a178_debugInfo "EPASTS ECU: a178 debug info";
CM_ SG_ 1428 EPASTS_a179_debugInfo "EPASTS ECU: a179 debug info";
CM_ SG_ 1428 EPASTS_a180_debugInfo "EPASTS ECU: a180 debug info";
CM_ SG_ 1428 EPASTS_a181_debugInfo "EPASTS ECU: a181 debug info";
CM_ SG_ 1428 EPASTS_a182_debugInfo "EPASTS ECU: a182 debug info";
CM_ SG_ 1428 EPASTS_a183_debugInfo "EPASTS ECU: a183 debug info";
CM_ SG_ 1428 EPASTS_a184_debugInfo "EPASTS ECU: a184 debug info";
CM_ SG_ 1428 EPASTS_a185_debugInfo "EPASTS ECU: a185 debug info";
CM_ SG_ 1428 EPASTS_a186_debugInfo "EPASTS ECU: a186 debug info";
CM_ SG_ 1428 EPASTS_a188_debugInfo "EPASTS ECU: a188 debug info";
CM_ SG_ 1428 EPASTS_a189_debugInfo "EPASTS ECU: a189 debug info";
CM_ SG_ 1428 EPASTS_a190_debugInfo "EPASTS ECU: a190 debug info";
CM_ SG_ 1428 EPASTS_a191_debugInfo "EPASTS ECU: a191 debug info";
CM_ SG_ 1428 EPASTS_a192_debugInfo "EPASTS ECU: a192 debug info";
CM_ SG_ 1428 EPASTS_a193_debugInfo "EPASTS ECU: a193 debug info";
CM_ SG_ 1428 EPASTS_a194_debugInfo "EPASTS ECU: a194 debug info";
CM_ SG_ 1428 EPASTS_a195_debugInfo "EPASTS ECU: a195 debug info";
CM_ SG_ 1428 EPASTS_a196_debugInfo "EPASTS ECU: a196 debug info";
CM_ SG_ 1428 EPASTS_a197_debugInfo "EPASTS ECU: a197 debug info";
CM_ SG_ 1428 EPASTS_a198_debugInfo "EPASTS ECU: a198 debug info";
CM_ SG_ 1428 EPASTS_a199_debugInfo "EPASTS ECU: a199 debug info";
CM_ SG_ 1428 EPASTS_a200_debugInfo "EPASTS ECU: a200 debug info";
CM_ SG_ 1428 EPASTS_a201_debugInfo "EPASTS ECU: a201 debug info";
CM_ SG_ 1428 EPASTS_a202_debugInfo "EPASTS ECU: a202 debug info";
CM_ SG_ 1428 EPASTS_a203_debugInfo "EPASTS ECU: a203 debug info";
CM_ SG_ 1428 EPASTS_a204_debugInfo "EPASTS ECU: a204 debug info";
CM_ SG_ 1428 EPASTS_a205_debugInfo "EPASTS ECU: a205 debug info";
CM_ SG_ 1428 EPASTS_a206_debugInfo "EPASTS ECU: a206 debug info";
CM_ SG_ 1428 EPASTS_a207_debugInfo "EPASTS ECU: a207 debug info";
CM_ SG_ 1428 EPASTS_a208_debugInfo "EPASTS ECU: a208 debug info";
CM_ SG_ 1428 EPASTS_a209_debugInfo "EPASTS ECU: a209 debug info";
CM_ SG_ 1428 EPASTS_a210_debugInfo "EPASTS ECU: a210 debug info";
CM_ SG_ 1428 EPASTS_a211_debugInfo "EPASTS ECU: a211 debug info";
CM_ SG_ 1428 EPASTS_a212_debugInfo "EPASTS ECU: a212 debug info";
CM_ SG_ 1428 EPASTS_a213_debugInfo "EPASTS ECU: a213 debug info";
CM_ SG_ 1428 EPASTS_a214_debugInfo "EPASTS ECU: a214 debug info";
CM_ SG_ 1428 EPASTS_a215_debugInfo "EPASTS ECU: a215 debug info";
CM_ SG_ 1428 EPASTS_a216_debugInfo "EPASTS ECU: a216 debug info";
CM_ SG_ 1428 EPASTS_a217_debugInfo "EPASTS ECU: a217 debug info";
CM_ SG_ 1428 EPASTS_a218_debugInfo "EPASTS ECU: a218 debug info";
CM_ SG_ 1428 EPASTS_a219_debugInfo "EPASTS ECU: a219 debug info";
CM_ SG_ 1428 EPASTS_a220_debugInfo "EPASTS ECU: a220 debug info";
CM_ SG_ 1428 EPASTS_a221_debugInfo "EPASTS ECU: a221 debug info";
CM_ SG_ 1428 EPASTS_a222_debugInfo "EPASTS ECU: a222 debug info";
CM_ SG_ 1428 EPASTS_a223_debugInfo "EPASTS ECU: a223 debug info";
CM_ SG_ 1428 EPASTS_a224_debugInfo "EPASTS ECU: a224 debug info";
CM_ SG_ 1428 EPASTS_a225_debugInfo "EPASTS ECU: a225 debug info";
CM_ SG_ 1428 EPASTS_a226_debugInfo "EPASTS ECU: a226 debug info";
CM_ SG_ 1428 EPASTS_a227_debugInfo "EPASTS ECU: a227 debug info";
CM_ SG_ 1428 EPASTS_a228_debugInfo "EPASTS ECU: a228 debug info";
CM_ SG_ 1428 EPASTS_a229_debugInfo "EPASTS ECU: a229 debug info";
CM_ SG_ 1428 EPASTS_a230_debugInfo "EPASTS ECU: a230 debug info";
CM_ SG_ 1428 EPASTS_a231_debugInfo "EPASTS ECU: a231 debug info";
CM_ SG_ 1428 EPASTS_a232_debugInfo "EPASTS ECU: a232 debug info";
CM_ SG_ 1428 EPASTS_a233_debugInfo "EPASTS ECU: a233 debug info";
CM_ SG_ 1428 EPASTS_a234_debugInfo "EPASTS ECU: a234 debug info";
CM_ SG_ 1428 EPASTS_a235_debugInfo "EPASTS ECU: a235 debug info";
CM_ SG_ 1428 EPASTS_a236_debugInfo "EPASTS ECU: a236 debug info";
CM_ SG_ 1428 EPASTS_a237_debugInfo "EPASTS ECU: a237 debug info";
CM_ SG_ 1428 EPASTS_a238_debugInfo "EPASTS ECU: a238 debug info";
CM_ SG_ 1428 EPASTS_a239_debugInfo "EPASTS ECU: a239 debug info";
CM_ SG_ 1428 EPASTS_a240_debugInfo "EPASTS ECU: a240 debug info";
CM_ SG_ 1428 EPASTS_a241_debugInfo "EPASTS ECU: a241 debug info";
CM_ SG_ 1428 EPASTS_a242_debugInfo "EPASTS ECU: a242 debug info";
CM_ SG_ 1428 EPASTS_a243_debugInfo "EPASTS ECU: a243 debug info";
CM_ SG_ 1428 EPASTS_a244_debugInfo "EPASTS ECU: a244 debug info";
CM_ SG_ 1428 EPASTS_a245_debugInfo "EPASTS ECU: a245 debug info";
CM_ SG_ 1428 EPASTS_a246_debugInfo "EPASTS ECU: a246 debug info";
CM_ SG_ 1428 EPASTS_a247_debugInfo "EPASTS ECU: a247 debug info";
CM_ SG_ 1428 EPASTS_a248_debugInfo "EPASTS ECU: a248 debug info";
CM_ SG_ 1428 EPASTS_a249_debugInfo "EPASTS ECU: a249 debug info";
CM_ SG_ 1428 EPASTS_a250_debugInfo "EPASTS ECU: a250 debug info";
CM_ SG_ 1428 EPASTS_a251_debugInfo "EPASTS ECU: a251 debug info";
CM_ SG_ 1428 EPASTS_a252_debugInfo "EPASTS ECU: a252 debug info";
CM_ SG_ 1428 EPASTS_a253_debugInfo "EPASTS ECU: a253 debug info";
CM_ SG_ 1428 EPASTS_a254_debugInfo "EPASTS ECU: a254 debug info";
CM_ SG_ 1428 EPASTS_a255_debugInfo "EPASTS ECU: a255 debug info";
CM_ SG_ 1428 EPASTS_a256_debugInfo "EPASTS ECU: a256 debug info";
CM_ SG_ 1428 EPASTS_a257_debugInfo "EPASTS ECU: a257 debug info";
CM_ SG_ 1428 EPASTS_a258_debugInfo "EPASTS ECU: a258 debug info";
CM_ SG_ 1428 EPASTS_a259_debugInfo "EPASTS ECU: a259 debug info";
CM_ SG_ 1428 EPASTS_a260_debugInfo "EPASTS ECU: a260 debug info";
CM_ SG_ 1428 EPASTS_a261_debugInfo "EPASTS ECU: a261 debug info";
CM_ SG_ 1428 EPASTS_a262_debugInfo "EPASTS ECU: a262 debug info";
CM_ SG_ 1428 EPASTS_a263_debugInfo "EPASTS ECU: a263 debug info";
CM_ SG_ 1428 EPASTS_a264_degradedECU "EPASTS ECU: a264 degraded ECU";
CM_ SG_ 1428 EPASTS_a264_vehicleSpeed "EPASTS ECU: a264 vehicle speed";
CM_ SG_ 1428 EPASTS_a264_powerRatio "EPASTS ECU: a264 power ratio";
CM_ SG_ 1428 EPASTS_a264_ownSideDegradationRe "EPASTS ECU: a264 own side degradation reason";
CM_ SG_ 1428 EPASTS_a264_otherSideDegradation "EPASTS ECU: a264 other side degradation reason";
CM_ SG_ 1428 EPASTS_a265_degradedECU "EPASTS ECU: a265 degraded ECU";
CM_ SG_ 1428 EPASTS_a265_vehicleSpeed "EPASTS ECU: a265 vehicle speed";
CM_ SG_ 1428 EPASTS_a265_rawMcuTemperature "EPASTS ECU: a265 raw mcu temperature";
CM_ SG_ 1428 EPASTS_a265_degradedCurrentLimit "EPASTS ECU: a265 degraded current limit";
CM_ SG_ 1428 EPASTS_a266_cdpAssistFactor "EPASTS ECU: a266 cdp assist factor";
CM_ SG_ 1428 EPASTS_a266_vehicleSpeed "EPASTS ECU: a266 vehicle speed";
CM_ SG_ 1428 EPASTS_a267_vehicleSpeed "EPASTS ECU: a267 vehicle speed";
CM_ SG_ 1428 EPASTS_a267_velocityEstimatorSta "EPASTS ECU: a267 velocity estimator state";
CM_ SG_ 1428 EPASTS_a269_vehicleSpeed "EPASTS ECU: a269 vehicle speed";
CM_ SG_ 1428 EPASTS_a270_debugInfo "EPASTS ECU: a270 debug info";
CM_ BO_ 920 "EPASTS ECU message: alert matrix";
CM_ SG_ 920 EPASTS_matrixIndex "EPASTS ECU: matrix index";
CM_ SG_ 920 EPASTS_a001_adcCalibrationOrInit "EPASTS ECU: a001 adc calibration or init fail";
CM_ SG_ 920 EPASTS_a002_adcMuxErr "EPASTS ECU: a002 adc mux err";
CM_ SG_ 920 EPASTS_a003_pspInvalidParamset "EPASTS ECU: a003 psp invalid paramset";
CM_ SG_ 920 EPASTS_a004_scpInputMia "EPASTS ECU: a004 scp input mia";
CM_ SG_ 920 EPASTS_a005_scpUnknownResetSourc "EPASTS ECU: a005 scp unknown reset source";
CM_ SG_ 920 EPASTS_a006_swrhResetByInvalidEr "EPASTS ECU: a006 swrh reset by invalid errid";
CM_ SG_ 920 EPASTS_a007_tsmcCoreTempDiff "EPASTS ECU: a007 tsmc core temp diff";
CM_ SG_ 920 EPASTS_a008_psdcPlatformShutdown "EPASTS ECU: a008 psdc platform shutdown";
CM_ SG_ 920 EPASTS_a009_mcusscLbistPermanent "EPASTS ECU: a009 mcussc lbist permanent fail";
CM_ SG_ 920 EPASTS_a010_svcIncompatibleSwVer "EPASTS ECU: a010 svc incompatible sw versions";
CM_ SG_ 920 EPASTS_a011_mcusscMonbistErr "EPASTS ECU: a011 mcussc monbist err";
CM_ SG_ 920 EPASTS_a012_mcusscMbistEccErr "EPASTS ECU: a012 mcussc mbist ecc err";
CM_ SG_ 920 EPASTS_a013_mcusscSffMonitoringF "EPASTS ECU: a013 mcussc sff monitoring failed";
CM_ SG_ 920 EPASTS_a014_mcusscSffMonitoringM "EPASTS ECU: a014 mcussc sff monitoring mia";
CM_ SG_ 920 EPASTS_a015_mcusscCsErrorCheckFa "EPASTS ECU: a015 mcussc cs error check fail";
CM_ SG_ 920 EPASTS_a016_mcufcCsErrorCheckFai "EPASTS ECU: a016 mcufc cs error check fail";
CM_ SG_ 920 EPASTS_a017_stmdStmPlausibilityC "EPASTS ECU: a017 stmd stm plausibility check err";
CM_ SG_ 920 EPASTS_a018_exchCsErrorCheck "EPASTS ECU: a018 exch cs error check";
CM_ SG_ 920 EPASTS_a019_rsthHwResetInfoCorru "EPASTS ECU: a019 rsth hw reset info corruption check";
CM_ SG_ 920 EPASTS_a020_mcusscEolEcuIdIntegr "EPASTS ECU: a020 mcussc eol ecu id integritiy fail";
CM_ SG_ 920 EPASTS_a021_osehCsErrorCheck "EPASTS ECU: a021 oseh cs error check";
CM_ SG_ 920 EPASTS_a022_swrhSwResetInfoCorru "EPASTS ECU: a022 swrh sw reset info corruption check";
CM_ SG_ 920 EPASTS_a023_btarcCorruptionCheck "EPASTS ECU: a023 btarc corruption check";
CM_ SG_ 920 EPASTS_a024_srhCsErrorCheckFail "EPASTS ECU: a024 srh cs error check fail";
CM_ SG_ 920 EPASTS_a025_btarcCorruptionCheck "EPASTS ECU: a025 btarc corruption check";
CM_ SG_ 920 EPASTS_a026_mrccCsErrorCheckFail "EPASTS ECU: a026 mrcc cs error check fail";
CM_ SG_ 920 EPASTS_a027_mcusscDmuHfErr "EPASTS ECU: a027 mcussc dmu hf err";
CM_ SG_ 920 EPASTS_a028_smuhNonInitDataCorru "EPASTS ECU: a028 smuh non init data corruption";
CM_ SG_ 920 EPASTS_a029_smuhSmuCoreCntErrorT "EPASTS ECU: a029 smuh smu core cnt error test fail";
CM_ SG_ 920 EPASTS_a030_rsthClockReset "EPASTS ECU: a030 rsth clock reset";
CM_ SG_ 920 EPASTS_a031_pmsProductionModeFai "EPASTS ECU: a031 pms production mode failed";
CM_ SG_ 920 EPASTS_a032_eolpEolCheckFailed "EPASTS ECU: a032 eolp eol check failed";
CM_ SG_ 920 EPASTS_a033_icsvcPswVersionMisma "EPASTS ECU: a033 icsvc psw version mismatch";
CM_ SG_ 920 EPASTS_a034_sbchReadbackRegFail "EPASTS ECU: a034 sbch readback reg fail";
CM_ SG_ 920 EPASTS_a035_sbchChipIdFail "EPASTS ECU: a035 sbch chip id fail";
CM_ SG_ 920 EPASTS_a036_sbcmSbcBistFailed "EPASTS ECU: a036 sbcm sbc bist failed";
CM_ SG_ 920 EPASTS_a037_epmV5P2Fail "EPASTS ECU: a037 epm V5 P2 fail";
CM_ SG_ 920 EPASTS_a038_csohCh1CsErrorErrAtR "EPASTS ECU: a038 csoh ch1 cs error err at reset";
CM_ SG_ 920 EPASTS_a039_csohCh2CsErrorErrAtR "EPASTS ECU: a039 csoh ch2 cs error err at reset";
CM_ SG_ 920 EPASTS_a040_swrhLimitedResetRetr "EPASTS ECU: a040 swrh limited reset retries expired";
CM_ SG_ 920 EPASTS_a041_imcmCoreConfiguratio "EPASTS ECU: a041 imcm core configuration mismatch";
CM_ SG_ 920 EPASTS_a042_wdhWdTestFail "EPASTS ECU: a042 wdh wd test fail";
CM_ SG_ 920 EPASTS_a043_sbcmWdStateDisabled "EPASTS ECU: a043 sbcm wd state disabled";
CM_ SG_ 920 EPASTS_a044_sbcmSbcEepromFail "EPASTS ECU: a044 sbcm sbc eeprom fail";
CM_ SG_ 920 EPASTS_a045_psumSbcBandgapVoltEr "EPASTS ECU: a045 psum sbc bandgap volt err";
CM_ SG_ 920 EPASTS_a046_mcusscOscillatorNotR "EPASTS ECU: a046 mcussc oscillator not reliable";
CM_ SG_ 920 EPASTS_a047_epmVregVoltFail "EPASTS ECU: a047 epm vreg volt fail";
CM_ SG_ 920 EPASTS_a048_epmVcpVoltFail "EPASTS ECU: a048 epm vcp volt fail";
CM_ SG_ 920 EPASTS_a049_epmLgFail "EPASTS ECU: a049 epm lg fail";
CM_ SG_ 920 EPASTS_a050_erlErr "EPASTS ECU: a050 erl err";
CM_ SG_ 920 EPASTS_a051_ermMessageErr "EPASTS ECU: a051 erm message err";
CM_ SG_ 920 EPASTS_a052_ermSdcInputBufferOve "EPASTS ECU: a052 erm sdc input buffer overflow";
CM_ SG_ 920 EPASTS_a053_adcUnexpectedNumOfDa "EPASTS ECU: a053 adc unexpected num of data";
CM_ SG_ 920 EPASTS_a054_adcUnexpectedData "EPASTS ECU: a054 adc unexpected data";
CM_ SG_ 920 EPASTS_a055_amExtendedGduTest "EPASTS ECU: a055 am extended gdu test";
CM_ SG_ 920 EPASTS_a056_amGduConfigCsErrorCh "EPASTS ECU: a056 am gdu config cs error check";
CM_ SG_ 920 EPASTS_a057_amGduVds "EPASTS ECU: a057 am gdu vds";
CM_ SG_ 920 EPASTS_a058_amIntVgsUndervtgErr "EPASTS ECU: a058 am int vgs undervtg err";
CM_ SG_ 920 EPASTS_a059_amStartupTestFailed "EPASTS ECU: a059 am startup test failed";
CM_ SG_ 920 EPASTS_a060_amGduFail "EPASTS ECU: a060 am gdu fail";
CM_ SG_ 920 EPASTS_a061_amIntSerialErr "EPASTS ECU: a061 am int serial err";
CM_ SG_ 920 EPASTS_a062_amPhaseBridgeCheck "EPASTS ECU: a062 am phase bridge check";
CM_ SG_ 920 EPASTS_a063_amIntRegulatorErr "EPASTS ECU: a063 am int regulator err";
CM_ SG_ 920 EPASTS_a064_amBridgeShort "EPASTS ECU: a064 am bridge short";
CM_ SG_ 920 EPASTS_a065_amGduJuncTemp "EPASTS ECU: a065 am gdu junc temp";
CM_ SG_ 920 EPASTS_a066_amVoltQfErr "EPASTS ECU: a066 am volt qf err";
CM_ SG_ 920 EPASTS_a067_tspmPowermoduleTempI "EPASTS ECU: a067 tspm powermodule temp implausible";
CM_ SG_ 920 EPASTS_a068_rsthCoreRedundancyEr "EPASTS ECU: a068 rsth core redundancy err";
CM_ SG_ 920 EPASTS_a069_rsthCoreTempOutOfRan "EPASTS ECU: a069 rsth core temp out of range hw check";
CM_ SG_ 920 EPASTS_a070_rsthInternalLowVolt "EPASTS ECU: a070 rsth internal low volt";
CM_ SG_ 920 EPASTS_a071_rsthInternalHighVolt "EPASTS ECU: a071 rsth internal high volt";
CM_ SG_ 920 EPASTS_a072_rsthFlashUncorrEccOr "EPASTS ECU: a072 rsth flash uncorr ecc or ovfl";
CM_ SG_ 920 EPASTS_a073_rsthOtherEdcEcc "EPASTS ECU: a073 rsth other edc ecc";
CM_ SG_ 920 EPASTS_a074_rsthUnexpectedAlarm "EPASTS ECU: a074 rsth unexpected alarm";
CM_ SG_ 920 EPASTS_a075_rsthUnusedOtherModul "EPASTS ECU: a075 rsth unused other module alarm";
CM_ SG_ 920 EPASTS_a076_exchGeneralException "EPASTS ECU: a076 exch general exception";
CM_ SG_ 920 EPASTS_a077_dmDeadlineViolation "EPASTS ECU: a077 dm deadline violation";
CM_ SG_ 920 EPASTS_a078_dmDeadlineViolation "EPASTS ECU: a078 dm deadline violation";
CM_ SG_ 920 EPASTS_a079_gduhComErr "EPASTS ECU: a079 gduh com err";
CM_ SG_ 920 EPASTS_a080_pwmTimerSyncCheck "EPASTS ECU: a080 pwm timer sync check";
CM_ SG_ 920 EPASTS_a081_exchFloatingPointExc "EPASTS ECU: a081 exch floating point exception";
CM_ SG_ 920 EPASTS_a082_adcTriggerTimeChk "EPASTS ECU: a082 adc trigger time chk";
CM_ SG_ 920 EPASTS_a083_tdaDclinkcapacitorTe "EPASTS ECU: a083 tda dclinkcapacitor temp checker";
CM_ SG_ 920 EPASTS_a084_adcTriggerCheck "EPASTS ECU: a084 adc trigger check";
CM_ SG_ 920 EPASTS_a085_amGduSwitchOffTestBy "EPASTS ECU: a085 am gdu switch off test by mcu";
CM_ SG_ 920 EPASTS_a086_rsthRamUncorrEcc "EPASTS ECU: a086 rsth ram uncorr ecc";
CM_ SG_ 920 EPASTS_a087_rsthFlashConfigErr "EPASTS ECU: a087 rsth flash config err";
CM_ SG_ 920 EPASTS_a088_tedMainboardTempChec "EPASTS ECU: a088 ted mainboard temp checker";
CM_ SG_ 920 EPASTS_a089_tedRevercebattfetjun "EPASTS ECU: a089 ted revercebattfetjunction temp checker";
CM_ SG_ 920 EPASTS_a090_etsmWarning "EPASTS ECU: a090 etsm warning";
CM_ SG_ 920 EPASTS_a091_bvpBattVoltCrossChkF "EPASTS ECU: a091 bvp batt volt cross chk failed";
CM_ SG_ 920 EPASTS_a092_amGduSwitchOffTestBy "EPASTS ECU: a092 am gdu switch off test by sbc";
CM_ SG_ 920 EPASTS_a093_sctpTsuSingleStaticF "EPASTS ECU: a093 sctp tsu single static fail";
CM_ SG_ 920 EPASTS_a094_sctpTsuMultipleStati "EPASTS ECU: a094 sctp tsu multiple static fail";
CM_ SG_ 920 EPASTS_a095_mdModelBasedMotorInt "EPASTS ECU: a095 md model based motor integrity check";
CM_ SG_ 920 EPASTS_a096_rppRpsSingleStaticFa "EPASTS ECU: a096 rpp rps single static fail";
CM_ SG_ 920 EPASTS_a097_rppRpsMultipleStatic "EPASTS ECU: a097 rpp rps multiple static fail";
CM_ SG_ 920 EPASTS_a098_invErr "EPASTS ECU: a098 inv err";
CM_ SG_ 920 EPASTS_a099_mcdTorqueMismatchFau "EPASTS ECU: a099 mcd torque mismatch fault";
CM_ SG_ 920 EPASTS_a100_amVbrgLssFault "EPASTS ECU: a100 am vbrg lss fault";
CM_ SG_ 920 EPASTS_a101_sdrvSpcIdMismatch "EPASTS ECU: a101 sdrv spc id mismatch";
CM_ SG_ 920 EPASTS_a102_amPhasecurrentQosErr "EPASTS ECU: a102 am phasecurrent qos err";
CM_ SG_ 920 EPASTS_a103_exhaUnusedInterruptC "EPASTS ECU: a103 exha unused interrupt call exception";
CM_ SG_ 920 EPASTS_a104_exhaBusMpuException "EPASTS ECU: a104 exha bus mpu exception";
CM_ SG_ 920 EPASTS_a105_exhaSriBusErrExcepti "EPASTS ECU: a105 exha sri bus err exception";
CM_ SG_ 920 EPASTS_a106_exhaSpbBusErrExcepti "EPASTS ECU: a106 exha spb bus err exception";
CM_ SG_ 920 EPASTS_a107_exhaOtherNmiExceptio "EPASTS ECU: a107 exha other nmi exception";
CM_ SG_ 920 EPASTS_a108_exhaInternalProtecti "EPASTS ECU: a108 exha internal protection exception";
CM_ SG_ 920 EPASTS_a109_exhaSysBusOrPeriphEr "EPASTS ECU: a109 exha sys bus or periph err exception";
CM_ SG_ 920 EPASTS_a110_amPhaseRelaySwitchOf "EPASTS ECU: a110 am phase relay switch off test";
CM_ SG_ 920 EPASTS_a111_amCurrentSensingDisc "EPASTS ECU: a111 am current sensing disconnection";
CM_ SG_ 920 EPASTS_a112_rsthSafetyFlipflopEr "EPASTS ECU: a112 rsth safety flipflop err";
CM_ SG_ 920 EPASTS_a113_rsthUncorrectableEnd "EPASTS ECU: a113 rsth uncorrectable end to end bus err";
CM_ SG_ 920 EPASTS_a114_osehOsErr "EPASTS ECU: a114 oseh os err";
CM_ SG_ 920 EPASTS_a115_mcusscLbistSingleFai "EPASTS ECU: a115 mcussc lbist single fail";
CM_ SG_ 920 EPASTS_a116_mrccStartupRegCsErro "EPASTS ECU: a116 mrcc startup reg cs error static err";
CM_ SG_ 920 EPASTS_a117_mrccStartupRegCsErro "EPASTS ECU: a117 mrcc startup reg cs error transient err";
CM_ SG_ 920 EPASTS_a118_mcusscFlashCsErrorEr "EPASTS ECU: a118 mcussc flash cs error err";
CM_ SG_ 920 EPASTS_a119_mcusscFlashEccCritic "EPASTS ECU: a119 mcussc flash ecc critical err";
CM_ SG_ 920 EPASTS_a120_mcusscFlashEccLatent "EPASTS ECU: a120 mcussc flash ecc latent err";
CM_ SG_ 920 EPASTS_a121_mcusscMbistEccErr "EPASTS ECU: a121 mcussc mbist ecc err";
CM_ SG_ 920 EPASTS_a122_pcpBridgeFetShort "EPASTS ECU: a122 pcp bridge fet short";
CM_ SG_ 920 EPASTS_a123_imcmCommErr "EPASTS ECU: a123 imcm comm err";
CM_ SG_ 920 EPASTS_a124_mcusscMbistEccTransi "EPASTS ECU: a124 mcussc mbist ecc transient err";
CM_ SG_ 920 EPASTS_a125_mcusscMbistMiaErr "EPASTS ECU: a125 mcussc mbist mia err";
CM_ SG_ 920 EPASTS_a126_mcusscMonbistMiaErr "EPASTS ECU: a126 mcussc monbist mia err";
CM_ SG_ 920 EPASTS_a127_exchAdditionalExcept "EPASTS ECU: a127 exch additional exception after rst";
CM_ SG_ 920 EPASTS_a128_exchExceptionStopRes "EPASTS ECU: a128 exch exception stop restart";
CM_ SG_ 920 EPASTS_a129_exchAdditionalExcept "EPASTS ECU: a129 exch additional exception stop restart";
CM_ SG_ 920 EPASTS_a130_mrccConfigCsErrorErr "EPASTS ECU: a130 mrcc config cs error err";
CM_ SG_ 920 EPASTS_a131_exchGuardedResetAfte "EPASTS ECU: a131 exch guarded reset after partition stop";
CM_ SG_ 920 EPASTS_a132_mcusscNotSupportedMc "EPASTS ECU: a132 mcussc not supported mcu";
CM_ SG_ 920 EPASTS_a133_mcusscLbistEcuIdIsNo "EPASTS ECU: a133 mcussc lbist ecu id is not supported";
CM_ SG_ 920 EPASTS_a134_osehGuardedResetAfte "EPASTS ECU: a134 oseh guarded reset after err without reset";
CM_ SG_ 920 EPASTS_a135_tmpsfetjCalculationO "EPASTS ECU: a135 tmpsfetj calculation overflow err";
CM_ SG_ 920 EPASTS_a136_ftElectricalAngleQf "EPASTS ECU: a136 ft electrical angle qf";
CM_ SG_ 920 EPASTS_a137_osehErrWithoutImmedi "EPASTS ECU: a137 oseh err without immediate reset";
CM_ SG_ 920 EPASTS_a138_osehAdditionalErrWit "EPASTS ECU: a138 oseh additional err without imm reset";
CM_ SG_ 920 EPASTS_a139_osehAdditionalOsErr "EPASTS ECU: a139 oseh additional os err";
CM_ SG_ 920 EPASTS_a140_imcmConfigurationErr "EPASTS ECU: a140 imcm configuration err";
CM_ SG_ 920 EPASTS_a141_amFetShortTest "EPASTS ECU: a141 am fet short test";
CM_ SG_ 920 EPASTS_a142_tedEmifilterDmcTempC "EPASTS ECU: a142 ted emifilter dmc temp checker";
CM_ SG_ 920 EPASTS_a143_tedEmifilterCmcTempC "EPASTS ECU: a143 ted emifilter cmc temp checker";
CM_ SG_ 920 EPASTS_a144_mriCoreRaminitFailed "EPASTS ECU: a144 mri core raminit failed";
CM_ SG_ 920 EPASTS_a145_mriPeripheralRaminit "EPASTS ECU: a145 mri peripheral raminit failed";
CM_ SG_ 920 EPASTS_a146_btarcRcCircuitCheck "EPASTS ECU: a146 btarc rc circuit check";
CM_ SG_ 920 EPASTS_a147_amDcLinkShortedFail "EPASTS ECU: a147 am dc link shorted fail";
CM_ SG_ 920 EPASTS_a148_mrccExitFromStandbyD "EPASTS ECU: a148 mrcc exit from standby detected";
CM_ SG_ 920 EPASTS_a149_amReversibleEmergenc "EPASTS ECU: a149 am reversible emergency off requested";
CM_ SG_ 920 EPASTS_a150_amExternalEmergencyO "EPASTS ECU: a150 am external emergency off requested";
CM_ SG_ 920 EPASTS_a151_amPermanentEmergency "EPASTS ECU: a151 am permanent emergency off requested";
CM_ SG_ 920 EPASTS_a152_exchFlashEccExceptio "EPASTS ECU: a152 exch flash ecc exception";
CM_ SG_ 920 EPASTS_a153_sdsmBlockSelectorInv "EPASTS ECU: a153 sdsm block selector invalid";
CM_ SG_ 920 EPASTS_a154_sdsmCsErrorInvalidPr "EPASTS ECU: a154 sdsm cs error invalid primary";
CM_ SG_ 920 EPASTS_a155_sdsmDataInvalidAll "EPASTS ECU: a155 sdsm data invalid all";
CM_ SG_ 920 EPASTS_a156_amIntSerialErrSafety "EPASTS ECU: a156 am int serial err safety reset";
CM_ SG_ 920 EPASTS_a157_mcudcpInvalidEcuId "EPASTS ECU: a157 mcudcp invalid ecu id";
CM_ SG_ 920 EPASTS_a158_amGduFailDuringRecov "EPASTS ECU: a158 am gdu fail during recovery";
CM_ SG_ 920 EPASTS_a159_exchFlashWordlineTra "EPASTS ECU: a159 exch flash wordline transient err";
CM_ SG_ 920 EPASTS_a160_rsthCpu1UnexpectedAl "EPASTS ECU: a160 rsth cpu1 unexpected alarm";
CM_ SG_ 920 EPASTS_a161_tdaRelayfetjunctionT "EPASTS ECU: a161 tda relayfetjunction temp checker";
CM_ SG_ 920 EPASTS_a162_tdaBridgefetjunction "EPASTS ECU: a162 tda bridgefetjunction temp checker";
CM_ SG_ 920 EPASTS_a163_tdaPowermoduleTempCh "EPASTS ECU: a163 tda powermodule temp checker";
CM_ SG_ 920 EPASTS_a164_tdaBattfetjunctionTe "EPASTS ECU: a164 tda battfetjunction temp checker";
CM_ SG_ 920 EPASTS_a165_tdaDcbusshuntTempChe "EPASTS ECU: a165 tda dcbusshunt temp checker";
CM_ SG_ 920 EPASTS_a166_tdaPhasecurrentshunt "EPASTS ECU: a166 tda phasecurrentshunt temp checker";
CM_ SG_ 920 EPASTS_a167_iccd1ErrQueueOverflo "EPASTS ECU: a167 iccd1 err queue overflow";
CM_ SG_ 920 EPASTS_a168_c1csInvalidC1App "EPASTS ECU: a168 c1cs invalid C1 app";
CM_ SG_ 920 EPASTS_a169_scpSafetyReset "EPASTS ECU: a169 scp safety reset";
CM_ SG_ 920 EPASTS_a170_pmpDcvoltAge "EPASTS ECU: a170 pmp dcvolt age";
CM_ SG_ 920 EPASTS_a171_pmpKgvalueAge "EPASTS ECU: a171 pmp kgvalue age";
CM_ SG_ 920 EPASTS_a172_pmpElangMotorcurrent "EPASTS ECU: a172 pmp elang motorcurrent age";
CM_ SG_ 920 EPASTS_a173_pmpRotorspeedAge "EPASTS ECU: a173 pmp rotorspeed age";
CM_ SG_ 920 EPASTS_a174_pmpPhasecurrentAge "EPASTS ECU: a174 pmp phasecurrent age";
CM_ SG_ 920 EPASTS_a175_exchFlashStoredConfi "EPASTS ECU: a175 exch flash stored config err";
CM_ SG_ 920 EPASTS_a176_exchCpu1ExceptionRes "EPASTS ECU: a176 exch cpu1 exception reset";
CM_ SG_ 920 EPASTS_a177_etsrInvalidated "EPASTS ECU: a177 etsr invalidated";
CM_ SG_ 920 EPASTS_a178_exchWdtException "EPASTS ECU: a178 exch wdt exception";
CM_ SG_ 920 EPASTS_a179_tedMotorcoilTempChec "EPASTS ECU: a179 ted motorcoil temp checker";
CM_ SG_ 920 EPASTS_a180_dmDeadlineViolationC "EPASTS ECU: a180 dm deadline violation C1";
CM_ SG_ 920 EPASTS_a181_dmDeadlineViolationC "EPASTS ECU: a181 dm deadline violation C1";
CM_ SG_ 920 EPASTS_a182_mcdInputMia "EPASTS ECU: a182 mcd input mia";
CM_ SG_ 920 EPASTS_a183_sbchCommErrSbcToMcu "EPASTS ECU: a183 sbch comm err sbc to mcu";
CM_ SG_ 920 EPASTS_a184_sbcmCommBufferOverfl "EPASTS ECU: a184 sbcm comm buffer overflow";
CM_ SG_ 920 EPASTS_a185_sbcscpQAWatchdogRese "EPASTS ECU: a185 sbcscp QA watchdog reset";
CM_ SG_ 920 EPASTS_a186_wdhCommBufferOverflo "EPASTS ECU: a186 wdh comm buffer overflow";
CM_ SG_ 920 EPASTS_a187_epmVoltFail "EPASTS ECU: a187 epm volt fail";
CM_ SG_ 920 EPASTS_a188_epmCommBufferOverflo "EPASTS ECU: a188 epm comm buffer overflow";
CM_ SG_ 920 EPASTS_a189_sbchCommErrMcuToSbc "EPASTS ECU: a189 sbch comm err mcu to sbc";
CM_ SG_ 920 EPASTS_a190_sbchCommBufferOverfl "EPASTS ECU: a190 sbch comm buffer overflow";
CM_ SG_ 920 EPASTS_a191_sbcscpVcp2VucVoltFai "EPASTS ECU: a191 sbcscp vcp2 vuc volt fail";
CM_ SG_ 920 EPASTS_a192_osumC0CsaNearFull "EPASTS ECU: a192 osum C0 csa near full";
CM_ SG_ 920 EPASTS_a193_osumC0StackNearFull "EPASTS ECU: a193 osum C0 stack near full";
CM_ SG_ 920 EPASTS_a194_amNvdataLoss "EPASTS ECU: a194 am nvdata loss";
CM_ SG_ 920 EPASTS_a195_imcmCommErrC1 "EPASTS ECU: a195 imcm comm err C1";
CM_ SG_ 920 EPASTS_a196_topEolTasOffsetInval "EPASTS ECU: a196 top eol tas offset invalid";
CM_ SG_ 920 EPASTS_a197_difpDifactorInvalid "EPASTS ECU: a197 difp difactor invalid";
CM_ SG_ 920 EPASTS_a198_osumC1CsaNearFull "EPASTS ECU: a198 osum C1 csa near full";
CM_ SG_ 920 EPASTS_a199_osumC1StackNearFull "EPASTS ECU: a199 osum C1 stack near full";
CM_ SG_ 920 EPASTS_a200_ammInputBufferOverfl "EPASTS ECU: a200 amm input buffer overflow";
CM_ SG_ 920 EPASTS_a201_ammOutputBufferOverf "EPASTS ECU: a201 amm output buffer overflow";
CM_ SG_ 920 EPASTS_a202_ohnvmpStoredOffsetLo "EPASTS ECU: a202 ohnvmp stored offset lost";
CM_ SG_ 920 EPASTS_a203_ctcInterfaceErr "EPASTS ECU: a203 ctc interface err";
CM_ SG_ 920 EPASTS_a204_fdpPrevTrqErr "EPASTS ECU: a204 fdp prev trq err";
CM_ SG_ 920 EPASTS_a205_fdrOclFail "EPASTS ECU: a205 fdr ocl fail";
CM_ SG_ 920 EPASTS_a206_fdrOclPartialBlockin "EPASTS ECU: a206 fdr ocl partial blocking";
CM_ SG_ 920 EPASTS_a207_fdrOclFreezing "EPASTS ECU: a207 fdr ocl freezing";
CM_ SG_ 920 EPASTS_a208_fdrLowSeverityBlocki "EPASTS ECU: a208 fdr low severity blocking";
CM_ SG_ 920 EPASTS_a209_fdrLowSeverityFreezi "EPASTS ECU: a209 fdr low severity freezing";
CM_ SG_ 920 EPASTS_a210_fdrTotalBlocking "EPASTS ECU: a210 fdr total blocking";
CM_ SG_ 920 EPASTS_a211_frmInternalErr "EPASTS ECU: a211 frm internal err";
CM_ SG_ 920 EPASTS_a212_frmDataLost "EPASTS ECU: a212 frm data lost";
CM_ SG_ 920 EPASTS_a213_frmHighFrictionDetec "EPASTS ECU: a213 frm high friction detected";
CM_ SG_ 920 EPASTS_a214_velInterfaceErr "EPASTS ECU: a214 vel interface err";
CM_ SG_ 920 EPASTS_a215_vsgSafeViolErr "EPASTS ECU: a215 vsg safe viol err";
CM_ SG_ 920 EPASTS_a216_isdgImproperShutdown "EPASTS ECU: a216 isdg improper shutdown";
CM_ SG_ 920 EPASTS_a217_msdMasterSilentErr "EPASTS ECU: a217 msd master silent err";
CM_ SG_ 920 EPASTS_a218_aadApplicationStateE "EPASTS ECU: a218 aad application state err";
CM_ SG_ 920 EPASTS_a219_frhFastRestartFailed "EPASTS ECU: a219 frh fast restart failed";
CM_ SG_ 920 EPASTS_a220_transceiverInputqueu "EPASTS ECU: a220 transceiver inputqueue overflow";
CM_ SG_ 920 EPASTS_a221_apsCntError "EPASTS ECU: a221 aps cnt error";
CM_ SG_ 920 EPASTS_a222_apsCsError "EPASTS ECU: a222 aps cs error";
CM_ SG_ 920 EPASTS_a223_apsMia "EPASTS ECU: a223 aps mia";
CM_ SG_ 920 EPASTS_a224_dasCntError "EPASTS ECU: a224 das cnt error";
CM_ SG_ 920 EPASTS_a225_dasCsError "EPASTS ECU: a225 das cs error";
CM_ SG_ 920 EPASTS_a226_dasMia "EPASTS ECU: a226 das mia";
CM_ SG_ 920 EPASTS_a227_dirTorqueCntError "EPASTS ECU: a227 dir torque cnt error";
CM_ SG_ 920 EPASTS_a228_dirTorqueCsError "EPASTS ECU: a228 dir torque cs error";
CM_ SG_ 920 EPASTS_a229_dirTorqueMia "EPASTS ECU: a229 dir torque mia";
CM_ SG_ 920 EPASTS_a230_diSpdCntError "EPASTS ECU: a230 di spd cnt error";
CM_ SG_ 920 EPASTS_a231_diSpdCsError "EPASTS ECU: a231 di spd cs error";
CM_ SG_ 920 EPASTS_a232_diSpdMia "EPASTS ECU: a232 di spd mia";
CM_ SG_ 920 EPASTS_a233_ecu1StatCntError "EPASTS ECU: a233 ecu1 stat cnt error";
CM_ SG_ 920 EPASTS_a234_ecu1StatCsError "EPASTS ECU: a234 ecu1 stat cs error";
CM_ SG_ 920 EPASTS_a235_ecu1StatMia "EPASTS ECU: a235 ecu1 stat mia";
CM_ SG_ 920 EPASTS_a236_espWrCntError "EPASTS ECU: a236 esp wr cnt error";
CM_ SG_ 920 EPASTS_a237_espWrCsError "EPASTS ECU: a237 esp wr cs error";
CM_ SG_ 920 EPASTS_a238_espWrMia "EPASTS ECU: a238 esp wr mia";
CM_ SG_ 920 EPASTS_a239_espWsCntError "EPASTS ECU: a239 esp ws cnt error";
CM_ SG_ 920 EPASTS_a240_espWsCsError "EPASTS ECU: a240 esp ws cs error";
CM_ SG_ 920 EPASTS_a241_espWsMia "EPASTS ECU: a241 esp ws mia";
CM_ SG_ 920 EPASTS_a242_gtwConfigMia "EPASTS ECU: a242 gtw config mia";
CM_ SG_ 920 EPASTS_a243_rcmCntError "EPASTS ECU: a243 rcm cnt error";
CM_ SG_ 920 EPASTS_a244_rcmCsError "EPASTS ECU: a244 rcm cs error";
CM_ SG_ 920 EPASTS_a245_rcmMia "EPASTS ECU: a245 rcm mia";
CM_ SG_ 920 EPASTS_a246_sccmCntError "EPASTS ECU: a246 sccm cnt error";
CM_ SG_ 920 EPASTS_a247_sccmCsError "EPASTS ECU: a247 sccm cs error";
CM_ SG_ 920 EPASTS_a248_sccmMia "EPASTS ECU: a248 sccm mia";
CM_ SG_ 920 EPASTS_a249_uiTuneReqCntError "EPASTS ECU: a249 ui tune req cnt error";
CM_ SG_ 920 EPASTS_a250_uiTuneReqCsError "EPASTS ECU: a250 ui tune req cs error";
CM_ SG_ 920 EPASTS_a251_uiTuneReqMia "EPASTS ECU: a251 ui tune req mia";
CM_ SG_ 920 EPASTS_a252_vcFrontCntError "EPASTS ECU: a252 vc front cnt error";
CM_ SG_ 920 EPASTS_a253_vcFrontCsError "EPASTS ECU: a253 vc front cs error";
CM_ SG_ 920 EPASTS_a254_vcFrontMia "EPASTS ECU: a254 vc front mia";
CM_ SG_ 920 EPASTS_a255_pmState2Mia "EPASTS ECU: a255 pm state2 mia";
CM_ SG_ 920 EPASTS_a256_dcvmOverVolt "EPASTS ECU: a256 dcvm over volt";
CM_ SG_ 920 EPASTS_a257_dcvmUnderVolt "EPASTS ECU: a257 dcvm under volt";
CM_ SG_ 920 EPASTS_a258_pspInvalidProjectPar "EPASTS ECU: a258 psp invalid project paramset";
CM_ SG_ 920 EPASTS_a259_scoCanBusOff "EPASTS ECU: a259 sco can bus off";
CM_ SG_ 920 EPASTS_a260_scoPrivateBusOff "EPASTS ECU: a260 sco private bus off";
CM_ SG_ 920 EPASTS_a261_sccmStatusError "EPASTS ECU: a261 sccm status error";
CM_ SG_ 920 EPASTS_a262_yawRateStatus "EPASTS ECU: a262 yaw rate status";
CM_ SG_ 920 EPASTS_a263_espWsStatus "EPASTS ECU: a263 esp ws status";
CM_ SG_ 920 EPASTS_a264_assistTorqueLimited "EPASTS ECU: a264 assist torque limited";
CM_ SG_ 920 EPASTS_a265_overheatProtect "EPASTS ECU: a265 overheat protect";
CM_ SG_ 920 EPASTS_a266_overloadProtect "EPASTS ECU: a266 overload protect";
CM_ SG_ 920 EPASTS_a267_safeSpeedAssist "EPASTS ECU: a267 safe speed assist";
CM_ SG_ 920 EPASTS_a268_eacCancelled "EPASTS ECU: a268 eac cancelled";
CM_ SG_ 920 EPASTS_a269_assistTorqueDisabled "EPASTS ECU: a269 assist torque disabled";
CM_ SG_ 920 EPASTS_a270_oscillationCompTrqLi "EPASTS ECU: a270 oscillation comp trq lim reached";
CM_ BO_ 888 "Gateway message: e call";
CM_ SG_ 888 GTW_GTW_SOS_ECALL_RQST "State of the GTW-SOS-ECALL-RQST pin";
CM_ SG_ 888 GTW_LTE_ECALL_LOCK "State of the LTE-ECALL-LOCK pin";
CM_ BO_ 282 "Gateway message: adc4";
CM_ SG_ 282 GTW_BKP_BATT_MON "Gateway: BKP BATT MON; raw 4095 = signal not available (SNA)";
CM_ SG_ 282 GTW_BKP_BATT_NTC_P "BKP_BATT_NTC_P pni voltage; raw 4095 = signal not available (SNA)";
CM_ SG_ 282 GTW_ECALL_GPS_ANT_BIAS "Gateway: ECALL GPS ANT BIAS; raw 4095 = signal not available (SNA)";
CM_ SG_ 282 GTW_ECALL_MIC_DIAG "ECALL_MIC_DIAG voltage; raw 4095 = signal not available (SNA)";
CM_ SG_ 282 GTW_SOS_ECALL_nRQST_BUF "SOS_ECALL_nRQST_BUF voltage; raw 4095 = signal not available (SNA)";
CM_ BO_ 1384 "Gateway message: alert log";
CM_ SG_ 1384 GTW_alertID "Gateway: alert ID";
CM_ SG_ 1384 GTW_alertState "Gateway: alert state";
CM_ SG_ 1384 GTW_a014_crcVersion "Gateway: a014 crc version";
CM_ SG_ 1384 GTW_a015_crcVersion "Gateway: a015 crc version";
CM_ SG_ 1384 GTW_a016_crcVersion "Gateway: a016 crc version";
CM_ SG_ 1384 GTW_a017_crcVersion "Gateway: a017 crc version";
CM_ SG_ 1384 GTW_a018_crcVersion "Gateway: a018 crc version";
CM_ SG_ 1384 GTW_a019_crcVersion "Gateway: a019 crc version";
CM_ SG_ 1384 GTW_a020_crcVersion "Gateway: a020 crc version";
CM_ SG_ 1384 GTW_a021_crcVersion "Gateway: a021 crc version";
CM_ SG_ 1384 GTW_a022_crcVersion "Gateway: a022 crc version";
CM_ SG_ 1384 GTW_a023_crcVersion "Gateway: a023 crc version";
CM_ SG_ 1384 GTW_a024_crcVersion "Gateway: a024 crc version";
CM_ SG_ 1384 GTW_a025_crcVersion "Gateway: a025 crc version";
CM_ SG_ 1384 GTW_a026_crcVersion "Gateway: a026 crc version";
CM_ SG_ 1384 GTW_a027_crcVersion "Gateway: a027 crc version";
CM_ SG_ 1384 GTW_a028_crcVersion "Gateway: a028 crc version";
CM_ SG_ 1384 GTW_a029_crcVersion "Gateway: a029 crc version";
CM_ SG_ 1384 GTW_a030_crcVersion "Gateway: a030 crc version";
CM_ SG_ 1384 GTW_a031_crcVersion "Gateway: a031 crc version";
CM_ SG_ 1384 GTW_a032_crcVersion "Gateway: a032 crc version";
CM_ SG_ 1384 GTW_a033_crcVersion "Gateway: a033 crc version";
CM_ SG_ 1384 GTW_a034_crcVersion "Gateway: a034 crc version";
CM_ SG_ 1384 GTW_a035_crcVersion "Gateway: a035 crc version";
CM_ SG_ 1384 GTW_a036_crcVersion "Gateway: a036 crc version";
CM_ SG_ 1384 GTW_a037_crcVersion "Gateway: a037 crc version";
CM_ SG_ 1384 GTW_a038_crcVersion "Gateway: a038 crc version";
CM_ SG_ 1384 GTW_a039_crcVersion "Gateway: a039 crc version";
CM_ SG_ 1384 GTW_a040_crcVersion "Gateway: a040 crc version";
CM_ SG_ 1384 GTW_a041_crcVersion "Gateway: a041 crc version";
CM_ SG_ 1384 GTW_a042_crcVersion "Gateway: a042 crc version";
CM_ SG_ 1384 GTW_a043_crcVersion "Gateway: a043 crc version";
CM_ SG_ 1384 GTW_a045_crcVersion "Gateway: a045 crc version";
CM_ SG_ 1384 GTW_a046_crcVersion "Gateway: a046 crc version";
CM_ SG_ 1384 GTW_a047_crcVersion "Gateway: a047 crc version";
CM_ SG_ 1384 GTW_a048_crcVersion "Gateway: a048 crc version";
CM_ SG_ 1384 GTW_a049_headerError "Gateway: a049 header error";
CM_ SG_ 1384 GTW_a054_crcVersion "Gateway: a054 crc version";
CM_ SG_ 1384 GTW_a055_crcVersion "Gateway: a055 crc version";
CM_ SG_ 1384 GTW_a062_bmpWatchdogReason "Gateway: a062 bmp watchdog reason";
CM_ SG_ 1384 GTW_a063_VEH_faultConfinement "Gateway: a063 VEH fault confinement";
CM_ SG_ 1384 GTW_a064_CH_faultConfinement "Gateway: a064 CH fault confinement";
CM_ SG_ 1384 GTW_a065_PARTY_faultConfinement "Gateway: a065 PARTY fault confinement";
CM_ SG_ 1384 GTW_a066_type "Gateway: a066 type";
CM_ SG_ 1384 GTW_a066_exceptionCfgId "Gateway: a066 exception cfg id";
CM_ SG_ 1384 GTW_a066_uptime "Gateway: a066 uptime";
CM_ SG_ 1384 GTW_a068_codeKeyMissing "Gateway: a068 code key missing";
CM_ SG_ 1384 GTW_a068_cmdKeyMissing "Gateway: a068 cmd key missing";
CM_ SG_ 1384 GTW_a069_sdIntStatusErrs "Gateway: a069 sd int status errs";
CM_ SG_ 1384 GTW_a069_sdTimeout "Gateway: a069 sd timeout";
CM_ SG_ 1384 GTW_a069_sdCmdErr "Gateway: a069 sd cmd err";
CM_ SG_ 1384 GTW_a069_sdWriteErr "Gateway: a069 sd write err";
CM_ SG_ 1384 GTW_a069_sdReadErr "Gateway: a069 sd read err";
CM_ SG_ 1384 GTW_a069_autoCmd12Err "Gateway: a069 auto cmd12 err";
CM_ SG_ 1384 GTW_a072_updtFailureMask "Gateway: a072 updt failure mask";
CM_ SG_ 1384 GTW_a077_bmpPmicErrorType "Gateway: a077 bmp pmic error type";
CM_ SG_ 1384 GTW_a078_loadPercent "Gateway: a078 load percent";
CM_ SG_ 1384 GTW_a079_loadPercent "Gateway: a079 load percent";
CM_ SG_ 1384 GTW_a080_loadPercent "Gateway: a080 load percent";
CM_ SG_ 1384 GTW_a081_canId "Gateway: a081 can id";
CM_ SG_ 1384 GTW_a081_ISOTPmsgType "Gateway: a081 ISOT pmsg type";
CM_ SG_ 1384 GTW_a081_udsSID "Gateway: a081 uds SID";
CM_ SG_ 1384 GTW_a097_crcVersion "Gateway: a097 crc version";
CM_ SG_ 1384 GTW_a098_crcVersion "Gateway: a098 crc version";
CM_ SG_ 1384 GTW_a099_crcVersion "Gateway: a099 crc version";
CM_ SG_ 1384 GTW_a100_crcVersion "Gateway: a100 crc version";
CM_ SG_ 1384 GTW_a101_switchStuck "Gateway: a101 switch stuck";
CM_ SG_ 1384 GTW_a101_ETH_SW_nINT "Gateway: a101 ETH SW n INT";
CM_ SG_ 1384 GTW_a106_crcVersion "Gateway: a106 crc version";
CM_ SG_ 1384 GTW_a107_crcVersion "Gateway: a107 crc version";
CM_ SG_ 1384 GTW_a108_crcVersion "Gateway: a108 crc version";
CM_ SG_ 1384 GTW_a113_bus "Gateway: a113 bus";
CM_ SG_ 1384 GTW_a113_id "Gateway: a113 id";
CM_ SG_ 1384 GTW_a117_MC_RGM_DES "Gateway: a117 MC RGM DES";
CM_ SG_ 1384 GTW_a118_MC_RGM_FES "Gateway: a118 MC RGM FES";
CM_ SG_ 1384 GTW_a122_BDY_faultConfinement "Gateway: a122 BDY fault confinement";
CM_ SG_ 1384 GTW_a129_crcVersion "Gateway: a129 crc version";
CM_ SG_ 1384 GTW_a138_sdLifetimeUsed "Gateway: a138 sd lifetime used";
CM_ SG_ 1384 GTW_a139_crcVersion "Gateway: a139 crc version";
CM_ SG_ 1384 GTW_a150_crcVersion "Gateway: a150 crc version";
CM_ SG_ 1384 GTW_a151_crcVersion "Gateway: a151 crc version";
CM_ SG_ 1384 GTW_a155_crcVersion "Gateway: a155 crc version";
CM_ SG_ 1384 GTW_a165_crcVersion "Gateway: a165 crc version";
CM_ SG_ 1384 GTW_a169_TPMS_pressureFL "Gateway: a169 TPMS pressure FL";
CM_ SG_ 1384 GTW_a170_TPMS_pressureFR "Gateway: a170 TPMS pressure FR";
CM_ SG_ 1384 GTW_a171_TPMS_pressureRL "Gateway: a171 TPMS pressure RL";
CM_ SG_ 1384 GTW_a172_TPMS_pressureRR "Gateway: a172 TPMS pressure RR";
CM_ SG_ 1384 GTW_a173_TPMS_pressureFL "Gateway: a173 TPMS pressure FL";
CM_ SG_ 1384 GTW_a174_TPMS_pressureFR "Gateway: a174 TPMS pressure FR";
CM_ SG_ 1384 GTW_a175_TPMS_pressureRL "Gateway: a175 TPMS pressure RL";
CM_ SG_ 1384 GTW_a176_TPMS_pressureRR "Gateway: a176 TPMS pressure RR";
CM_ SG_ 1384 GTW_a219_crcVersion "Gateway: a219 crc version";
CM_ SG_ 1384 GTW_a223_crcVersion "Gateway: a223 crc version";
CM_ SG_ 1384 GTW_a226_crcVersion "Gateway: a226 crc version";
CM_ SG_ 1384 GTW_a227_crcVersion "Gateway: a227 crc version";
CM_ SG_ 1384 GTW_a228_crcVersion "Gateway: a228 crc version";
CM_ SG_ 1384 GTW_a244_crcVersion "Gateway: a244 crc version";
CM_ SG_ 1384 GTW_a245_page0ControlValue "Gateway: a245 page0 control value";
CM_ SG_ 1384 GTW_a245_page1ControlValue "Gateway: a245 page1 control value";
CM_ SG_ 1384 GTW_a261_failureReason "Gateway: a261 failure reason";
CM_ SG_ 1384 GTW_a261_failureData1 "Gateway: a261 failure data1";
CM_ SG_ 1384 GTW_a261_failureData2 "Gateway: a261 failure data2";
CM_ SG_ 1384 GTW_a273_crcVersion "Gateway: a273 crc version";
CM_ SG_ 1384 GTW_a274_crcVersion "Gateway: a274 crc version";
CM_ SG_ 1384 GTW_a277_mitigationFailureReason "Gateway: a277 mitigation failure reason";
CM_ SG_ 1384 GTW_a279_repeatCount "Gateway: a279 repeat count";
CM_ SG_ 1384 GTW_a279_failureReason "Gateway: a279 failure reason";
CM_ SG_ 1384 GTW_a279_failureData1 "Gateway: a279 failure data1";
CM_ SG_ 1384 GTW_a279_failureData2 "Gateway: a279 failure data2";
CM_ SG_ 1384 GTW_a309_crcVersion "Gateway: a309 crc version";
CM_ SG_ 1384 GTW_a317_status "Gateway: a317 status";
CM_ SG_ 1384 GTW_a317_errorCode "Gateway: a317 error code";
CM_ SG_ 1384 GTW_a329_crcVersion "Gateway: a329 crc version";
CM_ SG_ 1384 GTW_a330_crcVersion "Gateway: a330 crc version";
CM_ SG_ 1384 GTW_a331_crcVersion "Gateway: a331 crc version";
CM_ SG_ 1384 GTW_a342_crcVersion "Gateway: a342 crc version";
CM_ SG_ 1384 GTW_a348_crcVersion "Gateway: a348 crc version";
CM_ SG_ 1384 GTW_a349_crcVersion "Gateway: a349 crc version";
CM_ SG_ 1384 GTW_a354_crcVersion "Gateway: a354 crc version";
CM_ SG_ 1384 GTW_a355_crcVersion "Gateway: a355 crc version";
CM_ SG_ 1384 GTW_a358_crcVersion "Gateway: a358 crc version";
CM_ SG_ 1384 GTW_a359_crcVersion "Gateway: a359 crc version";
CM_ SG_ 1384 GTW_a360_crcVersion "Gateway: a360 crc version";
CM_ SG_ 1384 GTW_a361_crcVersion "Gateway: a361 crc version";
CM_ SG_ 1384 GTW_a362_crcVersion "Gateway: a362 crc version";
CM_ SG_ 1384 GTW_a363_crcVersion "Gateway: a363 crc version";
CM_ SG_ 1384 GTW_a364_crcVersion "Gateway: a364 crc version";
CM_ SG_ 1384 GTW_a380_crcVersion "Gateway: a380 crc version";
CM_ SG_ 1384 GTW_a381_crcVersion "Gateway: a381 crc version";
CM_ SG_ 1384 GTW_a382_crcVersion "Gateway: a382 crc version";
CM_ SG_ 1384 GTW_a383_crcVersion "Gateway: a383 crc version";
CM_ SG_ 1384 GTW_a384_crcVersion "Gateway: a384 crc version";
CM_ SG_ 1384 GTW_a385_crcVersion "Gateway: a385 crc version";
CM_ SG_ 1384 GTW_a386_crcVersion "Gateway: a386 crc version";
CM_ SG_ 1384 GTW_a409_RES_CAUSE "Gateway: a409 RES CAUSE";
CM_ SG_ 1384 GTW_a410_RES_CAUSE2 "Gateway: a410 RES CAUSE2";
CM_ BO_ 62 "Gateway message: alert matrix";
CM_ SG_ 62 GTW_matrixIndex "Gateway: matrix index";
CM_ SG_ 62 GTW_w001_canEthTxQueue "Gateway: w001 can eth tx queue";
CM_ SG_ 62 GTW_w002_taskError "Gateway: w002 task error";
CM_ SG_ 62 GTW_w003_logWriteRecord "Gateway: w003 log write record";
CM_ SG_ 62 GTW_w004_mallocHook "Gateway: w004 malloc hook";
CM_ SG_ 62 GTW_w005_stackOverflowHook "Gateway: w005 stack overflow hook";
CM_ SG_ 62 GTW_w006_ifTxOutputFull "Gateway: w006 if tx output full";
CM_ SG_ 62 GTW_w007_ifRxBufError "Gateway: w007 if rx buf error";
CM_ SG_ 62 GTW_w008_ifPbufAllocError "Gateway: w008 if pbuf alloc error";
CM_ SG_ 62 GTW_w009_lateTask "Gateway: w009 late task";
CM_ SG_ 62 GTW_w010_wdTaskCount "Gateway: w010 wd task count";
CM_ SG_ 62 GTW_w011_cancoreWatchdog "Gateway: w011 cancore watchdog";
CM_ SG_ 62 GTW_w012_maincoreWatchdog "Gateway: w012 maincore watchdog";
CM_ SG_ 62 GTW_w014_APSversionMismatch "Gateway: w014 AP sversion mismatch";
CM_ SG_ 62 GTW_w015_DIFversionMismatch "Gateway: w015 DI fversion mismatch";
CM_ SG_ 62 GTW_w016_BLEEPCENTERversionMisma "Gateway: w016 BLEEPCENTE rversion mismatch";
CM_ SG_ 62 GTW_w017_BMSversionMismatch "Gateway: w017 BM sversion mismatch";
CM_ SG_ 62 GTW_w018_CMPversionMismatch "Gateway: w018 CM pversion mismatch";
CM_ SG_ 62 GTW_w019_CPversionMismatch "Gateway: w019 c pversion mismatch";
CM_ SG_ 62 GTW_w020_DIRversionMismatch "Gateway: w020 DI rversion mismatch";
CM_ SG_ 62 GTW_w021_EPAS3PversionMismatch "Gateway: w021 EPAS3 pversion mismatch";
CM_ SG_ 62 GTW_w022_EPBLversionMismatch "Gateway: w022 EPB lversion mismatch";
CM_ SG_ 62 GTW_w023_EPBRversionMismatch "Gateway: w023 EPB rversion mismatch";
CM_ SG_ 62 GTW_w024_ESPversionMismatch "Gateway: w024 ES pversion mismatch";
CM_ SG_ 62 GTW_w025_ESPCALversionMismatch "Gateway: w025 ESPCA lversion mismatch";
CM_ SG_ 62 GTW_w026_GTWversionMismatch "Gateway: w026 GT wversion mismatch";
CM_ SG_ 62 GTW_w027_HVPversionMismatch "Gateway: w027 HV pversion mismatch";
CM_ SG_ 62 GTW_w028_IBSTversionMismatch "Gateway: w028 IBS tversion mismatch";
CM_ SG_ 62 GTW_w029_IBSTCALversionMismatch "Gateway: w029 IBSTCA lversion mismatch";
CM_ SG_ 62 GTW_w030_OCS1PversionMismatch "Gateway: w030 OCS1 pversion mismatch";
CM_ SG_ 62 GTW_w031_PARKversionMismatch "Gateway: w031 PAR kversion mismatch";
CM_ SG_ 62 GTW_w032_PCSversionMismatch "Gateway: w032 PC sversion mismatch";
CM_ SG_ 62 GTW_w033_PCSCPU2versionMismatch "Gateway: w033 pcscpu2version mismatch";
CM_ SG_ 62 GTW_w034_PMRversionMismatch "Gateway: w034 PM rversion mismatch";
CM_ SG_ 62 GTW_w035_PMFversionMismatch "Gateway: w035 PM fversion mismatch";
CM_ SG_ 62 GTW_w036_PTCversionMismatch "Gateway: w036 PT cversion mismatch";
CM_ SG_ 62 GTW_w037_RADCversionMismatch "Gateway: w037 RAD cversion mismatch";
CM_ SG_ 62 GTW_w038_RCMversionMismatch "Gateway: w038 RC mversion mismatch";
CM_ SG_ 62 GTW_w039_RCMCALversionMismatch "Gateway: w039 RCMCA lversion mismatch";
CM_ SG_ 62 GTW_w040_SCCMversionMismatch "Gateway: w040 SCC mversion mismatch";
CM_ SG_ 62 GTW_w041_VCSECversionMismatch "Gateway: w041 VCSE cversion mismatch";
CM_ SG_ 62 GTW_w042_TASversionMismatch "Gateway: w042 TA sversion mismatch";
CM_ SG_ 62 GTW_w043_THSversionMismatch "Gateway: w043 TH sversion mismatch";
CM_ SG_ 62 GTW_w045_VCFRONTversionMismatch "Gateway: w045 VCFRON tversion mismatch";
CM_ SG_ 62 GTW_w046_VCLEFTversionMismatch "Gateway: w046 VCLEF tversion mismatch";
CM_ SG_ 62 GTW_w047_VCRIGHTversionMismatch "Gateway: w047 VCRIGH tversion mismatch";
CM_ SG_ 62 GTW_w048_EPAS3SversionMismatch "Gateway: w048 EPAS3 sversion mismatch";
CM_ SG_ 62 GTW_w049_corruptedManifest "Gateway: w049 corrupted manifest";
CM_ SG_ 62 GTW_w050_sdCardInitFailure "Gateway: w050 sd card init failure";
CM_ SG_ 62 GTW_w051_sdCardFileSystemFailure "Gateway: w051 sd card file system failure";
CM_ SG_ 62 GTW_w052_ifTxSpans "Gateway: w052 if tx spans";
CM_ SG_ 62 GTW_w053_busSleepFailure "Gateway: w053 bus sleep failure";
CM_ SG_ 62 GTW_w054_OPCRversionMismatch "Gateway: w054 OPC rversion mismatch";
CM_ SG_ 62 GTW_w055_OPCFversionMismatch "Gateway: w055 OPC fversion mismatch";
CM_ SG_ 62 GTW_w057_i2cFailure "Gateway: w057 i2c failure";
CM_ SG_ 62 GTW_w058_rtcAlarmFailure "Gateway: w058 rtc alarm failure";
CM_ SG_ 62 GTW_w059_inFactoryMode "Gateway: w059 in factory mode";
CM_ SG_ 62 GTW_w060_unFused "Gateway: w060 un fused";
CM_ SG_ 62 GTW_w061_bmpSleepFailure "Gateway: w061 bmp sleep failure";
CM_ SG_ 62 GTW_w062_bmpWatchdog "Gateway: w062 bmp watchdog";
CM_ SG_ 62 GTW_w063_VEH_canFault "Gateway: w063 VEH can fault";
CM_ SG_ 62 GTW_w064_CH_canFault "Gateway: w064 CH can fault";
CM_ SG_ 62 GTW_w065_PARTY_canFault "Gateway: w065 PARTY can fault";
CM_ SG_ 62 GTW_w066_exception "Gateway: w066 exception";
CM_ SG_ 62 GTW_w067_tcpDebug "Gateway: w067 tcp debug";
CM_ SG_ 62 GTW_w068_prodKeyMissing "Gateway: w068 prod key missing";
CM_ SG_ 62 GTW_w069_diskioErr "Gateway: w069 diskio err";
CM_ SG_ 62 GTW_w070_hrlDump "Gateway: w070 hrl dump";
CM_ SG_ 62 GTW_w071_hrlTrigger "Gateway: w071 hrl trigger";
CM_ SG_ 62 GTW_w072_updateFailure "Gateway: w072 update failure";
CM_ SG_ 62 GTW_w073_steeringWheelReset "Gateway: w073 steering wheel reset";
CM_ SG_ 62 GTW_w074_epas3pMIA "Gateway: w074 epas3p MIA";
CM_ SG_ 62 GTW_w075_epas3sMIA "Gateway: w075 epas3s MIA";
CM_ SG_ 62 GTW_w076_ethInterfaceReset "Gateway: w076 eth interface reset";
CM_ SG_ 62 GTW_w077_bmpPmicError "Gateway: w077 bmp pmic error";
CM_ SG_ 62 GTW_w078_VEHbusOverloaded "Gateway: w078 VE hbus overloaded";
CM_ SG_ 62 GTW_w079_PARTYbusOverloaded "Gateway: w079 PART ybus overloaded";
CM_ SG_ 62 GTW_w080_CHbusOverloaded "Gateway: w080 c hbus overloaded";
CM_ SG_ 62 GTW_w081_udsMessageRejected "Gateway: w081 uds message rejected";
CM_ SG_ 62 GTW_w082_sdCardBSCorrupted "Gateway: w082 sd card BS corrupted";
CM_ SG_ 62 GTW_w083_udsMsgDroppedByTcpStack "Gateway: w083 uds msg dropped by tcp stack";
CM_ SG_ 62 GTW_w084_canFrameDropped "Gateway: w084 can frame dropped";
CM_ SG_ 62 GTW_w086_ocu "Gateway: w086 ocu";
CM_ SG_ 62 GTW_w087_ocuInProgress "Gateway: w087 ocu in progress";
CM_ SG_ 62 GTW_w088_sdCardInvReqParallel "Gateway: w088 sd card inv req parallel";
CM_ SG_ 62 GTW_w089_sdCardWatchdog "Gateway: w089 sd card watchdog";
CM_ SG_ 62 GTW_w090_ocuFailed "Gateway: w090 ocu failed";
CM_ SG_ 62 GTW_w091_lowStack "Gateway: w091 low stack";
CM_ SG_ 62 GTW_w092_sdCardInvReqZero "Gateway: w092 sd card inv req zero";
CM_ SG_ 62 GTW_w093_sdCardInvReqOverflowBas "Gateway: w093 sd card inv req overflow base";
CM_ SG_ 62 GTW_w094_sdCardInvReqOverflowCou "Gateway: w094 sd card inv req overflow count";
CM_ SG_ 62 GTW_w095_sdCardFull "Gateway: w095 sd card full";
CM_ SG_ 62 GTW_w096_sdCardFatCorrupted "Gateway: w096 sd card fat corrupted";
CM_ SG_ 62 GTW_w097_HCMLversionMismatch "Gateway: w097 HCM lversion mismatch";
CM_ SG_ 62 GTW_w098_HCMRversionMismatch "Gateway: w098 HCM rversion mismatch";
CM_ SG_ 62 GTW_w099_SWCversionMismatch "Gateway: w099 SW cversion mismatch";
CM_ SG_ 62 GTW_w100_CBCversionMismatch "Gateway: w100 CB cversion mismatch";
CM_ SG_ 62 GTW_w101_switchWatchdog "Gateway: w101 switch watchdog";
CM_ SG_ 62 GTW_w103_sdCardFormatted "Gateway: w103 sd card formatted";
CM_ SG_ 62 GTW_w104_sdCardDriverArgCorrupte "Gateway: w104 sd card driver arg corrupted";
CM_ SG_ 62 GTW_w105_eBuckConfigured "Gateway: w105 e buck configured";
CM_ SG_ 62 GTW_w106_BLEEPLEFTversionMismatc "Gateway: w106 BLEEPLEF tversion mismatch";
CM_ SG_ 62 GTW_w107_BLEEPRIGHTversionMismat "Gateway: w107 BLEEPRIGH tversion mismatch";
CM_ SG_ 62 GTW_w108_BLEEPREARversionMismatc "Gateway: w108 BLEEPREA rversion mismatch";
CM_ SG_ 62 GTW_w109_failedToStartUpdater "Gateway: w109 failed to start updater";
CM_ SG_ 62 GTW_w110_readMdioFailed "Gateway: w110 read mdio failed";
CM_ SG_ 62 GTW_w111_writeMdioFailed "Gateway: w111 write mdio failed";
CM_ SG_ 62 GTW_w112_z4bDisabled "Gateway: w112 z4b disabled";
CM_ SG_ 62 GTW_w113_unrecognizedCanMessage "Gateway: w113 unrecognized can message";
CM_ SG_ 62 GTW_w114_updtRetried "Gateway: w114 updt retried";
CM_ SG_ 62 GTW_w115_hrlEventFileAvail "Gateway: w115 hrl event file avail";
CM_ SG_ 62 GTW_w116_switchInitFailed "Gateway: w116 switch init failed";
CM_ SG_ 62 GTW_w117_unexpectedDestructiveRe "Gateway: w117 unexpected destructive reset status";
CM_ SG_ 62 GTW_w118_unexpectedFunctionalRes "Gateway: w118 unexpected functional reset status";
CM_ SG_ 62 GTW_w120_switchUnlocked "Gateway: w120 switch unlocked";
CM_ SG_ 62 GTW_w122_BDY_canFault "Gateway: w122 BDY can fault";
CM_ SG_ 62 GTW_w123_BDYbusOverloaded "Gateway: w123 BD ybus overloaded";
CM_ SG_ 62 GTW_w125_switchReplayUnlocked "Gateway: w125 switch replay unlocked";
CM_ SG_ 62 GTW_w127_noFilePointersAvailable "Gateway: w127 no file pointers available";
CM_ SG_ 62 GTW_w129_ICRversionMismatch "Gateway: w129 IC rversion mismatch";
CM_ SG_ 62 GTW_w133_adspFaultDetected "Gateway: w133 adsp fault detected";
CM_ SG_ 62 GTW_w134_disableFeatureFailed "Gateway: w134 disable feature failed";
CM_ SG_ 62 GTW_w135_canLogQueueFull "Gateway: w135 can log queue full";
CM_ SG_ 62 GTW_w136_hrlGameModeFileAvail "Gateway: w136 hrl game mode file avail";
CM_ SG_ 62 GTW_w137_lowHeap "Gateway: w137 low heap";
CM_ SG_ 62 GTW_w138_sdCardEndOfLife "Gateway: w138 sd card end of life";
CM_ SG_ 62 GTW_w139_CMPDversionMismatch "Gateway: w139 CMP dversion mismatch";
CM_ SG_ 62 GTW_w140_cancoreHeartbeat "Gateway: w140 cancore heartbeat";
CM_ SG_ 62 GTW_w141_teleCANETHis "Gateway: w141 tele CANET his";
CM_ SG_ 62 GTW_w143_possibleCanWakeIssue "Gateway: w143 possible can wake issue";
CM_ SG_ 62 GTW_w144_hrlStateMachine "Gateway: w144 hrl state machine";
CM_ SG_ 62 GTW_w145_carConfigsNotWritten "Gateway: w145 car configs not written";
CM_ SG_ 62 GTW_w146_performancePackageMisma "Gateway: w146 performance package mismatch";
CM_ SG_ 62 GTW_w147_updateAbortFor12v "Gateway: w147 update abort for12v";
CM_ SG_ 62 GTW_w149_rtcTimeSetInPast "Gateway: w149 rtc time set in past";
CM_ SG_ 62 GTW_w150_HCM3LversionMismatch "Gateway: w150 HCM3 lversion mismatch";
CM_ SG_ 62 GTW_w151_HCM3RversionMismatch "Gateway: w151 HCM3 rversion mismatch";
CM_ SG_ 62 GTW_w153_externalRtcAlarmFailure "Gateway: w153 external rtc alarm failure";
CM_ SG_ 62 GTW_w155_PMversionMismatch "Gateway: w155 p mversion mismatch";
CM_ SG_ 62 GTW_w165_USMversionMismatch "Gateway: w165 US mversion mismatch";
CM_ SG_ 62 GTW_w166_nErrCanFaultVeh "Gateway: w166 n err can fault veh";
CM_ SG_ 62 GTW_w167_nErrCanFaultCh "Gateway: w167 n err can fault ch";
CM_ SG_ 62 GTW_w168_nErrCanFaultParty "Gateway: w168 n err can fault party";
CM_ SG_ 62 GTW_w169_TPMSsoftWarnFrontLeft "Gateway: w169 TPM ssoft warn front left";
CM_ SG_ 62 GTW_w170_TPMSsoftWarnFrontRight "Gateway: w170 TPM ssoft warn front right";
CM_ SG_ 62 GTW_w171_TPMSsoftWarnRearLeft "Gateway: w171 TPM ssoft warn rear left";
CM_ SG_ 62 GTW_w172_TPMSsoftWarnRearRight "Gateway: w172 TPM ssoft warn rear right";
CM_ SG_ 62 GTW_w173_TPMShardWarnFrontLeft "Gateway: w173 TPM shard warn front left";
CM_ SG_ 62 GTW_w174_TPMShardWarnFrontRight "Gateway: w174 TPM shard warn front right";
CM_ SG_ 62 GTW_w175_TPMShardWarnRearLeft "Gateway: w175 TPM shard warn rear left";
CM_ SG_ 62 GTW_w176_TPMShardWarnRearRight "Gateway: w176 TPM shard warn rear right";
CM_ SG_ 62 GTW_w186_swrPrecaution "Gateway: w186 swr precaution";
CM_ SG_ 62 GTW_w218_switchOTPIncorrect "Gateway: w218 switch OTP incorrect";
CM_ SG_ 62 GTW_w219_CMPSversionMismatch "Gateway: w219 CMP sversion mismatch";
CM_ SG_ 62 GTW_w223_LVBMSversionMismatch "Gateway: w223 LVBM sversion mismatch";
CM_ SG_ 62 GTW_w224_sdCardUpgradeNeeded "Gateway: w224 sd card upgrade needed";
CM_ SG_ 62 GTW_w225_resetOnSleepWake "Gateway: w225 reset on sleep wake";
CM_ SG_ 62 GTW_w226_DISPversionMismatch "Gateway: w226 DIS pversion mismatch";
CM_ SG_ 62 GTW_w227_DISPTOUCHversionMismatc "Gateway: w227 DISPTOUC hversion mismatch";
CM_ SG_ 62 GTW_w228_DISPOSDversionMismatch "Gateway: w228 DISPOS dversion mismatch";
CM_ SG_ 62 GTW_w229_displaySoftsetConnectio "Gateway: w229 display softset connection";
CM_ SG_ 62 GTW_w230_touchInterruptStorm "Gateway: w230 touch interrupt storm";
CM_ SG_ 62 GTW_w244_SDCRversionMismatch "Gateway: w244 SDC rversion mismatch";
CM_ SG_ 62 GTW_w245_apsNotDisabled "Gateway: w245 aps not disabled";
CM_ SG_ 62 GTW_w246_touchcoreHeartbeat "Gateway: w246 touchcore heartbeat";
CM_ SG_ 62 GTW_w255_rtc32KHzWatchdog "Gateway: w255 rtc32 k hz watchdog";
CM_ SG_ 62 GTW_w260_unknownPN "Gateway: w260 unknown PN";
CM_ SG_ 62 GTW_w261_adspWatchdog "Gateway: w261 adsp watchdog";
CM_ SG_ 62 GTW_w262_canLogBlockDropped "Gateway: w262 can log block dropped";
CM_ SG_ 62 GTW_w263_hrlUdpFileAvail "Gateway: w263 hrl udp file avail";
CM_ SG_ 62 GTW_w264_hrlPseudoFileAvail "Gateway: w264 hrl pseudo file avail";
CM_ SG_ 62 GTW_w265_optionFlagsError "Gateway: w265 option flags error";
CM_ SG_ 62 GTW_w266_dpp1MIA "Gateway: w266 dpp1 MIA";
CM_ SG_ 62 GTW_w267_dpp2MIA "Gateway: w267 dpp2 MIA";
CM_ SG_ 62 GTW_w268_stoMIA "Gateway: w268 sto MIA";
CM_ SG_ 62 GTW_w273_BLEEPREARLEFTversionMis "Gateway: w273 BLEEPREARLEF tversion mismatch";
CM_ SG_ 62 GTW_w274_BLEEPREARRIGHTversionMi "Gateway: w274 BLEEPREARRIGH tversion mismatch";
CM_ SG_ 62 GTW_w275_VDDCORE_DrMOS_Fault "Gateway: w275 VDDCORE dr MOS fault";
CM_ SG_ 62 GTW_w276_VDDSOC_DrMOS_Fault "Gateway: w276 VDDSOC dr MOS fault";
CM_ SG_ 62 GTW_w277_NonRevCDrMOSMitigationF "Gateway: w277 non rev c dr MOS mitigation failed";
CM_ SG_ 62 GTW_w278_ethSwitchCongested "Gateway: w278 eth switch congested";
CM_ SG_ 62 GTW_w279_adspRepeatedWatchdog "Gateway: w279 adsp repeated watchdog";
CM_ SG_ 62 GTW_w280_hrlFrameDropped "Gateway: w280 hrl frame dropped";
CM_ SG_ 62 GTW_w281_likelyMissedPoke "Gateway: w281 likely missed poke";
CM_ SG_ 62 GTW_w282_tcuPhyConfigurationFail "Gateway: w282 tcu phy configuration failed";
CM_ SG_ 62 GTW_w309_VCUSBversionMismatch "Gateway: w309 VCUS bversion mismatch";
CM_ SG_ 62 GTW_w311_canLogQueueFullBeforeFs "Gateway: w311 can log queue full before fs init";
CM_ SG_ 62 GTW_w312_hrlFileIncomplete "Gateway: w312 hrl file incomplete";
CM_ SG_ 62 GTW_w313_OSDActive "Gateway: w313 OSD active";
CM_ SG_ 62 GTW_w314_canLogBlockWriteErr "Gateway: w314 can log block write err";
CM_ SG_ 62 GTW_w316_sdCardChkdskRepair "Gateway: w316 sd card chkdsk repair";
CM_ SG_ 62 GTW_w317_sdCardChkdskRepairFaile "Gateway: w317 sd card chkdsk repair failed";
CM_ SG_ 62 GTW_w322_gestureUnrecognizedFrom "Gateway: w322 gesture unrecognized from moving";
CM_ SG_ 62 GTW_w323_gestureStartOutOfStrip "Gateway: w323 gesture start out of strip";
CM_ SG_ 62 GTW_w328_smartShiftDisabled "Gateway: w328 smart shift disabled";
CM_ SG_ 62 GTW_w329_FOHMversionMismatch "Gateway: w329 FOH mversion mismatch";
CM_ SG_ 62 GTW_w330_SWSLversionMismatch "Gateway: w330 SWS lversion mismatch";
CM_ SG_ 62 GTW_w331_SWSRversionMismatch "Gateway: w331 SWS rversion mismatch";
CM_ SG_ 62 GTW_w332_unknownDisplayPN "Gateway: w332 unknown display PN";
CM_ SG_ 62 GTW_w334_hrlFolderSpaceLow "Gateway: w334 hrl folder space low";
CM_ SG_ 62 GTW_w336_possibleCanTxIssue "Gateway: w336 possible can tx issue";
CM_ SG_ 62 GTW_w342_VCBLDCPPversionMismatch "Gateway: w342 VCBLDCP pversion mismatch";
CM_ SG_ 62 GTW_w348_VCBLDCFversionMismatch "Gateway: w348 VCBLDC fversion mismatch";
CM_ SG_ 62 GTW_w349_VCBLDCPBversionMismatch "Gateway: w349 VCBLDCP bversion mismatch";
CM_ SG_ 62 GTW_w350_mOSDCrcCheck "Gateway: w350 m OSD crc check";
CM_ SG_ 62 GTW_w351_sOSDCrcCheck "Gateway: w351 s OSD crc check";
CM_ SG_ 62 GTW_w352_mASILStatusCheck "Gateway: w352 m ASIL status check";
CM_ SG_ 62 GTW_w353_sASILStatusCheck "Gateway: w353 s ASIL status check";
CM_ SG_ 62 GTW_w354_EPASTPversionMismatch "Gateway: w354 EPAST pversion mismatch";
CM_ SG_ 62 GTW_w355_EPASTSversionMismatch "Gateway: w355 EPAST sversion mismatch";
CM_ SG_ 62 GTW_w356_touchGPIOStatusCheck "Gateway: w356 touch GPIO status check";
CM_ SG_ 62 GTW_w358_RGBIPFLversionMismatch "Gateway: w358 RGBIPF lversion mismatch";
CM_ SG_ 62 GTW_w359_RGBIPFRversionMismatch "Gateway: w359 RGBIPF rversion mismatch";
CM_ SG_ 62 GTW_w360_RGBDOORFLversionMismatc "Gateway: w360 RGBDOORF lversion mismatch";
CM_ SG_ 62 GTW_w361_RGBDOORRLversionMismatc "Gateway: w361 RGBDOORR lversion mismatch";
CM_ SG_ 62 GTW_w362_RGBDOORFRversionMismatc "Gateway: w362 RGBDOORF rversion mismatch";
CM_ SG_ 62 GTW_w363_RGBDOORRRversionMismatc "Gateway: w363 RGBDOORR rversion mismatch";
CM_ SG_ 62 GTW_w364_BLEEPCRADLEversionMisma "Gateway: w364 BLEEPCRADL eversion mismatch";
CM_ SG_ 62 GTW_w366_uiGearRequestMismatch "Gateway: w366 ui gear request mismatch";
CM_ SG_ 62 GTW_w376_blFailedToExecBootImg "Gateway: w376 bl failed to exec boot img";
CM_ SG_ 62 GTW_w380_DPBversionMismatch "Gateway: w380 DP bversion mismatch";
CM_ SG_ 62 GTW_w381_DPBCALversionMismatch "Gateway: w381 DPBCA lversion mismatch";
CM_ SG_ 62 GTW_w382_IDBversionMismatch "Gateway: w382 ID bversion mismatch";
CM_ SG_ 62 GTW_w383_IDB1versionMismatch "Gateway: w383 idb1version mismatch";
CM_ SG_ 62 GTW_w384_IDBCALversionMismatch "Gateway: w384 IDBCA lversion mismatch";
CM_ SG_ 62 GTW_w385_RCUversionMismatch "Gateway: w385 RC uversion mismatch";
CM_ SG_ 62 GTW_w386_RCUCALversionMismatch "Gateway: w386 RCUCA lversion mismatch";
CM_ SG_ 62 GTW_w387_externalRtcReadFailure "Gateway: w387 external rtc read failure";
CM_ SG_ 62 GTW_w388_adspWatchdogSkipped "Gateway: w388 adsp watchdog skipped";
CM_ SG_ 62 GTW_w389_rcmEventDetected "Gateway: w389 rcm event detected";
CM_ SG_ 62 GTW_w391_adspMacAddrCheckFailed "Gateway: w391 adsp mac addr check failed";
CM_ SG_ 62 GTW_w393_osdSramCrcMismatch "Gateway: w393 osd sram crc mismatch";
CM_ SG_ 62 GTW_w395_lwipIcmpError "Gateway: w395 lwip icmp error";
CM_ SG_ 62 GTW_w396_alreadyInReverse "Gateway: w396 already in reverse";
CM_ SG_ 62 GTW_w397_alreadyInDrive "Gateway: w397 already in drive";
CM_ SG_ 62 GTW_w398_awakeForExtendedTime "Gateway: w398 awake for extended time";
CM_ SG_ 62 GTW_w399_ethIfRxTcpipQueueDrop "Gateway: w399 eth if rx tcpip queue drop";
CM_ SG_ 62 GTW_w400_ethlSwitchOTPIncorrect "Gateway: w400 ethl switch OTP incorrect";
CM_ SG_ 62 GTW_w409_unexpectedResetCause "Gateway: w409 unexpected reset cause";
CM_ SG_ 62 GTW_w410_unexpectedResetCause2 "Gateway: w410 unexpected reset cause2";
CM_ SG_ 62 GTW_w414_socHeldInReset "Gateway: w414 soc held in reset";
CM_ BO_ 838 "Gateway message: autopilot override";
CM_ SG_ 838 GTW_autopilotOverrideState "Signals whether an autopilot trial or subscription is active";
CM_ SG_ 838 GTW_autopilotConfig "Current level of permanent Autopilot firmware";
CM_ SG_ 838 GTW_autopilotOverrideConfig "Current level of trial or subscription Autopilot firmware";
CM_ SG_ 838 GTW_autopilotOverrideExpireTime "Expiration time for the currently active autopilot trial or subscription";
CM_ BO_ 904 "Gateway message: can status";
CM_ SG_ 904 GTW_VEH_canBusActivity "Active if any frame detected on the bus";
CM_ SG_ 904 GTW_PARTY_canBusActivity "Active if any frame detected on the bus";
CM_ SG_ 904 GTW_CH_canBusActivity "Active if any frame detected on the bus";
CM_ SG_ 904 GTW_VEH_txWarning "Gateway: VEH tx warning";
CM_ SG_ 904 GTW_PARTY_txWarning "Gateway: PARTY tx warning";
CM_ SG_ 904 GTW_CH_txWarning "Gateway: CH tx warning";
CM_ SG_ 904 GTW_VEH_rxWarning "Gateway: VEH rx warning";
CM_ SG_ 904 GTW_PARTY_rxWarning "Gateway: PARTY rx warning";
CM_ SG_ 904 GTW_CH_rxWarning "Gateway: CH rx warning";
CM_ SG_ 904 GTW_VEH_faultConfinement "Fault confinement as per CAN spec";
CM_ SG_ 904 GTW_PARTY_faultConfinement "Fault confinement as per CAN spec";
CM_ SG_ 904 GTW_CH_faultConfinement "Fault confinement as per CAN spec";
CM_ SG_ 904 GTW_BDY_canBusActivity "Active if any frame detected on the bus";
CM_ SG_ 904 GTW_BDY_txWarning "Gateway: BDY tx warning";
CM_ SG_ 904 GTW_BDY_rxWarning "Gateway: BDY rx warning";
CM_ SG_ 904 GTW_BDY_faultConfinement "Fault confinement as per CAN spec";
BA_DEF_ BO_ "GenMsgCycleTime" INT 0 3600000;
BA_DEF_ BO_ "GenMsgSendType" ENUM "Cyclic","NotUsed","NotUsed","NotUsed","NotUsed","NotUsed","NotUsed","IfActive","NoMsgSendType","NotUsed";
BA_DEF_ BO_ "VFrameFormat" ENUM "StandardCAN","ExtendedCAN","reserved","J1939PG","reserved","reserved","reserved","reserved","reserved","reserved","reserved","reserved","reserved","reserved","StandardCAN_FD","ExtendedCAN_FD";
BA_DEF_ BO_ "CANFD_BRS" ENUM "0","1";
BA_DEF_ SG_ "GenSigSNA" STRING;
BA_DEF_ SG_ "SystemSignalLongSymbol" STRING;
BA_DEF_ SG_ "Confidence" ENUM "validated","plausible","layout-only","contradicted";
BA_DEF_DEF_ "GenMsgCycleTime" 0;
BA_DEF_DEF_ "GenMsgSendType" "NoMsgSendType";
BA_DEF_DEF_ "VFrameFormat" "StandardCAN";
BA_DEF_DEF_ "CANFD_BRS" "1";
BA_DEF_DEF_ "GenSigSNA" "";
BA_DEF_DEF_ "SystemSignalLongSymbol" "";
BA_DEF_DEF_ "Confidence" "layout-only";
BA_ "GenMsgCycleTime" BO_ 920 1000;
BA_ "GenMsgSendType" BO_ 920 0;
BA_ "GenMsgCycleTime" BO_ 888 1000;
BA_ "GenMsgSendType" BO_ 888 0;
BA_ "GenMsgCycleTime" BO_ 282 1000;
BA_ "GenMsgSendType" BO_ 282 0;
BA_ "GenMsgCycleTime" BO_ 62 100;
BA_ "GenMsgSendType" BO_ 62 0;
BA_ "GenMsgCycleTime" BO_ 838 1000;
BA_ "GenMsgSendType" BO_ 838 0;
BA_ "GenMsgCycleTime" BO_ 904 1000;
BA_ "GenMsgSendType" BO_ 904 0;
BA_ "Confidence" SG_ 1428 EPASTS_alertID 1;
BA_ "Confidence" SG_ 1428 EPASTS_alertState 1;
BA_ "Confidence" SG_ 1428 EPASTS_a264_degradedECU 1;
BA_ "Confidence" SG_ 1428 EPASTS_a264_vehicleSpeed 1;
BA_ "Confidence" SG_ 1428 EPASTS_a264_powerRatio 1;
BA_ "Confidence" SG_ 1428 EPASTS_a264_ownSideDegradationRe 1;
BA_ "SystemSignalLongSymbol" SG_ 1428 EPASTS_a264_ownSideDegradationRe "EPASTS_a264_ownSideDegradationReason";
BA_ "Confidence" SG_ 1428 EPASTS_a264_otherSideDegradation 1;
BA_ "SystemSignalLongSymbol" SG_ 1428 EPASTS_a264_otherSideDegradation "EPASTS_a264_otherSideDegradationReason";
BA_ "Confidence" SG_ 1428 EPASTS_a265_degradedECU 1;
BA_ "Confidence" SG_ 1428 EPASTS_a265_vehicleSpeed 1;
BA_ "Confidence" SG_ 1428 EPASTS_a265_rawMcuTemperature 1;
BA_ "Confidence" SG_ 1428 EPASTS_a265_degradedCurrentLimit 1;
BA_ "Confidence" SG_ 1428 EPASTS_a266_cdpAssistFactor 1;
BA_ "Confidence" SG_ 1428 EPASTS_a266_vehicleSpeed 1;
BA_ "Confidence" SG_ 1428 EPASTS_a267_vehicleSpeed 1;
BA_ "Confidence" SG_ 1428 EPASTS_a267_velocityEstimatorSta 1;
BA_ "SystemSignalLongSymbol" SG_ 1428 EPASTS_a267_velocityEstimatorSta "EPASTS_a267_velocityEstimatorState";
BA_ "Confidence" SG_ 1428 EPASTS_a269_vehicleSpeed 1;
BA_ "Confidence" SG_ 920 EPASTS_matrixIndex 1;
BA_ "SystemSignalLongSymbol" SG_ 920 EPASTS_a001_adcCalibrationOrInit "EPASTS_a001_adcCalibrationOrInitFail";
BA_ "SystemSignalLongSymbol" SG_ 920 EPASTS_a005_scpUnknownResetSourc "EPASTS_a005_scpUnknownResetSource";
BA_ "SystemSignalLongSymbol" SG_ 920 EPASTS_a006_swrhResetByInvalidEr "EPASTS_a006_swrhResetByInvalidErrid";
BA_ "SystemSignalLongSymbol" SG_ 920 EPASTS_a009_mcusscLbistPermanent "EPASTS_a009_mcusscLbistPermanentFail";
BA_ "SystemSignalLongSymbol" SG_ 920 EPASTS_a010_svcIncompatibleSwVer "EPASTS_a010_svcIncompatibleSwVersions";
BA_ "SystemSignalLongSymbol" SG_ 920 EPASTS_a013_mcusscSffMonitoringF "EPASTS_a013_mcusscSffMonitoringFailed";
BA_ "SystemSignalLongSymbol" SG_ 920 EPASTS_a014_mcusscSffMonitoringM "EPASTS_a014_mcusscSffMonitoringMia";
BA_ "SystemSignalLongSymbol" SG_ 920 EPASTS_a015_mcusscCsErrorCheckFa "EPASTS_a015_mcusscCsErrorCheckFail";
BA_ "SystemSignalLongSymbol" SG_ 920 EPASTS_a016_mcufcCsErrorCheckFai "EPASTS_a016_mcufcCsErrorCheckFail";
BA_ "SystemSignalLongSymbol" SG_ 920 EPASTS_a017_stmdStmPlausibilityC "EPASTS_a017_stmdStmPlausibilityCheckErr";
BA_ "SystemSignalLongSymbol" SG_ 920 EPASTS_a019_rsthHwResetInfoCorru "EPASTS_a019_rsthHwResetInfoCorruptionCheck";
BA_ "SystemSignalLongSymbol" SG_ 920 EPASTS_a020_mcusscEolEcuIdIntegr "EPASTS_a020_mcusscEolEcuIdIntegritiyFail";
BA_ "SystemSignalLongSymbol" SG_ 920 EPASTS_a022_swrhSwResetInfoCorru "EPASTS_a022_swrhSwResetInfoCorruptionCheck";
BA_ "SystemSignalLongSymbol" SG_ 920 EPASTS_a028_smuhNonInitDataCorru "EPASTS_a028_smuhNonInitDataCorruption";
BA_ "SystemSignalLongSymbol" SG_ 920 EPASTS_a029_smuhSmuCoreCntErrorT "EPASTS_a029_smuhSmuCoreCntErrorTestFail";
BA_ "SystemSignalLongSymbol" SG_ 920 EPASTS_a031_pmsProductionModeFai "EPASTS_a031_pmsProductionModeFailed";
BA_ "SystemSignalLongSymbol" SG_ 920 EPASTS_a033_icsvcPswVersionMisma "EPASTS_a033_icsvcPswVersionMismatch";
BA_ "SystemSignalLongSymbol" SG_ 920 EPASTS_a038_csohCh1CsErrorErrAtR "EPASTS_a038_csohCh1CsErrorErrAtReset";
BA_ "SystemSignalLongSymbol" SG_ 920 EPASTS_a039_csohCh2CsErrorErrAtR "EPASTS_a039_csohCh2CsErrorErrAtReset";
BA_ "SystemSignalLongSymbol" SG_ 920 EPASTS_a040_swrhLimitedResetRetr "EPASTS_a040_swrhLimitedResetRetriesExpired";
BA_ "SystemSignalLongSymbol" SG_ 920 EPASTS_a041_imcmCoreConfiguratio "EPASTS_a041_imcmCoreConfigurationMismatch";
BA_ "SystemSignalLongSymbol" SG_ 920 EPASTS_a045_psumSbcBandgapVoltEr "EPASTS_a045_psumSbcBandgapVoltErr";
BA_ "SystemSignalLongSymbol" SG_ 920 EPASTS_a046_mcusscOscillatorNotR "EPASTS_a046_mcusscOscillatorNotReliable";
BA_ "SystemSignalLongSymbol" SG_ 920 EPASTS_a052_ermSdcInputBufferOve "EPASTS_a052_ermSdcInputBufferOverflow";
BA_ "SystemSignalLongSymbol" SG_ 920 EPASTS_a053_adcUnexpectedNumOfDa "EPASTS_a053_adcUnexpectedNumOfData";
BA_ "SystemSignalLongSymbol" SG_ 920 EPASTS_a056_amGduConfigCsErrorCh "EPASTS_a056_amGduConfigCsErrorCheck";
BA_ "SystemSignalLongSymbol" SG_ 920 EPASTS_a067_tspmPowermoduleTempI "EPASTS_a067_tspmPowermoduleTempImplausible";
BA_ "SystemSignalLongSymbol" SG_ 920 EPASTS_a068_rsthCoreRedundancyEr "EPASTS_a068_rsthCoreRedundancyErr";
BA_ "SystemSignalLongSymbol" SG_ 920 EPASTS_a069_rsthCoreTempOutOfRan "EPASTS_a069_rsthCoreTempOutOfRangeHwCheck";
BA_ "SystemSignalLongSymbol" SG_ 920 EPASTS_a072_rsthFlashUncorrEccOr "EPASTS_a072_rsthFlashUncorrEccOrOvfl";
BA_ "SystemSignalLongSymbol" SG_ 920 EPASTS_a075_rsthUnusedOtherModul "EPASTS_a075_rsthUnusedOtherModuleAlarm";
BA_ "SystemSignalLongSymbol" SG_ 920 EPASTS_a081_exchFloatingPointExc "EPASTS_a081_exchFloatingPointException";
BA_ "SystemSignalLongSymbol" SG_ 920 EPASTS_a083_tdaDclinkcapacitorTe "EPASTS_a083_tdaDclinkcapacitorTempChecker";
BA_ "SystemSignalLongSymbol" SG_ 920 EPASTS_a085_amGduSwitchOffTestBy "EPASTS_a085_amGduSwitchOffTestByMcu";
BA_ "SystemSignalLongSymbol" SG_ 920 EPASTS_a088_tedMainboardTempChec "EPASTS_a088_tedMainboardTempChecker";
BA_ "SystemSignalLongSymbol" SG_ 920 EPASTS_a089_tedRevercebattfetjun "EPASTS_a089_tedRevercebattfetjunctionTempChecker";
BA_ "SystemSignalLongSymbol" SG_ 920 EPASTS_a091_bvpBattVoltCrossChkF "EPASTS_a091_bvpBattVoltCrossChkFailed";
BA_ "SystemSignalLongSymbol" SG_ 920 EPASTS_a092_amGduSwitchOffTestBy "EPASTS_a092_amGduSwitchOffTestBySbc";
BA_ "SystemSignalLongSymbol" SG_ 920 EPASTS_a093_sctpTsuSingleStaticF "EPASTS_a093_sctpTsuSingleStaticFail";
BA_ "SystemSignalLongSymbol" SG_ 920 EPASTS_a094_sctpTsuMultipleStati "EPASTS_a094_sctpTsuMultipleStaticFail";
BA_ "SystemSignalLongSymbol" SG_ 920 EPASTS_a095_mdModelBasedMotorInt "EPASTS_a095_mdModelBasedMotorIntegrityCheck";
BA_ "SystemSignalLongSymbol" SG_ 920 EPASTS_a096_rppRpsSingleStaticFa "EPASTS_a096_rppRpsSingleStaticFail";
BA_ "SystemSignalLongSymbol" SG_ 920 EPASTS_a097_rppRpsMultipleStatic "EPASTS_a097_rppRpsMultipleStaticFail";
BA_ "SystemSignalLongSymbol" SG_ 920 EPASTS_a099_mcdTorqueMismatchFau "EPASTS_a099_mcdTorqueMismatchFault";
BA_ "SystemSignalLongSymbol" SG_ 920 EPASTS_a103_exhaUnusedInterruptC "EPASTS_a103_exhaUnusedInterruptCallException";
BA_ "SystemSignalLongSymbol" SG_ 920 EPASTS_a105_exhaSriBusErrExcepti "EPASTS_a105_exhaSriBusErrException";
BA_ "SystemSignalLongSymbol" SG_ 920 EPASTS_a106_exhaSpbBusErrExcepti "EPASTS_a106_exhaSpbBusErrException";
BA_ "SystemSignalLongSymbol" SG_ 920 EPASTS_a107_exhaOtherNmiExceptio "EPASTS_a107_exhaOtherNmiException";
BA_ "SystemSignalLongSymbol" SG_ 920 EPASTS_a108_exhaInternalProtecti "EPASTS_a108_exhaInternalProtectionException";
BA_ "SystemSignalLongSymbol" SG_ 920 EPASTS_a109_exhaSysBusOrPeriphEr "EPASTS_a109_exhaSysBusOrPeriphErrException";
BA_ "SystemSignalLongSymbol" SG_ 920 EPASTS_a110_amPhaseRelaySwitchOf "EPASTS_a110_amPhaseRelaySwitchOffTest";
BA_ "SystemSignalLongSymbol" SG_ 920 EPASTS_a111_amCurrentSensingDisc "EPASTS_a111_amCurrentSensingDisconnection";
BA_ "SystemSignalLongSymbol" SG_ 920 EPASTS_a112_rsthSafetyFlipflopEr "EPASTS_a112_rsthSafetyFlipflopErr";
BA_ "SystemSignalLongSymbol" SG_ 920 EPASTS_a113_rsthUncorrectableEnd "EPASTS_a113_rsthUncorrectableEndToEndBusErr";
BA_ "SystemSignalLongSymbol" SG_ 920 EPASTS_a115_mcusscLbistSingleFai "EPASTS_a115_mcusscLbistSingleFail";
BA_ "SystemSignalLongSymbol" SG_ 920 EPASTS_a116_mrccStartupRegCsErro "EPASTS_a116_mrccStartupRegCsErrorStaticErr";
BA_ "SystemSignalLongSymbol" SG_ 920 EPASTS_a117_mrccStartupRegCsErro "EPASTS_a117_mrccStartupRegCsErrorTransientErr";
BA_ "SystemSignalLongSymbol" SG_ 920 EPASTS_a118_mcusscFlashCsErrorEr "EPASTS_a118_mcusscFlashCsErrorErr";
BA_ "SystemSignalLongSymbol" SG_ 920 EPASTS_a119_mcusscFlashEccCritic "EPASTS_a119_mcusscFlashEccCriticalErr";
BA_ "SystemSignalLongSymbol" SG_ 920 EPASTS_a120_mcusscFlashEccLatent "EPASTS_a120_mcusscFlashEccLatentErr";
BA_ "SystemSignalLongSymbol" SG_ 920 EPASTS_a124_mcusscMbistEccTransi "EPASTS_a124_mcusscMbistEccTransientErr";
BA_ "SystemSignalLongSymbol" SG_ 920 EPASTS_a127_exchAdditionalExcept "EPASTS_a127_exchAdditionalExceptionAfterRst";
BA_ "SystemSignalLongSymbol" SG_ 920 EPASTS_a128_exchExceptionStopRes "EPASTS_a128_exchExceptionStopRestart";
BA_ "SystemSignalLongSymbol" SG_ 920 EPASTS_a129_exchAdditionalExcept "EPASTS_a129_exchAdditionalExceptionStopRestart";
BA_ "SystemSignalLongSymbol" SG_ 920 EPASTS_a131_exchGuardedResetAfte "EPASTS_a131_exchGuardedResetAfterPartitionStop";
BA_ "SystemSignalLongSymbol" SG_ 920 EPASTS_a132_mcusscNotSupportedMc "EPASTS_a132_mcusscNotSupportedMcu";
BA_ "SystemSignalLongSymbol" SG_ 920 EPASTS_a133_mcusscLbistEcuIdIsNo "EPASTS_a133_mcusscLbistEcuIdIsNotSupported";
BA_ "SystemSignalLongSymbol" SG_ 920 EPASTS_a134_osehGuardedResetAfte "EPASTS_a134_osehGuardedResetAfterErrWithoutReset";
BA_ "SystemSignalLongSymbol" SG_ 920 EPASTS_a135_tmpsfetjCalculationO "EPASTS_a135_tmpsfetjCalculationOverflowErr";
BA_ "SystemSignalLongSymbol" SG_ 920 EPASTS_a137_osehErrWithoutImmedi "EPASTS_a137_osehErrWithoutImmediateReset";
BA_ "SystemSignalLongSymbol" SG_ 920 EPASTS_a138_osehAdditionalErrWit "EPASTS_a138_osehAdditionalErrWithoutImmReset";
BA_ "SystemSignalLongSymbol" SG_ 920 EPASTS_a142_tedEmifilterDmcTempC "EPASTS_a142_tedEmifilterDmcTempChecker";
BA_ "SystemSignalLongSymbol" SG_ 920 EPASTS_a143_tedEmifilterCmcTempC "EPASTS_a143_tedEmifilterCmcTempChecker";
BA_ "SystemSignalLongSymbol" SG_ 920 EPASTS_a145_mriPeripheralRaminit "EPASTS_a145_mriPeripheralRaminitFailed";
BA_ "SystemSignalLongSymbol" SG_ 920 EPASTS_a148_mrccExitFromStandbyD "EPASTS_a148_mrccExitFromStandbyDetected";
BA_ "SystemSignalLongSymbol" SG_ 920 EPASTS_a149_amReversibleEmergenc "EPASTS_a149_amReversibleEmergencyOffRequested";
BA_ "SystemSignalLongSymbol" SG_ 920 EPASTS_a150_amExternalEmergencyO "EPASTS_a150_amExternalEmergencyOffRequested";
BA_ "SystemSignalLongSymbol" SG_ 920 EPASTS_a151_amPermanentEmergency "EPASTS_a151_amPermanentEmergencyOffRequested";
BA_ "SystemSignalLongSymbol" SG_ 920 EPASTS_a152_exchFlashEccExceptio "EPASTS_a152_exchFlashEccException";
BA_ "SystemSignalLongSymbol" SG_ 920 EPASTS_a153_sdsmBlockSelectorInv "EPASTS_a153_sdsmBlockSelectorInvalid";
BA_ "SystemSignalLongSymbol" SG_ 920 EPASTS_a154_sdsmCsErrorInvalidPr "EPASTS_a154_sdsmCsErrorInvalidPrimary";
BA_ "SystemSignalLongSymbol" SG_ 920 EPASTS_a156_amIntSerialErrSafety "EPASTS_a156_amIntSerialErrSafetyReset";
BA_ "SystemSignalLongSymbol" SG_ 920 EPASTS_a158_amGduFailDuringRecov "EPASTS_a158_amGduFailDuringRecovery";
BA_ "SystemSignalLongSymbol" SG_ 920 EPASTS_a159_exchFlashWordlineTra "EPASTS_a159_exchFlashWordlineTransientErr";
BA_ "SystemSignalLongSymbol" SG_ 920 EPASTS_a160_rsthCpu1UnexpectedAl "EPASTS_a160_rsthCpu1UnexpectedAlarm";
BA_ "SystemSignalLongSymbol" SG_ 920 EPASTS_a161_tdaRelayfetjunctionT "EPASTS_a161_tdaRelayfetjunctionTempChecker";
BA_ "SystemSignalLongSymbol" SG_ 920 EPASTS_a162_tdaBridgefetjunction "EPASTS_a162_tdaBridgefetjunctionTempChecker";
BA_ "SystemSignalLongSymbol" SG_ 920 EPASTS_a163_tdaPowermoduleTempCh "EPASTS_a163_tdaPowermoduleTempChecker";
BA_ "SystemSignalLongSymbol" SG_ 920 EPASTS_a164_tdaBattfetjunctionTe "EPASTS_a164_tdaBattfetjunctionTempChecker";
BA_ "SystemSignalLongSymbol" SG_ 920 EPASTS_a165_tdaDcbusshuntTempChe "EPASTS_a165_tdaDcbusshuntTempChecker";
BA_ "SystemSignalLongSymbol" SG_ 920 EPASTS_a166_tdaPhasecurrentshunt "EPASTS_a166_tdaPhasecurrentshuntTempChecker";
BA_ "SystemSignalLongSymbol" SG_ 920 EPASTS_a167_iccd1ErrQueueOverflo "EPASTS_a167_iccd1ErrQueueOverflow";
BA_ "SystemSignalLongSymbol" SG_ 920 EPASTS_a172_pmpElangMotorcurrent "EPASTS_a172_pmpElangMotorcurrentAge";
BA_ "SystemSignalLongSymbol" SG_ 920 EPASTS_a175_exchFlashStoredConfi "EPASTS_a175_exchFlashStoredConfigErr";
BA_ "SystemSignalLongSymbol" SG_ 920 EPASTS_a176_exchCpu1ExceptionRes "EPASTS_a176_exchCpu1ExceptionReset";
BA_ "SystemSignalLongSymbol" SG_ 920 EPASTS_a179_tedMotorcoilTempChec "EPASTS_a179_tedMotorcoilTempChecker";
BA_ "SystemSignalLongSymbol" SG_ 920 EPASTS_a180_dmDeadlineViolationC "EPASTS_a180_dmDeadlineViolationC1";
BA_ "SystemSignalLongSymbol" SG_ 920 EPASTS_a181_dmDeadlineViolationC "EPASTS_a181_dmDeadlineViolationC1";
BA_ "SystemSignalLongSymbol" SG_ 920 EPASTS_a184_sbcmCommBufferOverfl "EPASTS_a184_sbcmCommBufferOverflow";
BA_ "SystemSignalLongSymbol" SG_ 920 EPASTS_a185_sbcscpQAWatchdogRese "EPASTS_a185_sbcscpQAWatchdogReset";
BA_ "SystemSignalLongSymbol" SG_ 920 EPASTS_a186_wdhCommBufferOverflo "EPASTS_a186_wdhCommBufferOverflow";
BA_ "SystemSignalLongSymbol" SG_ 920 EPASTS_a188_epmCommBufferOverflo "EPASTS_a188_epmCommBufferOverflow";
BA_ "SystemSignalLongSymbol" SG_ 920 EPASTS_a190_sbchCommBufferOverfl "EPASTS_a190_sbchCommBufferOverflow";
BA_ "SystemSignalLongSymbol" SG_ 920 EPASTS_a191_sbcscpVcp2VucVoltFai "EPASTS_a191_sbcscpVcp2VucVoltFail";
BA_ "SystemSignalLongSymbol" SG_ 920 EPASTS_a196_topEolTasOffsetInval "EPASTS_a196_topEolTasOffsetInvalid";
BA_ "SystemSignalLongSymbol" SG_ 920 EPASTS_a200_ammInputBufferOverfl "EPASTS_a200_ammInputBufferOverflow";
BA_ "SystemSignalLongSymbol" SG_ 920 EPASTS_a201_ammOutputBufferOverf "EPASTS_a201_ammOutputBufferOverflow";
BA_ "SystemSignalLongSymbol" SG_ 920 EPASTS_a202_ohnvmpStoredOffsetLo "EPASTS_a202_ohnvmpStoredOffsetLost";
BA_ "SystemSignalLongSymbol" SG_ 920 EPASTS_a206_fdrOclPartialBlockin "EPASTS_a206_fdrOclPartialBlocking";
BA_ "SystemSignalLongSymbol" SG_ 920 EPASTS_a208_fdrLowSeverityBlocki "EPASTS_a208_fdrLowSeverityBlocking";
BA_ "SystemSignalLongSymbol" SG_ 920 EPASTS_a209_fdrLowSeverityFreezi "EPASTS_a209_fdrLowSeverityFreezing";
BA_ "SystemSignalLongSymbol" SG_ 920 EPASTS_a213_frmHighFrictionDetec "EPASTS_a213_frmHighFrictionDetected";
BA_ "SystemSignalLongSymbol" SG_ 920 EPASTS_a218_aadApplicationStateE "EPASTS_a218_aadApplicationStateErr";
BA_ "SystemSignalLongSymbol" SG_ 920 EPASTS_a220_transceiverInputqueu "EPASTS_a220_transceiverInputqueueOverflow";
BA_ "SystemSignalLongSymbol" SG_ 920 EPASTS_a258_pspInvalidProjectPar "EPASTS_a258_pspInvalidProjectParamset";
BA_ "SystemSignalLongSymbol" SG_ 920 EPASTS_a270_oscillationCompTrqLi "EPASTS_a270_oscillationCompTrqLimReached";
BA_ "Confidence" SG_ 888 GTW_GTW_SOS_ECALL_RQST 0;
BA_ "Confidence" SG_ 888 GTW_LTE_ECALL_LOCK 0;
BA_ "Confidence" SG_ 282 GTW_BKP_BATT_MON 1;
BA_ "GenSigSNA" SG_ 282 GTW_BKP_BATT_MON "4095";
BA_ "Confidence" SG_ 282 GTW_BKP_BATT_NTC_P 1;
BA_ "GenSigSNA" SG_ 282 GTW_BKP_BATT_NTC_P "4095";
BA_ "Confidence" SG_ 282 GTW_ECALL_GPS_ANT_BIAS 1;
BA_ "GenSigSNA" SG_ 282 GTW_ECALL_GPS_ANT_BIAS "4095";
BA_ "Confidence" SG_ 282 GTW_ECALL_MIC_DIAG 1;
BA_ "GenSigSNA" SG_ 282 GTW_ECALL_MIC_DIAG "4095";
BA_ "Confidence" SG_ 282 GTW_SOS_ECALL_nRQST_BUF 1;
BA_ "GenSigSNA" SG_ 282 GTW_SOS_ECALL_nRQST_BUF "4095";
BA_ "Confidence" SG_ 1384 GTW_alertID 1;
BA_ "Confidence" SG_ 1384 GTW_alertState 1;
BA_ "Confidence" SG_ 1384 GTW_a049_headerError 1;
BA_ "Confidence" SG_ 1384 GTW_a062_bmpWatchdogReason 1;
BA_ "Confidence" SG_ 1384 GTW_a063_VEH_faultConfinement 1;
BA_ "Confidence" SG_ 1384 GTW_a064_CH_faultConfinement 1;
BA_ "Confidence" SG_ 1384 GTW_a065_PARTY_faultConfinement 1;
BA_ "Confidence" SG_ 1384 GTW_a077_bmpPmicErrorType 1;
BA_ "Confidence" SG_ 1384 GTW_a078_loadPercent 1;
BA_ "Confidence" SG_ 1384 GTW_a079_loadPercent 1;
BA_ "Confidence" SG_ 1384 GTW_a080_loadPercent 1;
BA_ "Confidence" SG_ 1384 GTW_a081_ISOTPmsgType 1;
BA_ "Confidence" SG_ 1384 GTW_a081_udsSID 1;
BA_ "Confidence" SG_ 1384 GTW_a122_BDY_faultConfinement 1;
BA_ "Confidence" SG_ 1384 GTW_a261_failureReason 1;
BA_ "Confidence" SG_ 1384 GTW_a277_mitigationFailureReason 1;
BA_ "Confidence" SG_ 1384 GTW_a279_failureReason 1;
BA_ "Confidence" SG_ 1384 GTW_a317_status 1;
BA_ "Confidence" SG_ 1384 GTW_a317_errorCode 1;
BA_ "Confidence" SG_ 62 GTW_matrixIndex 1;
BA_ "SystemSignalLongSymbol" SG_ 62 GTW_w016_BLEEPCENTERversionMisma "GTW_w016_BLEEPCENTERversionMismatch";
BA_ "SystemSignalLongSymbol" SG_ 62 GTW_w093_sdCardInvReqOverflowBas "GTW_w093_sdCardInvReqOverflowBase";
BA_ "SystemSignalLongSymbol" SG_ 62 GTW_w094_sdCardInvReqOverflowCou "GTW_w094_sdCardInvReqOverflowCount";
BA_ "SystemSignalLongSymbol" SG_ 62 GTW_w104_sdCardDriverArgCorrupte "GTW_w104_sdCardDriverArgCorrupted";
BA_ "SystemSignalLongSymbol" SG_ 62 GTW_w106_BLEEPLEFTversionMismatc "GTW_w106_BLEEPLEFTversionMismatch";
BA_ "SystemSignalLongSymbol" SG_ 62 GTW_w107_BLEEPRIGHTversionMismat "GTW_w107_BLEEPRIGHTversionMismatch";
BA_ "SystemSignalLongSymbol" SG_ 62 GTW_w108_BLEEPREARversionMismatc "GTW_w108_BLEEPREARversionMismatch";
BA_ "SystemSignalLongSymbol" SG_ 62 GTW_w117_unexpectedDestructiveRe "GTW_w117_unexpectedDestructiveResetStatus";
BA_ "SystemSignalLongSymbol" SG_ 62 GTW_w118_unexpectedFunctionalRes "GTW_w118_unexpectedFunctionalResetStatus";
BA_ "SystemSignalLongSymbol" SG_ 62 GTW_w146_performancePackageMisma "GTW_w146_performancePackageMismatch";
BA_ "SystemSignalLongSymbol" SG_ 62 GTW_w227_DISPTOUCHversionMismatc "GTW_w227_DISPTOUCHversionMismatch";
BA_ "SystemSignalLongSymbol" SG_ 62 GTW_w229_displaySoftsetConnectio "GTW_w229_displaySoftsetConnection";
BA_ "SystemSignalLongSymbol" SG_ 62 GTW_w273_BLEEPREARLEFTversionMis "GTW_w273_BLEEPREARLEFTversionMismatch";
BA_ "SystemSignalLongSymbol" SG_ 62 GTW_w274_BLEEPREARRIGHTversionMi "GTW_w274_BLEEPREARRIGHTversionMismatch";
BA_ "SystemSignalLongSymbol" SG_ 62 GTW_w277_NonRevCDrMOSMitigationF "GTW_w277_NonRevCDrMOSMitigationFailed";
BA_ "SystemSignalLongSymbol" SG_ 62 GTW_w282_tcuPhyConfigurationFail "GTW_w282_tcuPhyConfigurationFailed";
BA_ "SystemSignalLongSymbol" SG_ 62 GTW_w311_canLogQueueFullBeforeFs "GTW_w311_canLogQueueFullBeforeFsInit";
BA_ "SystemSignalLongSymbol" SG_ 62 GTW_w317_sdCardChkdskRepairFaile "GTW_w317_sdCardChkdskRepairFailed";
BA_ "SystemSignalLongSymbol" SG_ 62 GTW_w322_gestureUnrecognizedFrom "GTW_w322_gestureUnrecognizedFromMoving";
BA_ "SystemSignalLongSymbol" SG_ 62 GTW_w360_RGBDOORFLversionMismatc "GTW_w360_RGBDOORFLversionMismatch";
BA_ "SystemSignalLongSymbol" SG_ 62 GTW_w361_RGBDOORRLversionMismatc "GTW_w361_RGBDOORRLversionMismatch";
BA_ "SystemSignalLongSymbol" SG_ 62 GTW_w362_RGBDOORFRversionMismatc "GTW_w362_RGBDOORFRversionMismatch";
BA_ "SystemSignalLongSymbol" SG_ 62 GTW_w363_RGBDOORRRversionMismatc "GTW_w363_RGBDOORRRversionMismatch";
BA_ "SystemSignalLongSymbol" SG_ 62 GTW_w364_BLEEPCRADLEversionMisma "GTW_w364_BLEEPCRADLEversionMismatch";
BA_ "Confidence" SG_ 838 GTW_autopilotOverrideState 1;
BA_ "Confidence" SG_ 838 GTW_autopilotConfig 1;
BA_ "Confidence" SG_ 838 GTW_autopilotOverrideConfig 1;
BA_ "Confidence" SG_ 838 GTW_autopilotOverrideExpireTime 0;
BA_ "Confidence" SG_ 904 GTW_VEH_canBusActivity 0;
BA_ "Confidence" SG_ 904 GTW_PARTY_canBusActivity 0;
BA_ "Confidence" SG_ 904 GTW_CH_canBusActivity 0;
BA_ "Confidence" SG_ 904 GTW_VEH_txWarning 0;
BA_ "Confidence" SG_ 904 GTW_PARTY_txWarning 0;
BA_ "Confidence" SG_ 904 GTW_CH_txWarning 0;
BA_ "Confidence" SG_ 904 GTW_VEH_rxWarning 0;
BA_ "Confidence" SG_ 904 GTW_PARTY_rxWarning 0;
BA_ "Confidence" SG_ 904 GTW_CH_rxWarning 0;
BA_ "Confidence" SG_ 904 GTW_VEH_faultConfinement 0;
BA_ "Confidence" SG_ 904 GTW_PARTY_faultConfinement 0;
BA_ "Confidence" SG_ 904 GTW_CH_faultConfinement 0;
BA_ "Confidence" SG_ 904 GTW_BDY_canBusActivity 0;
BA_ "Confidence" SG_ 904 GTW_BDY_txWarning 0;
BA_ "Confidence" SG_ 904 GTW_BDY_rxWarning 0;
BA_ "Confidence" SG_ 904 GTW_BDY_faultConfinement 0;
VAL_ 1428 EPASTS_alertID 270 "a270_oscillationCompTrqLimReached" 269 "a269_assistTorqueDisabled" 268 "a268_eacCancelled" 267 "a267_safeSpeedAssist" 266 "a266_overloadProtect" 265 "a265_overheatProtect" 264 "a264_assistTorqueLimited" 263 "a263_espWsStatus" 262 "a262_yawRateStatus" 261 "a261_sccmStatusError" 260 "a260_scoPrivateBusOff" 259 "a259_scoCanBusOff" 258 "a258_pspInvalidProjectParamset" 257 "a257_dcvmUnderVolt" 256 "a256_dcvmOverVolt" 255 "a255_pmState2Mia" 254 "a254_vcFrontMia" 253 "a253_vcFrontCsError" 252 "a252_vcFrontCntError" 251 "a251_uiTuneReqMia" 250 "a250_uiTuneReqCsError" 249 "a249_uiTuneReqCntError" 248 "a248_sccmMia" 247 "a247_sccmCsError" 246 "a246_sccmCntError" 245 "a245_rcmMia" 244 "a244_rcmCsError" 243 "a243_rcmCntError" 242 "a242_gtwConfigMia" 241 "a241_espWsMia" 240 "a240_espWsCsError" 239 "a239_espWsCntError" 238 "a238_espWrMia" 237 "a237_espWrCsError" 236 "a236_espWrCntError" 235 "a235_ecu1StatMia" 234 "a234_ecu1StatCsError" 233 "a233_ecu1StatCntError" 232 "a232_diSpdMia" 231 "a231_diSpdCsError" 230 "a230_diSpdCntError" 229 "a229_dirTorqueMia" 228 "a228_dirTorqueCsError" 227 "a227_dirTorqueCntError" 226 "a226_dasMia" 225 "a225_dasCsError" 224 "a224_dasCntError" 223 "a223_apsMia" 222 "a222_apsCsError" 221 "a221_apsCntError" 220 "a220_transceiverInputqueueOverflow" 219 "a219_frhFastRestartFailed" 218 "a218_aadApplicationStateErr" 217 "a217_msdMasterSilentErr" 216 "a216_isdgImproperShutdown" 215 "a215_vsgSafeViolErr" 214 "a214_velInterfaceErr" 213 "a213_frmHighFrictionDetected" 212 "a212_frmDataLost" 211 "a211_frmInternalErr" 210 "a210_fdrTotalBlocking" 209 "a209_fdrLowSeverityFreezing" 208 "a208_fdrLowSeverityBlocking" 207 "a207_fdrOclFreezing" 206 "a206_fdrOclPartialBlocking" 205 "a205_fdrOclFail" 204 "a204_fdpPrevTrqErr" 203 "a203_ctcInterfaceErr" 202 "a202_ohnvmpStoredOffsetLost" 201 "a201_ammOutputBufferOverflow" 200 "a200_ammInputBufferOverflow" 199 "a199_osumC1StackNearFull" 198 "a198_osumC1CsaNearFull" 197 "a197_difpDifactorInvalid" 196 "a196_topEolTasOffsetInvalid" 195 "a195_imcmCommErrC1" 194 "a194_amNvdataLoss" 193 "a193_osumC0StackNearFull" 192 "a192_osumC0CsaNearFull" 191 "a191_sbcscpVcp2VucVoltFail" 190 "a190_sbchCommBufferOverflow" 189 "a189_sbchCommErrMcuToSbc" 188 "a188_epmCommBufferOverflow" 187 "a187_epmVoltFail" 186 "a186_wdhCommBufferOverflow" 185 "a185_sbcscpQAWatchdogReset" 184 "a184_sbcmCommBufferOverflow" 183 "a183_sbchCommErrSbcToMcu" 182 "a182_mcdInputMia" 181 "a181_dmDeadlineViolationC1" 180 "a180_dmDeadlineViolationC1" 179 "a179_tedMotorcoilTempChecker" 178 "a178_exchWdtException" 177 "a177_etsrInvalidated" 176 "a176_exchCpu1ExceptionReset" 175 "a175_exchFlashStoredConfigErr" 174 "a174_pmpPhasecurrentAge" 173 "a173_pmpRotorspeedAge" 172 "a172_pmpElangMotorcurrentAge" 171 "a171_pmpKgvalueAge" 170 "a170_pmpDcvoltAge" 169 "a169_scpSafetyReset" 168 "a168_c1csInvalidC1App" 167 "a167_iccd1ErrQueueOverflow" 166 "a166_tdaPhasecurrentshuntTempChecker" 165 "a165_tdaDcbusshuntTempChecker" 164 "a164_tdaBattfetjunctionTempChecker" 163 "a163_tdaPowermoduleTempChecker" 162 "a162_tdaBridgefetjunctionTempChecker" 161 "a161_tdaRelayfetjunctionTempChecker" 160 "a160_rsthCpu1UnexpectedAlarm" 159 "a159_exchFlashWordlineTransientErr" 158 "a158_amGduFailDuringRecovery" 157 "a157_mcudcpInvalidEcuId" 156 "a156_amIntSerialErrSafetyReset" 155 "a155_sdsmDataInvalidAll" 154 "a154_sdsmCsErrorInvalidPrimary" 153 "a153_sdsmBlockSelectorInvalid" 152 "a152_exchFlashEccException" 151 "a151_amPermanentEmergencyOffRequested" 150 "a150_amExternalEmergencyOffRequested" 149 "a149_amReversibleEmergencyOffRequested" 148 "a148_mrccExitFromStandbyDetected" 147 "a147_amDcLinkShortedFail" 146 "a146_btarcRcCircuitCheck" 145 "a145_mriPeripheralRaminitFailed" 144 "a144_mriCoreRaminitFailed" 143 "a143_tedEmifilterCmcTempChecker" 142 "a142_tedEmifilterDmcTempChecker" 141 "a141_amFetShortTest" 140 "a140_imcmConfigurationErr" 139 "a139_osehAdditionalOsErr" 138 "a138_osehAdditionalErrWithoutImmReset" 137 "a137_osehErrWithoutImmediateReset" 136 "a136_ftElectricalAngleQf" 135 "a135_tmpsfetjCalculationOverflowErr" 134 "a134_osehGuardedResetAfterErrWithoutReset" 133 "a133_mcusscLbistEcuIdIsNotSupported" 132 "a132_mcusscNotSupportedMcu" 131 "a131_exchGuardedResetAfterPartitionStop" 130 "a130_mrccConfigCsErrorErr" 129 "a129_exchAdditionalExceptionStopRestart" 128 "a128_exchExceptionStopRestart" 127 "a127_exchAdditionalExceptionAfterRst" 126 "a126_mcusscMonbistMiaErr" 125 "a125_mcusscMbistMiaErr" 124 "a124_mcusscMbistEccTransientErr" 123 "a123_imcmCommErr" 122 "a122_pcpBridgeFetShort" 121 "a121_mcusscMbistEccErr" 120 "a120_mcusscFlashEccLatentErr" 119 "a119_mcusscFlashEccCriticalErr" 118 "a118_mcusscFlashCsErrorErr" 117 "a117_mrccStartupRegCsErrorTransientErr" 116 "a116_mrccStartupRegCsErrorStaticErr" 115 "a115_mcusscLbistSingleFail" 114 "a114_osehOsErr" 113 "a113_rsthUncorrectableEndToEndBusErr" 112 "a112_rsthSafetyFlipflopErr" 111 "a111_amCurrentSensingDisconnection" 110 "a110_amPhaseRelaySwitchOffTest" 109 "a109_exhaSysBusOrPeriphErrException" 108 "a108_exhaInternalProtectionException" 107 "a107_exhaOtherNmiException" 106 "a106_exhaSpbBusErrException" 105 "a105_exhaSriBusErrException" 104 "a104_exhaBusMpuException" 103 "a103_exhaUnusedInterruptCallException" 102 "a102_amPhasecurrentQosErr" 101 "a101_sdrvSpcIdMismatch" 100 "a100_amVbrgLssFault" 99 "a099_mcdTorqueMismatchFault" 98 "a098_invErr" 97 "a097_rppRpsMultipleStaticFail" 96 "a096_rppRpsSingleStaticFail" 95 "a095_mdModelBasedMotorIntegrityCheck" 94 "a094_sctpTsuMultipleStaticFail" 93 "a093_sctpTsuSingleStaticFail" 92 "a092_amGduSwitchOffTestBySbc" 91 "a091_bvpBattVoltCrossChkFailed" 90 "a090_etsmWarning" 89 "a089_tedRevercebattfetjunctionTempChecker" 88 "a088_tedMainboardTempChecker" 87 "a087_rsthFlashConfigErr" 86 "a086_rsthRamUncorrEcc" 85 "a085_amGduSwitchOffTestByMcu" 84 "a084_adcTriggerCheck" 83 "a083_tdaDclinkcapacitorTempChecker" 82 "a082_adcTriggerTimeChk" 81 "a081_exchFloatingPointException" 80 "a080_pwmTimerSyncCheck" 79 "a079_gduhComErr" 78 "a078_dmDeadlineViolation" 77 "a077_dmDeadlineViolation" 76 "a076_exchGeneralException" 75 "a075_rsthUnusedOtherModuleAlarm" 74 "a074_rsthUnexpectedAlarm" 73 "a073_rsthOtherEdcEcc" 72 "a072_rsthFlashUncorrEccOrOvfl" 71 "a071_rsthInternalHighVolt" 70 "a070_rsthInternalLowVolt" 69 "a069_rsthCoreTempOutOfRangeHwCheck" 68 "a068_rsthCoreRedundancyErr" 67 "a067_tspmPowermoduleTempImplausible" 66 "a066_amVoltQfErr" 65 "a065_amGduJuncTemp" 64 "a064_amBridgeShort" 63 "a063_amIntRegulatorErr" 62 "a062_amPhaseBridgeCheck" 61 "a061_amIntSerialErr" 60 "a060_amGduFail" 59 "a059_amStartupTestFailed" 58 "a058_amIntVgsUndervtgErr" 57 "a057_amGduVds" 56 "a056_amGduConfigCsErrorCheck" 55 "a055_amExtendedGduTest" 54 "a054_adcUnexpectedData" 53 "a053_adcUnexpectedNumOfData" 52 "a052_ermSdcInputBufferOverflow" 51 "a051_ermMessageErr" 50 "a050_erlErr" 49 "a049_epmLgFail" 48 "a048_epmVcpVoltFail" 47 "a047_epmVregVoltFail" 46 "a046_mcusscOscillatorNotReliable" 45 "a045_psumSbcBandgapVoltErr" 44 "a044_sbcmSbcEepromFail" 43 "a043_sbcmWdStateDisabled" 42 "a042_wdhWdTestFail" 41 "a041_imcmCoreConfigurationMismatch" 40 "a040_swrhLimitedResetRetriesExpired" 39 "a039_csohCh2CsErrorErrAtReset" 38 "a038_csohCh1CsErrorErrAtReset" 37 "a037_epmV5P2Fail" 36 "a036_sbcmSbcBistFailed" 35 "a035_sbchChipIdFail" 34 "a034_sbchReadbackRegFail" 33 "a033_icsvcPswVersionMismatch" 32 "a032_eolpEolCheckFailed" 31 "a031_pmsProductionModeFailed" 30 "a030_rsthClockReset" 29 "a029_smuhSmuCoreCntErrorTestFail" 28 "a028_smuhNonInitDataCorruption" 27 "a027_mcusscDmuHfErr" 26 "a026_mrccCsErrorCheckFail" 25 "a025_btarcCorruptionCheck" 24 "a024_srhCsErrorCheckFail" 23 "a023_btarcCorruptionCheck" 22 "a022_swrhSwResetInfoCorruptionCheck" 21 "a021_osehCsErrorCheck" 20 "a020_mcusscEolEcuIdIntegritiyFail" 19 "a019_rsthHwResetInfoCorruptionCheck" 18 "a018_exchCsErrorCheck" 17 "a017_stmdStmPlausibilityCheckErr" 16 "a016_mcufcCsErrorCheckFail" 15 "a015_mcusscCsErrorCheckFail" 14 "a014_mcusscSffMonitoringMia" 13 "a013_mcusscSffMonitoringFailed" 12 "a012_mcusscMbistEccErr" 11 "a011_mcusscMonbistErr" 10 "a010_svcIncompatibleSwVersions" 9 "a009_mcusscLbistPermanentFail" 8 "a008_psdcPlatformShutdown" 7 "a007_tsmcCoreTempDiff" 6 "a006_swrhResetByInvalidErrid" 5 "a005_scpUnknownResetSource" 4 "a004_scpInputMia" 3 "a003_pspInvalidParamset" 2 "a002_adcMuxErr" 1 "a001_adcCalibrationOrInitFail" 0 "ALERT_DO_NOT_USE_ZERO" ;
VAL_ 1428 EPASTS_alertState 1 "SET" 0 "CLEARED" ;
VAL_ 1428 EPASTS_a264_degradedECU 3 "BOTH_ECU_SIDES" 2 "OTHER_ECU_SIDE" 1 "OWN_ECU_SIDE" 0 "NONE" ;
VAL_ 1428 EPASTS_a264_ownSideDegradationRe 92 "DC_LINK_CAPACITOR_HOTSPOTCASEDIFF_TEMPERATURE" 84 "PHASECURRENT_SHUNT_TEMPERATURE_MOMENTARY" 80 "DC_LINK_CAPACITOR_TEMPERATURE" 52 "EMIFILTER_DMC_TEMPERATURE" 48 "EMIFILTER_CMC_TEMPERATURE" 44 "DCLINK_SHUNT_TEMPERATURE" 40 "PHASECURRENT_SHUNT_TEMPERATURE" 36 "POWER_MODULE_TEMPERATURE" 32 "MOTOR_COIL_TEMPERATURE" 28 "BATTERY_FET_JUNCTION_TEMPERATURE" 24 "MAIN_BOARD_TEMPERATURE" 20 "REVERSE_BATTERY_FET_JUNCTION_TEMPERATURE" 12 "RELAY_FET_JUNCTION_TEMPERATURE" 8 "BRIDGE_FET_JUNCTION_TEMPERATURE" 4 "CORE1_DEGRADATION" 0 "NO_DEGRADATION_ON_THIS_ECU_SIDE" ;
VAL_ 1428 EPASTS_a264_otherSideDegradation 92 "DC_LINK_CAPACITOR_HOTSPOTCASEDIFF_TEMPERATURE" 84 "PHASECURRENT_SHUNT_TEMPERATURE_MOMENTARY" 80 "DC_LINK_CAPACITOR_TEMPERATURE" 52 "EMIFILTER_DMC_TEMPERATURE" 48 "EMIFILTER_CMC_TEMPERATURE" 44 "DCLINK_SHUNT_TEMPERATURE" 40 "PHASECURRENT_SHUNT_TEMPERATURE" 36 "POWER_MODULE_TEMPERATURE" 32 "MOTOR_COIL_TEMPERATURE" 28 "BATTERY_FET_JUNCTION_TEMPERATURE" 24 "MAIN_BOARD_TEMPERATURE" 20 "REVERSE_BATTERY_FET_JUNCTION_TEMPERATURE" 12 "RELAY_FET_JUNCTION_TEMPERATURE" 8 "BRIDGE_FET_JUNCTION_TEMPERATURE" 4 "CORE1_DEGRADATION" 0 "NO_DEGRADATION_ON_THIS_ECU_SIDE" ;
VAL_ 1428 EPASTS_a265_degradedECU 3 "BOTH_ECU_SIDES" 2 "OTHER_ECU_SIDE" 1 "OWN_ECU_SIDE" 0 "NONE" ;
VAL_ 1428 EPASTS_a267_velocityEstimatorSta 5 "BACKUP_MOTOR" 4 "BACKUP_WHEELS_B" 3 "BACKUP_WHEELS_A" 2 "WHEELS_REDUCED" 1 "WHEELS_NORMAL" 0 "NOT_INITIALIZED" ;
VAL_ 920 EPASTS_matrixIndex 4 "AlertMatrix4" 3 "AlertMatrix3" 2 "AlertMatrix2" 1 "AlertMatrix1" 0 "AlertMatrix0" ;
VAL_ 282 GTW_BKP_BATT_MON 4095 "SNA" ;
VAL_ 282 GTW_BKP_BATT_NTC_P 4095 "SNA" ;
VAL_ 282 GTW_ECALL_GPS_ANT_BIAS 4095 "SNA" ;
VAL_ 282 GTW_ECALL_MIC_DIAG 4095 "SNA" ;
VAL_ 282 GTW_SOS_ECALL_nRQST_BUF 4095 "SNA" ;
VAL_ 1384 GTW_alertID 414 "a414_socHeldInReset" 410 "a410_unexpectedResetCause2" 409 "a409_unexpectedResetCause" 400 "a400_ethlSwitchOTPIncorrect" 399 "a399_ethIfRxTcpipQueueDrop" 398 "a398_awakeForExtendedTime" 397 "a397_alreadyInDrive" 396 "a396_alreadyInReverse" 395 "a395_lwipIcmpError" 393 "a393_osdSramCrcMismatch" 391 "a391_adspMacAddrCheckFailed" 389 "a389_rcmEventDetected" 388 "a388_adspWatchdogSkipped" 387 "a387_externalRtcReadFailure" 386 "a386_RCUCALversionMismatch" 385 "a385_RCUversionMismatch" 384 "a384_IDBCALversionMismatch" 383 "a383_IDB1versionMismatch" 382 "a382_IDBversionMismatch" 381 "a381_DPBCALversionMismatch" 380 "a380_DPBversionMismatch" 376 "a376_blFailedToExecBootImg" 366 "a366_uiGearRequestMismatch" 364 "a364_BLEEPCRADLEversionMismatch" 363 "a363_RGBDOORRRversionMismatch" 362 "a362_RGBDOORFRversionMismatch" 361 "a361_RGBDOORRLversionMismatch" 360 "a360_RGBDOORFLversionMismatch" 359 "a359_RGBIPFRversionMismatch" 358 "a358_RGBIPFLversionMismatch" 356 "a356_touchGPIOStatusCheck" 355 "a355_EPASTSversionMismatch" 354 "a354_EPASTPversionMismatch" 353 "a353_sASILStatusCheck" 352 "a352_mASILStatusCheck" 351 "a351_sOSDCrcCheck" 350 "a350_mOSDCrcCheck" 349 "a349_VCBLDCPBversionMismatch" 348 "a348_VCBLDCFversionMismatch" 342 "a342_VCBLDCPPversionMismatch" 336 "a336_possibleCanTxIssue" 334 "a334_hrlFolderSpaceLow" 332 "a332_unknownDisplayPN" 331 "a331_SWSRversionMismatch" 330 "a330_SWSLversionMismatch" 329 "a329_FOHMversionMismatch" 328 "a328_smartShiftDisabled" 323 "a323_gestureStartOutOfStrip" 322 "a322_gestureUnrecognizedFromMoving" 317 "a317_sdCardChkdskRepairFailed" 316 "a316_sdCardChkdskRepair" 314 "a314_canLogBlockWriteErr" 313 "a313_OSDActive" 312 "a312_hrlFileIncomplete" 311 "a311_canLogQueueFullBeforeFsInit" 309 "a309_VCUSBversionMismatch" 282 "a282_tcuPhyConfigurationFailed" 281 "a281_likelyMissedPoke" 280 "a280_hrlFrameDropped" 279 "a279_adspRepeatedWatchdog" 278 "a278_ethSwitchCongested" 277 "a277_NonRevCDrMOSMitigationFailed" 276 "a276_VDDSOC_DrMOS_Fault" 275 "a275_VDDCORE_DrMOS_Fault" 274 "a274_BLEEPREARRIGHTversionMismatch" 273 "a273_BLEEPREARLEFTversionMismatch" 268 "a268_stoMIA" 267 "a267_dpp2MIA" 266 "a266_dpp1MIA" 265 "a265_optionFlagsError" 264 "a264_hrlPseudoFileAvail" 263 "a263_hrlUdpFileAvail" 262 "a262_canLogBlockDropped" 261 "a261_adspWatchdog" 260 "a260_unknownPN" 255 "a255_rtc32KHzWatchdog" 246 "a246_touchcoreHeartbeat" 245 "a245_apsNotDisabled" 244 "a244_SDCRversionMismatch" 230 "a230_touchInterruptStorm" 229 "a229_displaySoftsetConnection" 228 "a228_DISPOSDversionMismatch" 227 "a227_DISPTOUCHversionMismatch" 226 "a226_DISPversionMismatch" 225 "a225_resetOnSleepWake" 224 "a224_sdCardUpgradeNeeded" 223 "a223_LVBMSversionMismatch" 219 "a219_CMPSversionMismatch" 218 "a218_switchOTPIncorrect" 186 "a186_swrPrecaution" 176 "a176_TPMShardWarnRearRight" 175 "a175_TPMShardWarnRearLeft" 174 "a174_TPMShardWarnFrontRight" 173 "a173_TPMShardWarnFrontLeft" 172 "a172_TPMSsoftWarnRearRight" 171 "a171_TPMSsoftWarnRearLeft" 170 "a170_TPMSsoftWarnFrontRight" 169 "a169_TPMSsoftWarnFrontLeft" 168 "a168_nErrCanFaultParty" 167 "a167_nErrCanFaultCh" 166 "a166_nErrCanFaultVeh" 165 "a165_USMversionMismatch" 155 "a155_PMversionMismatch" 153 "a153_externalRtcAlarmFailure" 151 "a151_HCM3RversionMismatch" 150 "a150_HCM3LversionMismatch" 149 "a149_rtcTimeSetInPast" 147 "a147_updateAbortFor12v" 146 "a146_performancePackageMismatch" 145 "a145_carConfigsNotWritten" 144 "a144_hrlStateMachine" 143 "a143_possibleCanWakeIssue" 141 "a141_teleCANETHis" 140 "a140_cancoreHeartbeat" 139 "a139_CMPDversionMismatch" 138 "a138_sdCardEndOfLife" 137 "a137_lowHeap" 136 "a136_hrlGameModeFileAvail" 135 "a135_canLogQueueFull" 134 "a134_disableFeatureFailed" 133 "a133_adspFaultDetected" 129 "a129_ICRversionMismatch" 127 "a127_noFilePointersAvailable" 125 "a125_switchReplayUnlocked" 123 "a123_BDYbusOverloaded" 122 "a122_BDY_canFault" 120 "a120_switchUnlocked" 118 "a118_unexpectedFunctionalResetStatus" 117 "a117_unexpectedDestructiveResetStatus" 116 "a116_switchInitFailed" 115 "a115_hrlEventFileAvail" 114 "a114_updtRetried" 113 "a113_unrecognizedCanMessage" 112 "a112_z4bDisabled" 111 "a111_writeMdioFailed" 110 "a110_readMdioFailed" 109 "a109_failedToStartUpdater" 108 "a108_BLEEPREARversionMismatch" 107 "a107_BLEEPRIGHTversionMismatch" 106 "a106_BLEEPLEFTversionMismatch" 105 "a105_eBuckConfigured" 104 "a104_sdCardDriverArgCorrupted" 103 "a103_sdCardFormatted" 101 "a101_switchWatchdog" 100 "a100_CBCversionMismatch" 99 "a099_SWCversionMismatch" 98 "a098_HCMRversionMismatch" 97 "a097_HCMLversionMismatch" 96 "a096_sdCardFatCorrupted" 95 "a095_sdCardFull" 94 "a094_sdCardInvReqOverflowCount" 93 "a093_sdCardInvReqOverflowBase" 92 "a092_sdCardInvReqZero" 91 "a091_lowStack" 90 "a090_ocuFailed" 89 "a089_sdCardWatchdog" 88 "a088_sdCardInvReqParallel" 87 "a087_ocuInProgress" 86 "a086_ocu" 84 "a084_canFrameDropped" 83 "a083_udsMsgDroppedByTcpStack" 82 "a082_sdCardBSCorrupted" 81 "a081_udsMessageRejected" 80 "a080_CHbusOverloaded" 79 "a079_PARTYbusOverloaded" 78 "a078_VEHbusOverloaded" 77 "a077_bmpPmicError" 76 "a076_ethInterfaceReset" 75 "a075_epas3sMIA" 74 "a074_epas3pMIA" 73 "a073_steeringWheelReset" 72 "a072_updateFailure" 71 "a071_hrlTrigger" 70 "a070_hrlDump" 69 "a069_diskioErr" 68 "a068_prodKeyMissing" 67 "a067_tcpDebug" 66 "a066_exception" 65 "a065_PARTY_canFault" 64 "a064_CH_canFault" 63 "a063_VEH_canFault" 62 "a062_bmpWatchdog" 61 "a061_bmpSleepFailure" 60 "a060_unFused" 59 "a059_inFactoryMode" 58 "a058_rtcAlarmFailure" 57 "a057_i2cFailure" 55 "a055_OPCFversionMismatch" 54 "a054_OPCRversionMismatch" 53 "a053_busSleepFailure" 52 "a052_ifTxSpans" 51 "a051_sdCardFileSystemFailure" 50 "a050_sdCardInitFailure" 49 "a049_corruptedManifest" 48 "a048_EPAS3SversionMismatch" 47 "a047_VCRIGHTversionMismatch" 46 "a046_VCLEFTversionMismatch" 45 "a045_VCFRONTversionMismatch" 43 "a043_THSversionMismatch" 42 "a042_TASversionMismatch" 41 "a041_VCSECversionMismatch" 40 "a040_SCCMversionMismatch" 39 "a039_RCMCALversionMismatch" 38 "a038_RCMversionMismatch" 37 "a037_RADCversionMismatch" 36 "a036_PTCversionMismatch" 35 "a035_PMFversionMismatch" 34 "a034_PMRversionMismatch" 33 "a033_PCSCPU2versionMismatch" 32 "a032_PCSversionMismatch" 31 "a031_PARKversionMismatch" 30 "a030_OCS1PversionMismatch" 29 "a029_IBSTCALversionMismatch" 28 "a028_IBSTversionMismatch" 27 "a027_HVPversionMismatch" 26 "a026_GTWversionMismatch" 25 "a025_ESPCALversionMismatch" 24 "a024_ESPversionMismatch" 23 "a023_EPBRversionMismatch" 22 "a022_EPBLversionMismatch" 21 "a021_EPAS3PversionMismatch" 20 "a020_DIRversionMismatch" 19 "a019_CPversionMismatch" 18 "a018_CMPversionMismatch" 17 "a017_BMSversionMismatch" 16 "a016_BLEEPCENTERversionMismatch" 15 "a015_DIFversionMismatch" 14 "a014_APSversionMismatch" 12 "a012_maincoreWatchdog" 11 "a011_cancoreWatchdog" 10 "a010_wdTaskCount" 9 "a009_lateTask" 8 "a008_ifPbufAllocError" 7 "a007_ifRxBufError" 6 "a006_ifTxOutputFull" 5 "a005_stackOverflowHook" 4 "a004_mallocHook" 3 "a003_logWriteRecord" 2 "a002_taskError" 1 "a001_canEthTxQueue" 0 "ALERT_DO_NOT_USE_ZERO" ;
VAL_ 1384 GTW_alertState 1 "SET" 0 "CLEARED" ;
VAL_ 1384 GTW_a049_headerError 3 "HEADER_READ_FAIL" 2 "MUID_LIST_UNEXPECTED" 1 "HEADER_INFO_BAD" 0 "HEADER_OK" ;
VAL_ 1384 GTW_a062_bmpWatchdogReason 2 "WAKE_FAILURE" 1 "RUNTIME_FAILURE" 0 "WATCHDOG_NONE" ;
VAL_ 1384 GTW_a063_VEH_faultConfinement 2 "BUS_OFF" 1 "ERROR_PASSIVE" 0 "ERROR_ACTIVE" ;
VAL_ 1384 GTW_a064_CH_faultConfinement 2 "BUS_OFF" 1 "ERROR_PASSIVE" 0 "ERROR_ACTIVE" ;
VAL_ 1384 GTW_a065_PARTY_faultConfinement 2 "BUS_OFF" 1 "ERROR_PASSIVE" 0 "ERROR_ACTIVE" ;
VAL_ 1384 GTW_a077_bmpPmicErrorType 4 "INTERNAL_SM" 3 "OT" 2 "MEM_CORRUPT" 1 "OC_OV_CC" 0 "NONE" ;
VAL_ 1384 GTW_a081_ISOTPmsgType 3 "FLOW" 2 "CONSECUTIVE" 1 "FIRST" 0 "SINGLE" ;
VAL_ 1384 GTW_a081_udsSID 536870912 "MAX_VALUE" 16384 "ECU_RESET_SOFT" 8192 "ECU_RESET_KEY_OFF_ON" 4096 "ECU_RESET_HARD" 2048 "PING_TP" 1024 "DSC_EXTDS" 512 "SA" 256 "RQTE" 128 "TRD" 64 "RQUL" 32 "RQDL" 16 "RC_RRR" 8 "RC_STPR" 4 "RC_STR" 2 "WDBI" 1 "RBDI" ;
VAL_ 1384 GTW_a122_BDY_faultConfinement 2 "BUS_OFF" 1 "ERROR_PASSIVE" 0 "ERROR_ACTIVE" ;
VAL_ 1384 GTW_a261_failureReason 6 "INCORRECT_TYPE" 5 "INCORRECT_SEQ_NO" 4 "INCORRECT_ID" 3 "INCORRECT_ADDRESS" 2 "INCORRECT_LENGTH" 1 "RECEIVE_ERROR" 0 "NO_ERROR" ;
VAL_ 1384 GTW_a277_mitigationFailureReason 7 "FAILED_NVRAM_WRITE" 6 "FAILED_NVRAM_WRITE_PROTECTED" 5 "FAILED_REGISTERS_WRITE_PROTECTED" 4 "FAILED_REGISTER_WRITE" 3 "FAILED_REGISTER_READ" 2 "FAILED_ICE_NOT_AWAKE" 1 "NOT_NEEDED" 0 "APPLIED_SUCCESSFULLY" ;
VAL_ 1384 GTW_a279_failureReason 6 "INCORRECT_TYPE" 5 "INCORRECT_SEQ_NO" 4 "INCORRECT_ID" 3 "INCORRECT_ADDRESS" 2 "INCORRECT_LENGTH" 1 "RECEIVE_ERROR" 0 "NO_ERROR" ;
VAL_ 1384 GTW_a317_status 7 "MASK" 4 "PARTIAL" 3 "FAILED" 2 "SUCCESS" 1 "NOT_NEEDED" ;
VAL_ 1384 GTW_a317_errorCode 19 "FS_INFO_INVALID_SIG" 18 "FS_INFO_SECTOR_NOT_FOUND" 17 "FS_INFO_READ_FAILED" 16 "FS_INFO_WRITE_FAILED" 15 "INVALID_CLUSTER" 14 "DIR_TOO_DEEP" 13 "UNKNOWN_FS" 12 "CLUSTER_IN_USE" 11 "FAT_MISMATCHED" 10 "FAT_READ_FAILED" 9 "FAT_WRITE_FAILED" 8 "NOT_FAT32" 7 "BAD_SECTOR_SIZE" 6 "BR_READ_FAILED" 5 "MBR_READ_FAILED" 4 "DISK_INIT_FAILED" 3 "INSUFFICIENT_MEMORY" 2 "ERROR_FOUND_FIXED" 1 "ERROR_FOUND" 0 "NO_ERROR" ;
VAL_ 62 GTW_matrixIndex 6 "AlertMatrix6" 5 "AlertMatrix5" 4 "AlertMatrix4" 3 "AlertMatrix3" 2 "AlertMatrix2" 1 "AlertMatrix1" 0 "AlertMatrix0" ;
VAL_ 838 GTW_autopilotOverrideState 3 "TIMEBOUND_SUBSCRIPTION" 2 "TRIAL" 1 "SUBSCRIPTION" 0 "BASE" ;
VAL_ 838 GTW_autopilotConfig 4 "BASIC" 3 "SELF_DRIVING" 2 "ENHANCED" 1 "HIGHWAY" 0 "NONE" ;
VAL_ 838 GTW_autopilotOverrideConfig 4 "BASIC" 3 "SELF_DRIVING" 2 "ENHANCED" 1 "HIGHWAY" 0 "NONE" ;
VAL_ 904 GTW_VEH_faultConfinement 2 "BUS_OFF" 1 "ERROR_PASSIVE" 0 "ERROR_ACTIVE" ;
VAL_ 904 GTW_PARTY_faultConfinement 2 "BUS_OFF" 1 "ERROR_PASSIVE" 0 "ERROR_ACTIVE" ;
VAL_ 904 GTW_CH_faultConfinement 2 "BUS_OFF" 1 "ERROR_PASSIVE" 0 "ERROR_ACTIVE" ;
VAL_ 904 GTW_BDY_faultConfinement 2 "BUS_OFF" 1 "ERROR_PASSIVE" 0 "ERROR_ACTIVE" ;
